VERSION ""

NS_ :

BS_:

BU_: WPC2 PSB SHVU_RR vHS_B2 FCS EMCU SLB GW_APSU GW_DLBCU RCM ARS CGW_CCU vDummy_HS_B GW_RLPSU ATS RLHV SGU PFSU GW_RRPSU ALBCU DSAU SWRC SHVU_FR RCS GW_DPSU BLTN_CAM SCM OHCL RWPC RRHV WPC HOD ASAU

BO_ 905 SBCM_RR_01_200ms: 8 CGW_CCU
 SG_ SBCM_RR_Crc1Val : 0|8@1+ (1,0) [0|0] ""  Vector__XXX
 SG_ RR_CrashUnlockCmd : 10|1@1+ (1,0) [0|0] ""  BLTN_CAM
 SG_ SBCM_RR_AlvCnt1Val : 12|4@1+ (1,0) [0|0] ""  Vector__XXX
 SG_ Warn_RrRtDrSwSta_SBCM : 16|2@1+ (1,0) [0|0] ""  ATS,BLTN_CAM,GW_APSU,GW_RLPSU,GW_RRPSU,RWPC,WPC,WPC2
 SG_ DoorLock_RrRtDrUnLkSta_SBCM : 18|2@1+ (1,0) [0|0] ""  ATS
 SG_ RR_SEAActivated : 20|2@1+ (1,0) [0|0] ""  Vector__XXX
 SG_ RR_SEAWarn : 22|2@1+ (1,0) [0|0] ""  Vector__XXX
 SG_ RR_SEWWarn : 24|2@1+ (1,0) [0|0] ""  Vector__XXX
 SG_ RR_ReleaseWarn : 26|2@1+ (1,0) [0|0] ""  Vector__XXX
 SG_ RR_SWFailAlarm : 28|2@1+ (1,0) [0|0] ""  Vector__XXX
 SG_ RR_ChildLock_ActnFlSta : 30|2@1+ (1,0) [0|0] ""  Vector__XXX
 SG_ RR_MRActivationAlarm : 32|2@1+ (1,0) [0|0] ""  Vector__XXX
 SG_ RR_ChildLock_Status : 34|2@1+ (1,0) [0|0] ""  Vector__XXX
 SG_ USM_RRGhostDoorSta : 36|2@1+ (1,0) [0|0] ""  Vector__XXX
 SG_ DoorLock_PDSLkSwSta_RR : 40|2@1+ (1,0) [0|0] ""  Vector__XXX
 SG_ PDS_TypeOption_RR : 42|2@1+ (1,0) [0|0] ""  Vector__XXX
 SG_ RRDoorPushAlarm : 8|2@1+ (1,0) [0|0] ""  Vector__XXX

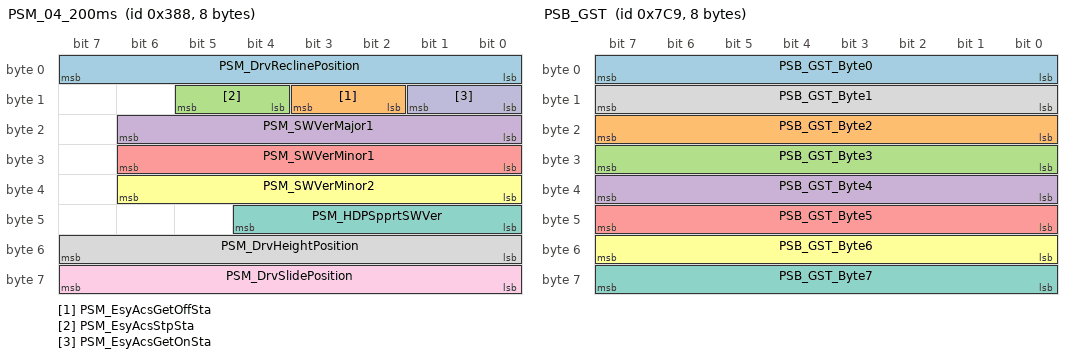
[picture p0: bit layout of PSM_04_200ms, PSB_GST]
BO_ 904 PSM_04_200ms: 8 GW_DPSU
 SG_ PSM_DrvReclinePosition : 0|8@1+ (1,0) [0|0] ""  CGW_CCU,GW_RLPSU,GW_RRPSU
 SG_ PSM_EsyAcsGetOffSta : 10|2@1+ (1,0) [0|0] ""  DSAU,GW_DLBCU,GW_RLPSU,GW_RRPSU
 SG_ PSM_EsyAcsStpSta : 12|2@1+ (1,0) [0|0] ""  DSAU,GW_DLBCU,GW_RLPSU,GW_RRPSU
 SG_ PSM_SWVerMajor1 : 16|7@1+ (1,0) [0|0] ""  CGW_CCU
 SG_ PSM_SWVerMinor1 : 24|7@1+ (1,0) [0|0] ""  CGW_CCU
 SG_ PSM_SWVerMinor2 : 32|7@1+ (1,0) [0|0] ""  CGW_CCU
 SG_ PSM_HDPSpprtSWVer : 40|5@1+ (1,0) [0|0] ""  CGW_CCU
 SG_ PSM_DrvHeightPosition : 48|8@1+ (1,0) [0|0] ""  CGW_CCU,GW_RLPSU,GW_RRPSU
 SG_ PSM_DrvSlidePosition : 56|8@1+ (2,0) [0|0] ""  CGW_CCU,GW_RLPSU,GW_RRPSU
 SG_ PSM_EsyAcsGetOnSta : 8|2@1+ (1,0) [0|0] ""  DSAU,GW_DLBCU,GW_RLPSU,GW_RRPSU

BO_ 903 PSM_03_200ms: 8 GW_DPSU
 SG_ PSM_DrvStSldFwdDis : 0|2@1+ (1,0) [0|0] ""  CGW_CCU
 SG_ PSM_DrvStTiltDnDis : 10|2@1+ (1,0) [0|0] ""  CGW_CCU
 SG_ PSM_DrvStHghtUpDis : 12|2@1+ (1,0) [0|0] ""  CGW_CCU
 SG_ PSM_DrvStHghtDnDis : 14|2@1+ (1,0) [0|0] ""  CGW_CCU
 SG_ PSM_DrvStCushExtBckwdDis : 16|2@1+ (1,0) [0|0] ""  CGW_CCU
 SG_ PSM_DrvStCushExtFwdDis : 18|2@1+ (1,0) [0|0] ""  CGW_CCU
 SG_ PSM_DrvStSldBckwdDis : 2|2@1+ (1,0) [0|0] ""  CGW_CCU
 SG_ PSM_DrvStHdRstUpDis : 20|2@1+ (1,0) [0|0] ""  CGW_CCU
 SG_ PSM_DrvStHdRstDnDis : 22|2@1+ (1,0) [0|0] ""  CGW_CCU
 SG_ PSM_DrvStHdRstFwdDis : 24|2@1+ (1,0) [0|0] ""  CGW_CCU
 SG_ PSM_DrvStHdRstBckwdDis : 26|2@1+ (1,0) [0|0] ""  CGW_CCU
 SG_ PSM_DrvStLmbrDefDis : 32|2@1+ (1,0) [0|0] ""  CGW_CCU
 SG_ PSM_DrvStLmbrLoDis : 34|2@1+ (1,0) [0|0] ""  CGW_CCU
 SG_ PSM_DrvStLmbrMdlDis : 36|2@1+ (1,0) [0|0] ""  CGW_CCU
 SG_ PSM_DrvStLmbrUpDis : 38|2@1+ (1,0) [0|0] ""  CGW_CCU
 SG_ PSM_DrvStReclneFwdDis : 4|2@1+ (1,0) [0|0] ""  CGW_CCU
 SG_ PSM_DrvStBlstrDefDis : 40|2@1+ (1,0) [0|0] ""  CGW_CCU
 SG_ PSM_DrvStBlstrInfDis : 42|2@1+ (1,0) [0|0] ""  CGW_CCU
 SG_ PSM_DrvStReclneBckwdDis : 6|2@1+ (1,0) [0|0] ""  CGW_CCU
 SG_ PSM_DrvStTiltUpDis : 8|2@1+ (1,0) [0|0] ""  CGW_CCU

BO_ 902 PSM_02_200ms: 8 GW_DPSU
 SG_ PSM_DrvStEsyAcsUSMSta : 0|3@1+ (1,0) [0|0] ""  CGW_CCU,DSAU,GW_DLBCU
 SG_ PSM_SeatPosPlyBck_Sta : 10|3@1+ (1,0) [0|0] ""  GW_RLPSU
 SG_ PSM_SeatPos_Sta : 13|3@1+ (1,0) [0|0] ""  GW_RLPSU
 SG_ PSM_SeatPosSldLmt_Sta : 16|2@1+ (1,0) [0|0] ""  CGW_CCU
 SG_ PSM_SeatPosRclnLmt_Sta : 18|2@1+ (1,0) [0|0] ""  CGW_CCU
 SG_ SmrtIMS_StatureRspVal : 24|4@1+ (1,0) [0|0] ""  CGW_CCU
 SG_ SmrtIMS_SeatedHghtRspVal : 28|4@1+ (1,0) [0|0] ""  CGW_CCU
 SG_ Drv_2ndAutoFldEnable : 3|2@1+ (1,0) [0|0] ""  GW_RLPSU,GW_RRPSU
 SG_ SmrtIMS_WghtRspVal : 32|4@1+ (1,0) [0|0] ""  CGW_CCU
 SG_ SmartIMS_DisReq : 36|3@1+ (1,0) [0|0] ""  CGW_CCU
 SG_ SmrtIMS_ExitSta : 40|3@1+ (1,0) [0|0] ""  CGW_CCU
 SG_ PSM_DrvStRlxTiltUpDis : 43|2@1+ (1,0) [0|0] ""  CGW_CCU
 SG_ PSM_DrvStRlxTiltDnDis : 45|2@1+ (1,0) [0|0] ""  CGW_CCU
 SG_ PSM_DrvStLegUpDis : 47|2@1+ (1,0) [0|0] ""  CGW_CCU
 SG_ PSM_DrvStLegDnDis : 49|2@1+ (1,0) [0|0] ""  CGW_CCU
 SG_ Drv_2ndStAutoRlxEnable : 57|2@1+ (1,0) [0|0] ""  GW_RLPSU,GW_RRPSU
 SG_ Drv_AutoRlxSta : 59|2@1+ (1,0) [0|0] ""  CGW_CCU,GW_RLPSU,GW_RRPSU
 SG_ Drv_AutoReturnSta : 61|2@1+ (1,0) [0|0] ""  CGW_CCU
 SG_ PSM_IMSOptTyp : 8|2@1+ (1,0) [0|0] ""  CGW_CCU

BO_ 1993 PSB_GST: 8 PSB
 SG_ PSB_GST_Byte0 : 0|8@1+ (1,0) [0|0] ""  CGW_CCU
 SG_ PSB_GST_Byte2 : 16|8@1+ (1,0) [0|0] ""  CGW_CCU
 SG_ PSB_GST_Byte3 : 24|8@1+ (1,0) [0|0] ""  CGW_CCU
 SG_ PSB_GST_Byte4 : 32|8@1+ (1,0) [0|0] ""  CGW_CCU
 SG_ PSB_GST_Byte5 : 40|8@1+ (1,0) [0|0] ""  CGW_CCU
 SG_ PSB_GST_Byte6 : 48|8@1+ (1,0) [0|0] ""  CGW_CCU
 SG_ PSB_GST_Byte7 : 56|8@1+ (1,0) [0|0] ""  CGW_CCU
 SG_ PSB_GST_Byte1 : 8|8@1+ (1,0) [0|0] ""  CGW_CCU

BO_ 1016 HU_GNSS_14_1000ms: 8 CGW_CCU
 SG_ GNSS_MM_type : 0|4@1+ (1,0) [0|0] ""  BLTN_CAM

BO_ 1019 HU_MOOD_E_01: 8 CGW_CCU
 SG_ HU_MoodTherapyDrSeat : 0|2@1+ (1,0) [0|0] ""  DSAU,GW_DLBCU
 SG_ HU_VitalityFragrance : 10|2@1+ (1,0) [0|0] ""  Vector__XXX
 SG_ HU_VitalityCurtain : 12|2@1+ (1,0) [0|0] ""  Vector__XXX
 SG_ HU_DelightMoodLamp : 14|2@1+ (1,0) [0|0] ""  Vector__XXX
 SG_ HU_DelightFragrance : 16|2@1+ (1,0) [0|0] ""  Vector__XXX
 SG_ HU_DelightCurtain : 18|2@1+ (1,0) [0|0] ""  Vector__XXX
 SG_ HU_MoodTherapyPsSeat : 2|2@1+ (1,0) [0|0] ""  ALBCU,ASAU
 SG_ HU_CareMoodLamp : 20|2@1+ (1,0) [0|0] ""  Vector__XXX
 SG_ HU_CareFragrance : 22|2@1+ (1,0) [0|0] ""  Vector__XXX
 SG_ HU_CareMassage : 24|2@1+ (1,0) [0|0] ""  ALBCU,ASAU,DSAU,GW_DLBCU
 SG_ HU_CareCurtain : 26|2@1+ (1,0) [0|0] ""  Vector__XXX
 SG_ HU_ComfortMoodLamp : 28|2@1+ (1,0) [0|0] ""  Vector__XXX
 SG_ HU_ComfortFragrance : 30|2@1+ (1,0) [0|0] ""  Vector__XXX
 SG_ HU_ComfortMassage : 32|2@1+ (1,0) [0|0] ""  ALBCU,ASAU,DSAU,GW_DLBCU
 SG_ HU_ComfortCurtain : 34|2@1+ (1,0) [0|0] ""  Vector__XXX
 SG_ HU_MoodTherapyMode : 36|3@1+ (1,0) [0|0] ""  ALBCU,ASAU,DSAU,GW_DLBCU
 SG_ HU_MoodTherapyRlSeat : 4|2@1+ (1,0) [0|0] ""  Vector__XXX
 SG_ HU_MoodTherapyRrSeat : 6|2@1+ (1,0) [0|0] ""  Vector__XXX
 SG_ HU_VitalityMoodLamp : 8|2@1+ (1,0) [0|0] ""  Vector__XXX

BO_ 2235651330 APSB_01_10ms_2: 8 CGW_CCU

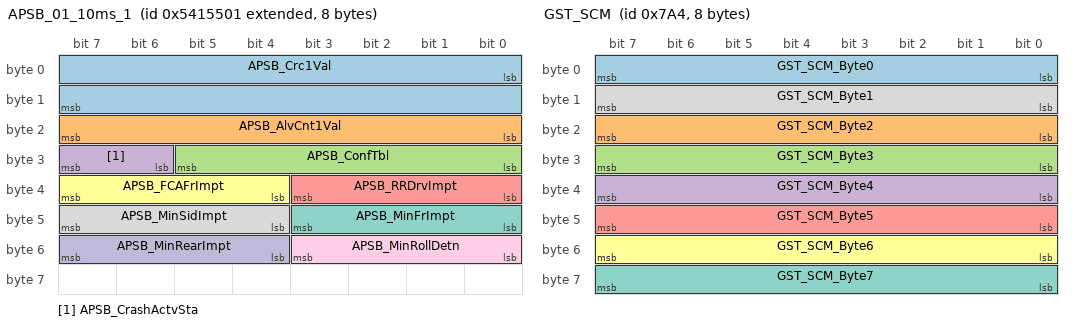
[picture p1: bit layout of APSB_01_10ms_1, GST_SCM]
BO_ 2235651329 APSB_01_10ms_1: 8 CGW_CCU
 SG_ APSB_Crc1Val : 0|16@1+ (1,0) [0|0] ""  Vector__XXX
 SG_ APSB_AlvCnt1Val : 16|8@1+ (1,0) [0|0] ""  Vector__XXX
 SG_ APSB_ConfTbl : 24|6@1+ (1,0) [0|0] ""  PSB
 SG_ APSB_CrashActvSta : 30|2@1+ (1,0) [0|0] ""  PSB
 SG_ APSB_RRDrvImpt : 32|4@1+ (1,0) [0|0] ""  PSB
 SG_ APSB_FCAFrImpt : 36|4@1+ (1,0) [0|0] ""  PSB
 SG_ APSB_MinFrImpt : 40|4@1+ (1,0) [0|0] ""  PSB
 SG_ APSB_MinSidImpt : 44|4@1+ (1,0) [0|0] ""  PSB
 SG_ APSB_MinRollDetn : 48|4@1+ (1,0) [0|0] ""  PSB
 SG_ APSB_MinRearImpt : 52|4@1+ (1,0) [0|0] ""  PSB

BO_ 1015 HU_GNSS_13_1000ms: 8 CGW_CCU
 SG_ HU_MM_Altitude : 0|32@1- (0.01,0) [0|0] "m"  BLTN_CAM
 SG_ HU_MM_Heading : 32|32@1+ (1,0) [0|0] "¢ª"  BLTN_CAM

BO_ 1956 GST_SCM: 8 CGW_CCU
 SG_ GST_SCM_Byte0 : 0|8@1+ (1,0) [0|0] ""  SCM
 SG_ GST_SCM_Byte2 : 16|8@1+ (1,0) [0|0] ""  SCM
 SG_ GST_SCM_Byte3 : 24|8@1+ (1,0) [0|0] ""  SCM
 SG_ GST_SCM_Byte4 : 32|8@1+ (1,0) [0|0] ""  SCM
 SG_ GST_SCM_Byte5 : 40|8@1+ (1,0) [0|0] ""  SCM
 SG_ GST_SCM_Byte6 : 48|8@1+ (1,0) [0|0] ""  SCM
 SG_ GST_SCM_Byte7 : 56|8@1+ (1,0) [0|0] ""  SCM
 SG_ GST_SCM_Byte1 : 8|8@1+ (1,0) [0|0] ""  SCM

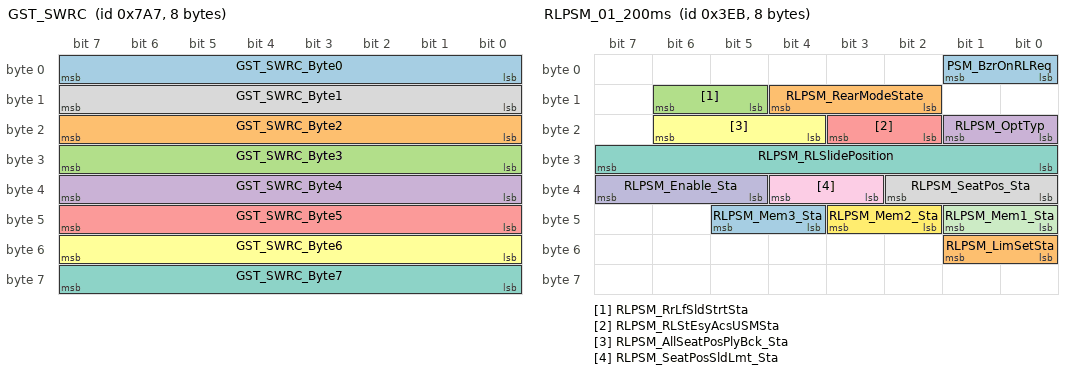
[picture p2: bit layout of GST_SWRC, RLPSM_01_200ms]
BO_ 1959 GST_SWRC: 8 CGW_CCU
 SG_ GST_SWRC_Byte0 : 0|8@1+ (1,0) [0|0] ""  SWRC
 SG_ GST_SWRC_Byte2 : 16|8@1+ (1,0) [0|0] ""  SWRC
 SG_ GST_SWRC_Byte3 : 24|8@1+ (1,0) [0|0] ""  SWRC
 SG_ GST_SWRC_Byte4 : 32|8@1+ (1,0) [0|0] ""  SWRC
 SG_ GST_SWRC_Byte5 : 40|8@1+ (1,0) [0|0] ""  SWRC
 SG_ GST_SWRC_Byte6 : 48|8@1+ (1,0) [0|0] ""  SWRC
 SG_ GST_SWRC_Byte7 : 56|8@1+ (1,0) [0|0] ""  SWRC
 SG_ GST_SWRC_Byte1 : 8|8@1+ (1,0) [0|0] ""  SWRC

BO_ 1003 RLPSM_01_200ms: 8 GW_RRPSU
 SG_ PSM_BzrOnRLReq : 0|2@1+ (1,0) [0|0] ""  ATS,GW_DPSU
 SG_ RLPSM_RearModeState : 10|3@1+ (1,0) [0|0] ""  ATS,CGW_CCU,GW_APSU,GW_DPSU,OHCL
 SG_ RLPSM_RrLfSldStrtSta : 13|2@1+ (1,0) [0|0] ""  ARS,GW_APSU,GW_DPSU,GW_RRPSU
 SG_ RLPSM_OptTyp : 16|2@1+ (1,0) [0|0] ""  CGW_CCU
 SG_ RLPSM_RLStEsyAcsUSMSta : 18|2@1+ (1,0) [0|0] ""  ATS,CGW_CCU,GW_DLBCU
 SG_ RLPSM_AllSeatPosPlyBck_Sta : 20|3@1+ (1,0) [0|0] ""  CGW_CCU
 SG_ RLPSM_RLSlidePosition : 24|8@1+ (2,0) [0|0] ""  GW_APSU,GW_DPSU,GW_RLPSU,GW_RRPSU
 SG_ RLPSM_SeatPos_Sta : 32|3@1+ (1,0) [0|0] ""  CGW_CCU,GW_RRPSU
 SG_ RLPSM_SeatPosSldLmt_Sta : 35|2@1+ (1,0) [0|0] ""  CGW_CCU
 SG_ RLPSM_Enable_Sta : 37|3@1+ (1,0) [0|0] ""  CGW_CCU
 SG_ RLPSM_Mem1_Sta : 40|2@1+ (1,0) [0|0] ""  CGW_CCU
 SG_ RLPSM_Mem2_Sta : 42|2@1+ (1,0) [0|0] ""  CGW_CCU
 SG_ RLPSM_Mem3_Sta : 44|2@1+ (1,0) [0|0] ""  CGW_CCU
 SG_ RLPSM_LimSetSta : 48|2@1+ (1,0) [0|0] ""  Vector__XXX

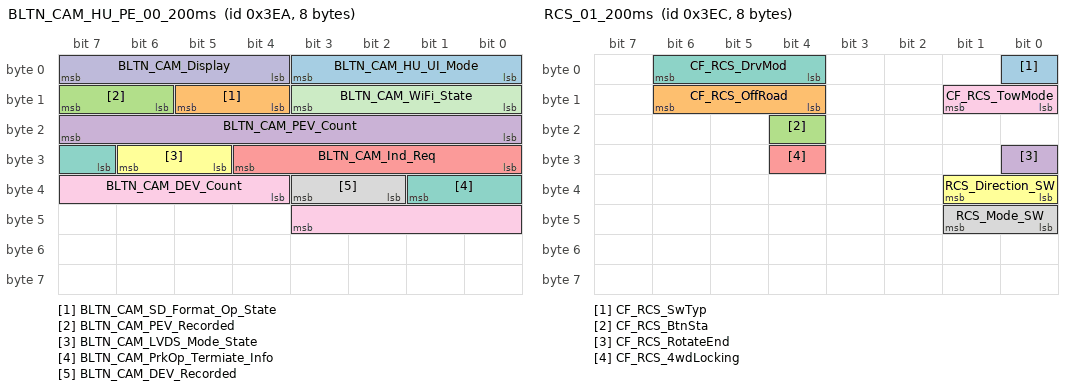
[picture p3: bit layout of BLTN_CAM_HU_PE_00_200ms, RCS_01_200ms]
BO_ 1002 BLTN_CAM_HU_PE_00_200ms: 8 BLTN_CAM
 SG_ BLTN_CAM_HU_UI_Mode : 0|4@1+ (1,0) [0|0] ""  CGW_CCU
 SG_ BLTN_CAM_SD_Format_Op_State : 12|2@1+ (1,0) [0|0] ""  CGW_CCU
 SG_ BLTN_CAM_PEV_Recorded : 14|2@1+ (1,0) [0|0] ""  CGW_CCU
 SG_ BLTN_CAM_PEV_Count : 16|8@1+ (1,0) [0|0] ""  CGW_CCU
 SG_ BLTN_CAM_Ind_Req : 24|5@1+ (1,0) [0|0] ""  CGW_CCU
 SG_ BLTN_CAM_LVDS_Mode_State : 29|2@1+ (1,0) [0|0] ""  CGW_CCU
 SG_ BLTN_CAM_PrkOp_Termiate_Info : 31|3@1+ (1,0) [0|0] ""  CGW_CCU
 SG_ BLTN_CAM_DEV_Recorded : 34|2@1+ (1,0) [0|0] ""  CGW_CCU
 SG_ BLTN_CAM_DEV_Count : 36|8@1+ (1,0) [0|0] ""  CGW_CCU
 SG_ BLTN_CAM_Display : 4|4@1+ (1,0) [0|0] ""  CGW_CCU
 SG_ BLTN_CAM_WiFi_State : 8|4@1+ (1,0) [0|0] ""  CGW_CCU

BO_ 1005 RLPSU_01_200ms: 8 GW_RLPSU
 SG_ RLPSU_FldDis : 0|2@1+ (1,0) [0|0] ""  CGW_CCU
 SG_ RLPSU_TiltDownDis : 10|2@1+ (1,0) [0|0] ""  CGW_CCU
 SG_ RLPSU_RclFwdDis : 12|2@1+ (1,0) [0|0] ""  CGW_CCU
 SG_ RLPSU_RclBwdDis : 14|2@1+ (1,0) [0|0] ""  CGW_CCU
 SG_ RLPSU_RlxModeDis : 16|2@1+ (1,0) [0|0] ""  Vector__XXX
 SG_ RLPSU_Folding_SW : 18|2@1+ (1,0) [0|0] ""  Vector__XXX
 SG_ RLPSU_UnFldDis : 2|2@1+ (1,0) [0|0] ""  Vector__XXX
 SG_ RLPSU_Unfolding_SW : 20|2@1+ (1,0) [0|0] ""  Vector__XXX
 SG_ RLPSU_WalkIn_SW : 22|2@1+ (1,0) [0|0] ""  Vector__XXX
 SG_ RLPSU_UnwalkIn_SW : 24|2@1+ (1,0) [0|0] ""  Vector__XXX
 SG_ RLPSU_Folding_Postion : 26|4@1+ (1,0) [0|0] ""  CGW_CCU,GW_RLPSU
 SG_ RLPSU_Folding_State_PopUp : 30|3@1+ (1,0) [0|0] ""  Vector__XXX
 SG_ RLPSU_Relax_State_Popup : 33|3@1+ (1,0) [0|0] ""  Vector__XXX
 SG_ RLPSU_SlideFwdDis : 36|2@1+ (1,0) [0|0] ""  CGW_CCU
 SG_ RLPSU_SlideBwdDis : 38|2@1+ (1,0) [0|0] ""  CGW_CCU
 SG_ RLPSU_WalkInDis : 4|2@1+ (1,0) [0|0] ""  Vector__XXX
 SG_ RLPSU_WalkInState : 40|2@1+ (1,0) [0|0] ""  GW_APSU,GW_DPSU
 SG_ RLPSU_RLMsgEnable : 42|2@1+ (1,0) [0|0] ""  Vector__XXX
 SG_ RLPSU_UnWalkInDis : 6|2@1+ (1,0) [0|0] ""  Vector__XXX
 SG_ RLPSU_TiltUpDis : 8|2@1+ (1,0) [0|0] ""  CGW_CCU

BO_ 1004 RCS_01_200ms: 8 RCS
 SG_ CF_RCS_SwTyp : 0|1@1+ (1,0) [0|0] "Watt"  CGW_CCU
 SG_ CF_RCS_OffRoad : 12|3@1+ (1,0) [0|0] "Watt"  CGW_CCU
 SG_ CF_RCS_BtnSta : 20|1@1+ (1,0) [0|0] "Watt"  CGW_CCU
 SG_ CF_RCS_RotateEnd : 24|1@1+ (1,0) [0|0] "Watt"  CGW_CCU
 SG_ CF_RCS_4wdLocking : 28|1@1+ (1,0) [0|0] "Watt"  CGW_CCU
 SG_ RCS_Direction_SW : 32|2@1+ (1,0) [0|0] ""  CGW_CCU
 SG_ CF_RCS_DrvMod : 4|3@1+ (1,0) [0|0] "Watt"  CGW_CCU
 SG_ RCS_Mode_SW : 40|2@1+ (1,0) [0|0] ""  CGW_CCU
 SG_ CF_RCS_TowMode : 8|2@1+ (1,0) [0|0] ""  CGW_CCU

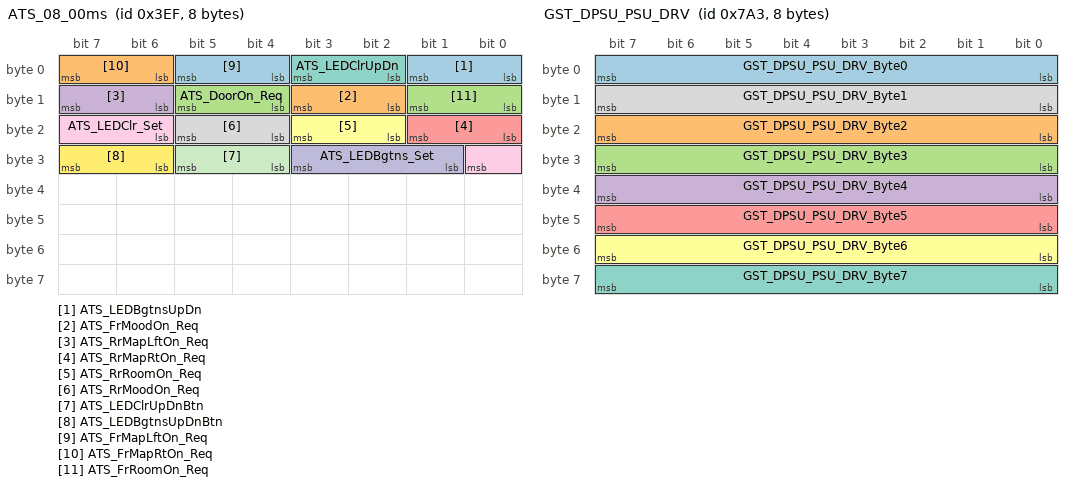
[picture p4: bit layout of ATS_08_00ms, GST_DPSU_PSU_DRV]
BO_ 1007 ATS_08_00ms: 8 ATS
 SG_ ATS_LEDBgtnsUpDn : 0|2@1+ (1,0) [0|0] ""  OHCL
 SG_ ATS_FrMoodOn_Req : 10|2@1+ (1,0) [0|0] ""  OHCL
 SG_ ATS_DoorOn_Req : 12|2@1+ (1,0) [0|0] ""  OHCL
 SG_ ATS_RrMapLftOn_Req : 14|2@1+ (1,0) [0|0] ""  OHCL
 SG_ ATS_RrMapRtOn_Req : 16|2@1+ (1,0) [0|0] ""  OHCL
 SG_ ATS_RrRoomOn_Req : 18|2@1+ (1,0) [0|0] ""  OHCL
 SG_ ATS_LEDClrUpDn : 2|2@1+ (1,0) [0|0] ""  OHCL
 SG_ ATS_RrMoodOn_Req : 20|2@1+ (1,0) [0|0] ""  OHCL
 SG_ ATS_LEDClr_Set : 22|3@1+ (1,0) [0|0] ""  OHCL
 SG_ ATS_LEDBgtns_Set : 25|3@1+ (1,0) [0|0] ""  OHCL
 SG_ ATS_LEDClrUpDnBtn : 28|2@1+ (1,0) [0|0] ""  Vector__XXX
 SG_ ATS_LEDBgtnsUpDnBtn : 30|2@1+ (1,0) [0|0] ""  Vector__XXX
 SG_ ATS_FrMapLftOn_Req : 4|2@1+ (1,0) [0|0] ""  OHCL
 SG_ ATS_FrMapRtOn_Req : 6|2@1+ (1,0) [0|0] ""  OHCL
 SG_ ATS_FrRoomOn_Req : 8|2@1+ (1,0) [0|0] ""  OHCL

BO_ 1955 GST_DPSU_PSU_DRV: 8 CGW_CCU
 SG_ GST_DPSU_PSU_DRV_Byte0 : 0|8@1+ (1,0) [0|0] ""  GW_DPSU
 SG_ GST_DPSU_PSU_DRV_Byte2 : 16|8@1+ (1,0) [0|0] ""  GW_DPSU
 SG_ GST_DPSU_PSU_DRV_Byte3 : 24|8@1+ (1,0) [0|0] ""  GW_DPSU
 SG_ GST_DPSU_PSU_DRV_Byte4 : 32|8@1+ (1,0) [0|0] ""  GW_DPSU
 SG_ GST_DPSU_PSU_DRV_Byte5 : 40|8@1+ (1,0) [0|0] ""  GW_DPSU
 SG_ GST_DPSU_PSU_DRV_Byte6 : 48|8@1+ (1,0) [0|0] ""  GW_DPSU
 SG_ GST_DPSU_PSU_DRV_Byte7 : 56|8@1+ (1,0) [0|0] ""  GW_DPSU
 SG_ GST_DPSU_PSU_DRV_Byte1 : 8|8@1+ (1,0) [0|0] ""  GW_DPSU

BO_ 1006 RRPSU_01_200ms: 8 GW_RRPSU
 SG_ RRPSU_FldDis : 0|2@1+ (1,0) [0|0] ""  CGW_CCU
 SG_ RRPSU_TiltDnDis : 10|2@1+ (1,0) [0|0] ""  CGW_CCU
 SG_ RRPSU_RecFwdDis : 12|2@1+ (1,0) [0|0] ""  CGW_CCU
 SG_ RRPSU_RecBwdDis : 14|2@1+ (1,0) [0|0] ""  CGW_CCU
 SG_ RRPSU_RlxModeDis : 16|2@1+ (1,0) [0|0] ""  Vector__XXX
 SG_ RRPSU_Folding_SW : 18|2@1+ (1,0) [0|0] ""  Vector__XXX
 SG_ RRPSU_UnFldDis : 2|2@1+ (1,0) [0|0] ""  Vector__XXX
 SG_ RRPSU_Unfolding_SW : 20|2@1+ (1,0) [0|0] ""  Vector__XXX
 SG_ RRPSU_WalkIn_SW : 22|2@1+ (1,0) [0|0] ""  Vector__XXX
 SG_ RRPSU_UnwalkIn_SW : 24|2@1+ (1,0) [0|0] ""  Vector__XXX
 SG_ RRPSU_Folding_Postion : 26|4@1+ (1,0) [0|0] ""  CGW_CCU
 SG_ RRPSU_Folding_State_Popup : 30|3@1+ (1,0) [0|0] ""  Vector__XXX
 SG_ RRPSU_Relax_State_Popup : 33|3@1+ (1,0) [0|0] ""  Vector__XXX
 SG_ RRPSU_SlideFwdDis : 36|2@1+ (1,0) [0|0] ""  CGW_CCU
 SG_ RRPSU_SlideBwdDis : 38|2@1+ (1,0) [0|0] ""  CGW_CCU
 SG_ RRPSU_WalkinDis : 4|2@1+ (1,0) [0|0] ""  Vector__XXX
 SG_ RRPSU_WalkInState : 40|2@1+ (1,0) [0|0] ""  GW_APSU,GW_DPSU
 SG_ RRPSU_RRMsgEnable : 42|2@1+ (1,0) [0|0] ""  Vector__XXX
 SG_ RRPSU_UnwalkinDis : 6|2@1+ (1,0) [0|0] ""  Vector__XXX
 SG_ RRPSU_TiltUpDis : 8|2@1+ (1,0) [0|0] ""  CGW_CCU

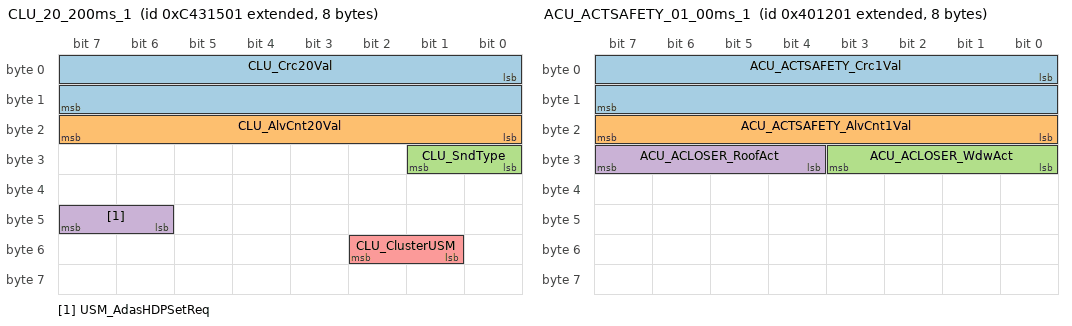
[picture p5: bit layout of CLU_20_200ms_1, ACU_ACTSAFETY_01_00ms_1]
BO_ 2353206529 CLU_20_200ms_1: 8 CGW_CCU
 SG_ CLU_Crc20Val : 0|16@1+ (1,0) [0|0] ""  Vector__XXX
 SG_ CLU_AlvCnt20Val : 16|8@1+ (1,0) [0|0] ""  Vector__XXX
 SG_ CLU_SndType : 24|2@1- (1,0) [0|0] ""  Vector__XXX
 SG_ USM_AdasHDPSetReq : 46|2@1+ (1,0) [0|0] ""  Vector__XXX
 SG_ CLU_ClusterUSM : 49|2@1+ (1,0) [0|0] ""  WPC,WPC2

BO_ 2151682561 ACU_ACTSAFETY_01_00ms_1: 8 CGW_CCU
 SG_ ACU_ACTSAFETY_Crc1Val : 0|16@1+ (1,0) [0|0] ""  RCM
 SG_ ACU_ACTSAFETY_AlvCnt1Val : 16|8@1+ (1,0) [0|0] ""  RCM
 SG_ ACU_ACLOSER_WdwAct : 24|4@1+ (1,0) [0|0] ""  RCM
 SG_ ACU_ACLOSER_RoofAct : 28|4@1+ (1,0) [0|0] ""  RCM

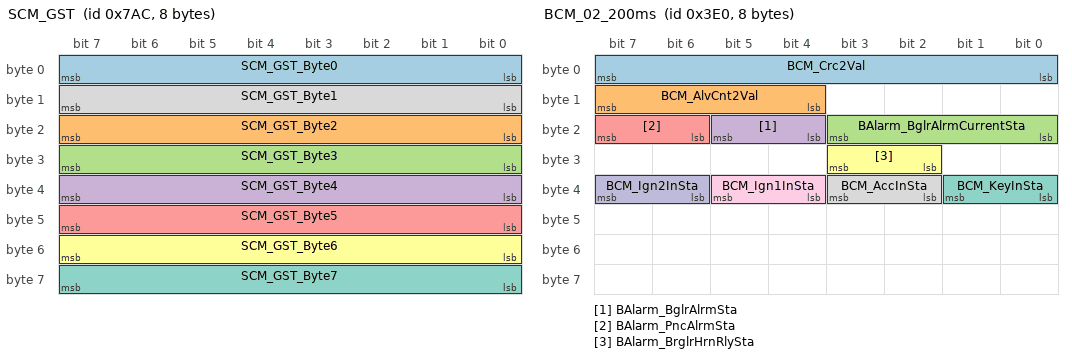
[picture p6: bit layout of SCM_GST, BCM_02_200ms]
BO_ 1964 SCM_GST: 8 SCM
 SG_ SCM_GST_Byte0 : 0|8@1+ (1,0) [0|0] ""  CGW_CCU
 SG_ SCM_GST_Byte2 : 16|8@1+ (1,0) [0|0] ""  CGW_CCU
 SG_ SCM_GST_Byte3 : 24|8@1+ (1,0) [0|0] ""  CGW_CCU
 SG_ SCM_GST_Byte4 : 32|8@1+ (1,0) [0|0] ""  CGW_CCU
 SG_ SCM_GST_Byte5 : 40|8@1+ (1,0) [0|0] ""  CGW_CCU
 SG_ SCM_GST_Byte6 : 48|8@1+ (1,0) [0|0] ""  CGW_CCU
 SG_ SCM_GST_Byte7 : 56|8@1+ (1,0) [0|0] ""  CGW_CCU
 SG_ SCM_GST_Byte1 : 8|8@1+ (1,0) [0|0] ""  CGW_CCU

BO_ 992 BCM_02_200ms: 8 CGW_CCU
 SG_ BCM_Crc2Val : 0|8@1+ (1,0) [0|0] ""  Vector__XXX
 SG_ BCM_AlvCnt2Val : 12|4@1+ (1,0) [0|0] ""  Vector__XXX
 SG_ BAlarm_BglrAlrmCurrentSta : 16|4@1+ (1,0) [0|0] ""  BLTN_CAM
 SG_ BAlarm_BglrAlrmSta : 20|2@1+ (1,0) [0|0] ""  Vector__XXX
 SG_ BAlarm_PncAlrmSta : 22|2@1+ (1,0) [0|0] ""  Vector__XXX
 SG_ BAlarm_BrglrHrnRlySta : 26|2@1+ (1,0) [0|0] ""  Vector__XXX
 SG_ BCM_KeyInSta : 32|2@1+ (1,0) [0|0] ""  ALBCU,ARS,GW_APSU,GW_DLBCU,GW_DPSU,GW_RLPSU,GW_RRPSU,PFSU,RLHV,RRHV,SGU,SHVU_FR,SHVU_RR,SWRC
 SG_ BCM_AccInSta : 34|2@1+ (1,0) [0|0] ""  ALBCU,ARS,ASAU,ATS,DSAU,GW_APSU,GW_DLBCU,GW_DPSU,GW_RLPSU,GW_RRPSU,PFSU,RLHV,RRHV,SCM,SGU,SHVU_FR,SHVU_RR,SWRC,WPC2
 SG_ BCM_Ign1InSta : 36|2@1+ (1,0) [0|0] ""  ALBCU,ARS,ASAU,ATS,DSAU,GW_APSU,GW_DLBCU,GW_DPSU,GW_RLPSU,GW_RRPSU,HOD,PFSU,RCM,RLHV,RRHV,SCM,SGU,SHVU_FR,SHVU_RR,SWRC
 SG_ BCM_Ign2InSta : 38|2@1+ (1,0) [0|0] ""  ALBCU,ARS,ASAU,ATS,DSAU,FCS,GW_APSU,GW_DLBCU,GW_DPSU,GW_RLPSU,GW_RRPSU,PFSU,RCM,RLHV,RRHV,SCM,SGU,SHVU_FR,SHVU_RR,SWRC

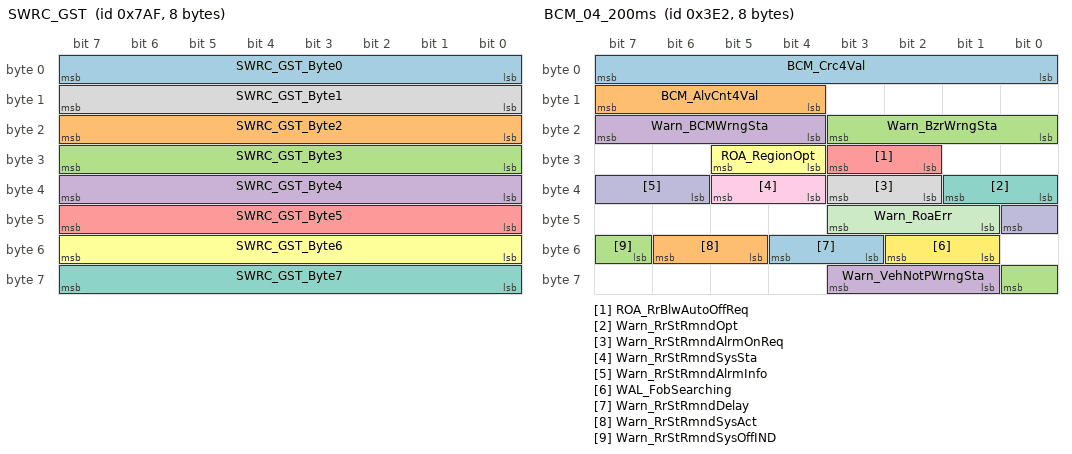
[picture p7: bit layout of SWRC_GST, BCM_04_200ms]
BO_ 1967 SWRC_GST: 8 SWRC
 SG_ SWRC_GST_Byte0 : 0|8@1+ (1,0) [0|0] ""  CGW_CCU
 SG_ SWRC_GST_Byte2 : 16|8@1+ (1,0) [0|0] ""  CGW_CCU
 SG_ SWRC_GST_Byte3 : 24|8@1+ (1,0) [0|0] ""  CGW_CCU
 SG_ SWRC_GST_Byte4 : 32|8@1+ (1,0) [0|0] ""  CGW_CCU
 SG_ SWRC_GST_Byte5 : 40|8@1+ (1,0) [0|0] ""  CGW_CCU
 SG_ SWRC_GST_Byte6 : 48|8@1+ (1,0) [0|0] ""  CGW_CCU
 SG_ SWRC_GST_Byte7 : 56|8@1+ (1,0) [0|0] ""  CGW_CCU
 SG_ SWRC_GST_Byte1 : 8|8@1+ (1,0) [0|0] ""  CGW_CCU

BO_ 2353206530 CLU_20_200ms_2: 8 CGW_CCU

BO_ 2151682562 ACU_ACTSAFETY_01_00ms_2: 8 CGW_CCU

BO_ 994 BCM_04_200ms: 8 CGW_CCU
 SG_ BCM_Crc4Val : 0|8@1+ (1,0) [0|0] ""  Vector__XXX
 SG_ BCM_AlvCnt4Val : 12|4@1+ (1,0) [0|0] ""  Vector__XXX
 SG_ Warn_BzrWrngSta : 16|4@1+ (1,0) [0|0] ""  Vector__XXX
 SG_ Warn_BCMWrngSta : 20|4@1+ (1,0) [0|0] ""  Vector__XXX
 SG_ ROA_RrBlwAutoOffReq : 26|2@1+ (1,0) [0|0] ""  Vector__XXX
 SG_ ROA_RegionOpt : 28|2@1+ (1,0) [0|0] ""  Vector__XXX
 SG_ Warn_RrStRmndOpt : 32|2@1+ (1,0) [0|0] ""  Vector__XXX
 SG_ Warn_RrStRmndAlrmOnReq : 34|2@1+ (1,0) [0|0] ""  Vector__XXX
 SG_ Warn_RrStRmndSysSta : 36|2@1+ (1,0) [0|0] ""  Vector__XXX
 SG_ Warn_RrStRmndAlrmInfo : 38|3@1+ (1,0) [0|0] ""  SWRC
 SG_ Warn_RoaErr : 41|3@1+ (1,0) [0|0] ""  Vector__XXX
 SG_ WAL_FobSearching : 49|2@1+ (1,0) [0|0] ""  Vector__XXX
 SG_ Warn_RrStRmndDelay : 51|2@1+ (1,0) [0|0] ""  Vector__XXX
 SG_ Warn_RrStRmndSysAct : 53|2@1+ (1,0) [0|0] ""  Vector__XXX
 SG_ Warn_RrStRmndSysOffIND : 55|2@1+ (1,0) [0|0] ""  Vector__XXX
 SG_ Warn_VehNotPWrngSta : 57|3@1+ (1,0) [0|0] ""  Vector__XXX

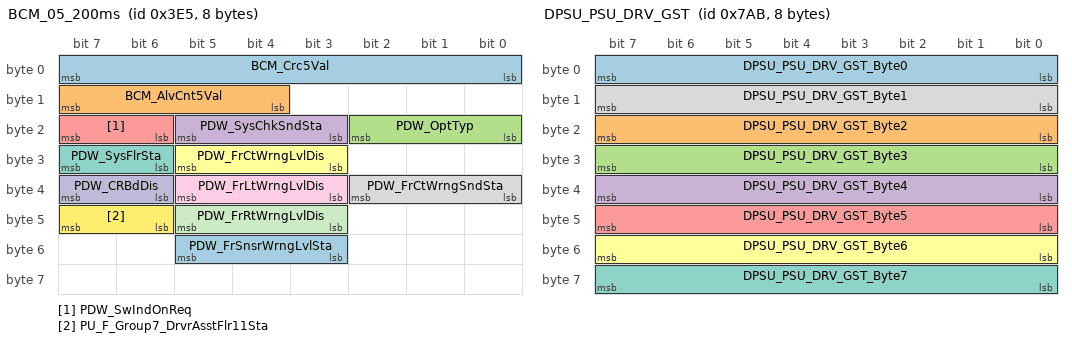
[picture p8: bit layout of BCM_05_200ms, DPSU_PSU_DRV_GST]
BO_ 997 BCM_05_200ms: 8 CGW_CCU
 SG_ BCM_Crc5Val : 0|8@1+ (1,0) [0|0] ""  Vector__XXX
 SG_ BCM_AlvCnt5Val : 12|4@1+ (1,0) [0|0] ""  Vector__XXX
 SG_ PDW_OptTyp : 16|3@1+ (1,0) [0|0] ""  Vector__XXX
 SG_ PDW_SysChkSndSta : 19|3@1+ (1,0) [0|0] ""  Vector__XXX
 SG_ PDW_SwIndOnReq : 22|2@1+ (1,0) [0|0] ""  FCS
 SG_ PDW_FrCtWrngLvlDis : 27|3@1+ (1,0) [0|0] ""  Vector__XXX
 SG_ PDW_SysFlrSta : 30|2@1+ (1,0) [0|0] ""  Vector__XXX
 SG_ PDW_FrCtWrngSndSta : 32|3@1+ (1,0) [0|0] ""  Vector__XXX
 SG_ PDW_FrLtWrngLvlDis : 35|3@1+ (1,0) [0|0] ""  Vector__XXX
 SG_ PDW_CRBdDis : 38|2@1+ (1,0) [0|0] ""  Vector__XXX
 SG_ PDW_FrRtWrngLvlDis : 43|3@1+ (1,0) [0|0] ""  Vector__XXX
 SG_ PU_F_Group7_DrvrAsstFlr11Sta : 46|2@1+ (1,0) [0|0] ""  Vector__XXX
 SG_ PDW_FrSnsrWrngLvlSta : 51|3@1+ (1,0) [0|0] ""  Vector__XXX

BO_ 1963 DPSU_PSU_DRV_GST: 8 GW_DPSU
 SG_ DPSU_PSU_DRV_GST_Byte0 : 0|8@1+ (1,0) [0|0] ""  CGW_CCU
 SG_ DPSU_PSU_DRV_GST_Byte2 : 16|8@1+ (1,0) [0|0] ""  CGW_CCU
 SG_ DPSU_PSU_DRV_GST_Byte3 : 24|8@1+ (1,0) [0|0] ""  CGW_CCU
 SG_ DPSU_PSU_DRV_GST_Byte4 : 32|8@1+ (1,0) [0|0] ""  CGW_CCU
 SG_ DPSU_PSU_DRV_GST_Byte5 : 40|8@1+ (1,0) [0|0] ""  CGW_CCU
 SG_ DPSU_PSU_DRV_GST_Byte6 : 48|8@1+ (1,0) [0|0] ""  CGW_CCU
 SG_ DPSU_PSU_DRV_GST_Byte7 : 56|8@1+ (1,0) [0|0] ""  CGW_CCU
 SG_ DPSU_PSU_DRV_GST_Byte1 : 8|8@1+ (1,0) [0|0] ""  CGW_CCU

BO_TX_BU_ 1003 : GW_RRPSU,GW_RLPSU;
BO_TX_BU_ 1005 : GW_RLPSU,GW_RRPSU;
CM_ BO_ 2151682561 "[EW] On Event and On Write";
CM_ SG_ 2151682561 ACU_ACTSAFETY_Crc1Val "ACU_ACTSAFETY_CyclicRedundancyCheck1Value";
CM_ SG_ 2151682561 ACU_ACTSAFETY_AlvCnt1Val "ACU_ACTSAFETY_AliveCounter1Value";
CM_ SG_ 2151682561 ACU_ACLOSER_WdwAct "ACU_ACLOSER_WindowActivation";
CM_ SG_ 2151682561 ACU_ACLOSER_RoofAct "ACU_ACLOSER_RoofActivation";
CM_ BO_ 2151682562 "[EW] On Event and On Write";
CM_ BO_ 2235651329 "[P] Periodic";
CM_ SG_ 2235651329 APSB_Crc1Val "APSB_CyclicRedundancyCheck1Value";
CM_ SG_ 2235651329 APSB_AlvCnt1Val "APSB_AliveCounter1Value";
CM_ SG_ 2235651329 APSB_ConfTbl "APSB_ConfigurationTable";
CM_ SG_ 2235651329 APSB_CrashActvSta "APSB_CrashActiveStatus";
CM_ SG_ 2235651329 APSB_RRDrvImpt "APSB RoughRoadDrvingImpact";
CM_ SG_ 2235651329 APSB_FCAFrImpt "APSB FCAFrontImpact";
CM_ SG_ 2235651329 APSB_MinFrImpt "APSB MinorFrontImpact";
CM_ SG_ 2235651329 APSB_MinSidImpt "APSB MinorSideImpact";
CM_ SG_ 2235651329 APSB_MinRollDetn "APSB MinorRollDetection";
CM_ SG_ 2235651329 APSB_MinRearImpt "APSB MinorRearImpact";
CM_ BO_ 2235651330 "[P] Periodic";
CM_ BO_ 1007 "[EC] On Event and On Change";
CM_ SG_ 1007 ATS_LEDBgtnsUpDn "Interior Light Brightness Up/Down Request";
CM_ SG_ 1007 ATS_FrMoodOn_Req "Front mood lamp On/Off request";
CM_ SG_ 1007 ATS_DoorOn_Req "Front Door switch On/Off request";
CM_ SG_ 1007 ATS_RrMapLftOn_Req "Rear left map lamp On/Off request";
CM_ SG_ 1007 ATS_RrMapRtOn_Req "Rear right map lamp On/Off request";
CM_ SG_ 1007 ATS_RrRoomOn_Req "Rear room lamp On/Off request";
CM_ SG_ 1007 ATS_LEDClrUpDn "Interior Light Color Up/Down Request";
CM_ SG_ 1007 ATS_RrMoodOn_Req "Rear mood lamp On/Off request";
CM_ SG_ 1007 ATS_LEDClr_Set "Interior Lamp LED Color Request";
CM_ SG_ 1007 ATS_LEDBgtns_Set "Interior Lamp LED Brightness Request";
CM_ SG_ 1007 ATS_LEDClrUpDnBtn "Interior Light Color Up/Down Request";
CM_ SG_ 1007 ATS_LEDBgtnsUpDnBtn "Interior Light Brightness Up/Down Request";
CM_ SG_ 1007 ATS_FrMapLftOn_Req "Front left map lamp On/Off request";
CM_ SG_ 1007 ATS_FrMapRtOn_Req "Front right map lamp On/Off request";
CM_ SG_ 1007 ATS_FrRoomOn_Req "Front room lamp On/Off request";
CM_ BO_ 992 "[PE] Periodic and On Event";
CM_ SG_ 992 BCM_Crc2Val "BCM_CyclicRedundancyCheck2Value";
CM_ SG_ 992 BCM_AlvCnt2Val "BCM_AliveCounter2Value";
CM_ SG_ 992 BAlarm_BglrAlrmCurrentSta "BAlarm_BuglarAlarmCurrentStatus ##2G##BCM - BCMmsg17 - C_BAlarmState";
CM_ SG_ 992 BAlarm_BglrAlrmSta "BAlarm_BuglarAlarmStatus ##2G##BCM - BCMmsg17 - C_BAState";
CM_ SG_ 992 BAlarm_PncAlrmSta "BAlarm_PanicAlarmStatus ##2G##BCM - BCMmsg17 - C_PanicState";
CM_ SG_ 992 BAlarm_BrglrHrnRlySta "BAlarm_BurglarHornRelayStatus ##2G##BCM - BCMmsg19 - C_BurglarHornRly";
CM_ SG_ 992 BCM_KeyInSta "BCM_KeyInStatus ##2G##BCM - BCMmsg17 - C_KeyInSW";
CM_ SG_ 992 BCM_AccInSta "BCM_AccInputStatus ##2G##BCM - BCMmsg17 - C_Acc";
CM_ SG_ 992 BCM_Ign1InSta "BCM_Ignition1InputStatus ##2G##BCM - BCMmsg17 - C_Ign1";
CM_ SG_ 992 BCM_Ign2InSta "BCM_Ignition1InputStatus ##2G##BCM - BCMmsg17 - C_Ign2";
CM_ BO_ 994 "[PE] Periodic and On Event";
CM_ SG_ 994 BCM_Crc4Val "BCM_CyclicRedundancyCheck4Value";
CM_ SG_ 994 BCM_AlvCnt4Val "BCM_AliveCounter4Value";
CM_ SG_ 994 Warn_BzrWrngSta "Warn_BuzzerWarningStatus ##2G##BCM - BCMmsg18 - C_WngBuz";
CM_ SG_ 994 Warn_BCMWrngSta "Warn_BCMWarningStatus ##2G##BCM - BCMmsg19 - C_BCMWarning";
CM_ SG_ 994 ROA_RegionOpt "A Euro NCAP Option signal (BDC only)";
CM_ SG_ 994 Warn_RrStRmndOpt "Warn_RearSeatReminderOption ##2G##BCM - BCMmsg22 - C_RrSeatRemindOpt";
CM_ SG_ 994 Warn_RrStRmndAlrmOnReq "Warn_RearSeatReminderAlarmOnRequest ##2G##BCM - BCMmsg22 - C_RrSeatRemindAlarm";
CM_ SG_ 994 Warn_RrStRmndSysSta "Warn_RearSeatReminderSystemStatus ##2G##BCM - BCMmsg22 - C_RrSeatRemindState";
CM_ SG_ 994 Warn_RrStRmndAlrmInfo "Warn_RearSeatReminderAlarmInformaion ##2G##BCM - BCMmsg22 - C_RrSeatRemindInfo";
CM_ SG_ 994 Warn_RoaErr "Warn_RoaError##2G##BCM - BCMmsg22 - C_RoaError";
CM_ SG_ 994 WAL_FobSearching "IBU Walk Away Lock Fob Searching State for Radar ROA";
CM_ SG_ 994 Warn_RrStRmndDelay "Warn_RStRmndDelay";
CM_ SG_ 994 Warn_RrStRmndSysAct "Warn_RrStRmndSysAct";
CM_ SG_ 994 Warn_RrStRmndSysOffIND "Warning_RearSeatRemindSystemOffIND";
CM_ SG_ 994 Warn_VehNotPWrngSta "Vehicle Not P Warning";
CM_ BO_ 997 "[PE] Periodic and On Event";
CM_ SG_ 997 BCM_Crc5Val "BCM_CyclicRedundancyCheck5Value";
CM_ SG_ 997 BCM_AlvCnt5Val "BCM_AliveCounter5Value";
CM_ SG_ 997 PDW_OptTyp "PDW_OptionType ##2G##BCM - BCMmsg18 - C_PASOption";
CM_ SG_ 997 PDW_SysChkSndSta "PDW_SystemCheckSoundStatus ##2G##BCM - BCMmsg18 - C_PASCheckSound";
CM_ SG_ 997 PDW_SwIndOnReq "PDW_SwitchIndicatorOnRequest ##2G##BCM - BCMmsg18 - C_PASSwInd";
CM_ SG_ 997 PDW_FrCtWrngLvlDis "PDW_FrontCenterWarningLevelDisplay ##2G##BCM - BCMmsg18 - C_PASDisplayFCTR";
CM_ SG_ 997 PDW_FrCtWrngSndSta "PDW_FrontCenterWarningSoundStatus ##2G##BCM - BCMmsg23 - C_PasSpkrFCNTAlarm";
CM_ SG_ 997 PDW_FrLtWrngLvlDis "PDW_FrontLeftWarningLevelDisplay ##2G##BCM - BCMmsg18 - C_PASDisplayFLH";
CM_ SG_ 997 PDW_FrRtWrngLvlDis "PDW_FrontRightWarningLevelDisplay ##2G##BCM - BCMmsg18 - C_PASDisplayFRH";
CM_ SG_ 997 PU_F_Group7_DrvrAsstFlr11Sta "PDW Blockage / Failure Status";
CM_ SG_ 997 PDW_FrSnsrWrngLvlSta "PDW_FrontSensorWarningLevelStatus ##2G##BCM - BCMmsg18 - C_PASFsound";
CM_ BO_ 1002 "[PE] Periodic and On Event";
CM_ SG_ 1002 BLTN_CAM_HU_UI_Mode "Display control of Built-in Cam UI mode. This Signal for Ethernet Type Built-in Cam.";
CM_ SG_ 1002 BLTN_CAM_SD_Format_Op_State "BLTN_CAM SD card format operation status.";
CM_ SG_ 1002 BLTN_CAM_PEV_Recorded "This Signal is sent just after the park event recorded.";
CM_ SG_ 1002 BLTN_CAM_PEV_Count "This Signal is count of park event record.";
CM_ SG_ 1002 BLTN_CAM_Ind_Req "This Signal is for HU Display Built-in Cam Indicator.";
CM_ SG_ 1002 BLTN_CAM_LVDS_Mode_State "This Signal is for LVDS output status";
CM_ SG_ 1002 BLTN_CAM_PrkOp_Termiate_Info "0x0:Default/0x01: Park operation terminated earlier than user set because of Bat. SoC/0x2 : Park operation terminated earlier than user set because of SD Card Problem /0x3 : Park operation terminated earlier than user set because of Built-in Cam internal Error /0x04~0x6:Reserved/0x07 : Park operation terminate on time which user se";
CM_ SG_ 1002 BLTN_CAM_DEV_Recorded "This Signal is sent just after the drive event recorded.";
CM_ SG_ 1002 BLTN_CAM_DEV_Count "This Signal is count of drive event record.";
CM_ SG_ 1002 BLTN_CAM_Display "Display control of Built-in Cam UI mode. This Signal for CAN Type Built-in Cam.(with Standard 5th Wide AVNT)";
CM_ SG_ 1002 BLTN_CAM_WiFi_State "BLTN_CAM WiFi Stattus";
CM_ BO_ 2353206529 "[P] Periodic";
CM_ SG_ 2353206529 CLU_Crc20Val "CLU_CyclicRedundancyCheck20Value";
CM_ SG_ 2353206529 CLU_AlvCnt20Val "CLU_AliveCounter20Value";
CM_ SG_ 2353206529 CLU_SndType "CLU_SoundType";
CM_ SG_ 2353206529 USM_AdasHDPSetReq "This signal is used for a request to set the value of USM Menus. This signal requests to change status of HDP Mode.";
CM_ BO_ 2353206530 "[P] Periodic";
CM_ BO_ 1963 "[TP] Transport Protocol";
CM_ BO_ 1955 "[TP] Transport Protocol";
CM_ BO_ 1956 "[TP] Transport Protocol";
CM_ BO_ 1959 "[TP] Transport Protocol";
CM_ BO_ 1015 "[P] Periodic";
CM_ SG_ 1015 HU_MM_Altitude "Mapmatching Altitude";
CM_ SG_ 1015 HU_MM_Heading "Map matching heading";
CM_ BO_ 1016 "[P] Periodic";
CM_ SG_ 1016 GNSS_MM_type "Map matching type info.";
CM_ BO_ 1019 "[EC] On Event and On Change";
CM_ SG_ 1019 HU_MoodTherapyDrSeat "Moodtherapy Driver Seat On/Off";
CM_ SG_ 1019 HU_VitalityFragrance "Vitality Fragrance On/Off";
CM_ SG_ 1019 HU_VitalityCurtain "Vitality Curtain On/Off";
CM_ SG_ 1019 HU_DelightMoodLamp "Delight MoodLamp On/Off";
CM_ SG_ 1019 HU_DelightFragrance "Delight Fragrance On/Off";
CM_ SG_ 1019 HU_DelightCurtain "Delight Curtain On/Off";
CM_ SG_ 1019 HU_MoodTherapyPsSeat "Moodtherapy Passenger Seat On/Off";
CM_ SG_ 1019 HU_CareMoodLamp "Care MoodLamp On/Off";
CM_ SG_ 1019 HU_CareFragrance "Care Fragrance On/Off";
CM_ SG_ 1019 HU_CareMassage "Care Massage On/Off";
CM_ SG_ 1019 HU_CareCurtain "Care Curtain On/Off";
CM_ SG_ 1019 HU_ComfortMoodLamp "Comfort MoodLamp On/Off";
CM_ SG_ 1019 HU_ComfortFragrance "Comfort Fragrance On/Off";
CM_ SG_ 1019 HU_ComfortMassage "Comfort Massage On/Off";
CM_ SG_ 1019 HU_ComfortCurtain "Comfort Curtain On/Off";
CM_ SG_ 1019 HU_MoodTherapyMode "Moodtherapy Mode Change Signal";
CM_ SG_ 1019 HU_MoodTherapyRlSeat "Moodtherapy RearLeft Seat On/Off";
CM_ SG_ 1019 HU_MoodTherapyRrSeat "Moodtherapy Rear Right Seat On/Off";
CM_ SG_ 1019 HU_VitalityMoodLamp "Vitality MoodLamp On/Off";
CM_ BO_ 1993 "[TP] Transport Protocol";
CM_ BO_ 902 "[PE] Periodic and On Event";
CM_ SG_ 902 PSM_DrvStEsyAcsUSMSta "USM_MovingValue";
CM_ SG_ 902 PSM_SeatPosPlyBck_Sta "PSM_SeatPositionPlayBack_State";
CM_ SG_ 902 PSM_SeatPos_Sta "PSM_SeatPosition_State";
CM_ SG_ 902 PSM_SeatPosSldLmt_Sta "PSM_SeatPositionSlideLimitState";
CM_ SG_ 902 PSM_SeatPosRclnLmt_Sta "PSM_SeatPositionReclineLimitState";
CM_ SG_ 902 SmrtIMS_StatureRspVal "HCIMS_HeightRsponseValue";
CM_ SG_ 902 SmrtIMS_SeatedHghtRspVal "HCIMS_SitHeightRsponseValue";
CM_ SG_ 902 SmrtIMS_WghtRspVal "HCIMS_WeightRsponseValue";
CM_ SG_ 902 SmartIMS_DisReq "PSM_MoveStatusDisplay";
CM_ SG_ 902 SmrtIMS_ExitSta "Smart IMS exit condition";
CM_ SG_ 902 PSM_DrvStRlxTiltUpDis "PSM_DriverSeatRelexTiltUpDisplay";
CM_ SG_ 902 PSM_DrvStRlxTiltDnDis "PSM_DriverSeatRelexTiltDownDisplay";
CM_ SG_ 902 PSM_DrvStLegUpDis "PSM_DriverSeatLegUpDisplay";
CM_ SG_ 902 PSM_DrvStLegDnDis "PSM_DriverSeatLegDownDisplay";
CM_ SG_ 902 PSM_IMSOptTyp "Option flag for IMS system";
CM_ BO_ 903 "[PE] Periodic and On Event";
CM_ SG_ 903 PSM_DrvStSldFwdDis "PSM_DriverSlideForwardDisplay";
CM_ SG_ 903 PSM_DrvStTiltDnDis "PSM_DriverTiltDownSwitchDisplay";
CM_ SG_ 903 PSM_DrvStHghtUpDis "PSM_DriverHeightUpSwitchDisplay";
CM_ SG_ 903 PSM_DrvStHghtDnDis "PSM_DriverHeightDownSwitchDisplay";
CM_ SG_ 903 PSM_DrvStCushExtBckwdDis "PSM_DriverCushionExtendedBackwardSwitchDisplay";
CM_ SG_ 903 PSM_DrvStCushExtFwdDis "PSM_DriverCushionExtendedForwardSwitchDisplay";
CM_ SG_ 903 PSM_DrvStSldBckwdDis "PSM_DriverSlideBackwardSwitchDisplay";
CM_ SG_ 903 PSM_DrvStHdRstUpDis "PSM_DriverHeadRestUpSwitchDisplay";
CM_ SG_ 903 PSM_DrvStHdRstDnDis "PSM_DriverHeadRestDownSwitchDisplay";
CM_ SG_ 903 PSM_DrvStHdRstFwdDis "PSM_DriverHeadRestForwardSwitchDisplay";
CM_ SG_ 903 PSM_DrvStHdRstBckwdDis "PSM_DriverHeadRestBackwardSwitchDisplay";
CM_ SG_ 903 PSM_DrvStLmbrDefDis "PSM_DriverLumbarDeFlateSwitchDisplay";
CM_ SG_ 903 PSM_DrvStLmbrLoDis "PSM_DriverLumbarLowSwitchDisplay";
CM_ SG_ 903 PSM_DrvStLmbrMdlDis "PSM_DriverLumbarMiddleSwitchDisplay";
CM_ SG_ 903 PSM_DrvStLmbrUpDis "PSM_DriverLumbarUpSwitchDisplay";
CM_ SG_ 903 PSM_DrvStReclneFwdDis "PSM_DriverSeatReclineForwardSwitchDisplay";
CM_ SG_ 903 PSM_DrvStBlstrDefDis "PSM_DriverBolsterDeflateSwitchDisplay";
CM_ SG_ 903 PSM_DrvStBlstrInfDis "PSM_DriverBolsterInflateSwitchDisplay";
CM_ SG_ 903 PSM_DrvStReclneBckwdDis "PSM_DriverSeatReclineBackwardSwitchDisplay";
CM_ SG_ 903 PSM_DrvStTiltUpDis "PSM_DriverTiltUpSwitchDisplay";
CM_ BO_ 904 "[PE] Periodic and On Event";
CM_ SG_ 904 PSM_EsyAcsGetOffSta "Easy Access Get Off Information";
CM_ SG_ 904 PSM_EsyAcsStpSta "Easy Access Stop Information";
CM_ SG_ 904 PSM_SWVerMajor1 "First Word(ASCII) in PSM S/W Ver";
CM_ SG_ 904 PSM_SWVerMinor1 "Second Word(ASCII) in PSM S/W Ver";
CM_ SG_ 904 PSM_SWVerMinor2 "Third Word(ASCII) in PSM S/W Ver";
CM_ SG_ 904 PSM_HDPSpprtSWVer "Requirement Spec Version about PSM by HDP";
CM_ SG_ 904 PSM_EsyAcsGetOnSta "Easy Access Get On Information";
CM_ BO_ 1004 "[PE] Periodic and On Event";
CM_ SG_ 1004 CF_RCS_SwTyp "RCS type";
CM_ SG_ 1004 CF_RCS_OffRoad "OffRoad mode";
CM_ SG_ 1004 CF_RCS_BtnSta "RCS Button Status";
CM_ SG_ 1004 CF_RCS_RotateEnd "signal to inform end of rotate";
CM_ SG_ 1004 CF_RCS_4wdLocking "4wd locking on/off signal";
CM_ SG_ 1004 RCS_Direction_SW "RCS_Direction_SW";
CM_ SG_ 1004 CF_RCS_DrvMod "Drive mode select";
CM_ SG_ 1004 RCS_Mode_SW "RCS_Mode_SW";
CM_ BO_ 1003 "[PE] Periodic and On Event";
CM_ SG_ 1003 PSM_BzrOnRLReq "PSM_BuzzerOnRLRequest";
CM_ SG_ 1003 RLPSM_RrLfSldStrtSta "PSM_RearRightSlidingStartStatus";
CM_ SG_ 1003 RLPSM_OptTyp "RLPSM_OptionType (Rear Left PSM)";
CM_ SG_ 1003 RLPSM_RLStEsyAcsUSMSta "RLPSM_USM_MovingValue";
CM_ SG_ 1003 RLPSM_AllSeatPosPlyBck_Sta "RLPSM_AllSeatPositionPlayBack_State";
CM_ SG_ 1003 RLPSM_SeatPos_Sta "RLPSM_SeatPosition_State";
CM_ SG_ 1003 RLPSM_SeatPosSldLmt_Sta "RLPSM_SeatPositionSlideLimitState";
CM_ SG_ 1003 RLPSM_Enable_Sta "RLPSM_Enable_State";
CM_ SG_ 1003 RLPSM_Mem1_Sta "RLPSM_Memory1_State";
CM_ SG_ 1003 RLPSM_Mem2_Sta "RLPSM_Memory2_State";
CM_ SG_ 1003 RLPSM_Mem3_Sta "RLPSM_Memory3_State";
CM_ SG_ 1003 RLPSM_LimSetSta "RLPSM limit setting state";
CM_ BO_ 1005 "[PE] Periodic and On Event";
CM_ SG_ 1005 RLPSU_FldDis "2nd Left side seat moving state  : Folding";
CM_ SG_ 1005 RLPSU_TiltDownDis "2nd Left side seat moving state  : Tilt down";
CM_ SG_ 1005 RLPSU_RclFwdDis "2nd Left side seat moving state  : Recline Forward";
CM_ SG_ 1005 RLPSU_RclBwdDis "2nd Left side seat moving state  : Recline Backward";
CM_ SG_ 1005 RLPSU_RlxModeDis "2nd Left side seat moving state  : Relax mode";
CM_ SG_ 1005 RLPSU_Folding_SW "Interlocking signal between DPSM and RLPSU";
CM_ SG_ 1005 RLPSU_UnFldDis "2nd Left side seat moving state  : UnFolding";
CM_ SG_ 1005 RLPSU_Unfolding_SW "Interlocking signal between DPSM and RLPSU";
CM_ SG_ 1005 RLPSU_WalkIn_SW "Interlocking signal between DPSM and RLPSU";
CM_ SG_ 1005 RLPSU_UnwalkIn_SW "Interlocking signal between DPSM and RLPSU";
CM_ SG_ 1005 RLPSU_Folding_Postion "RLPSU Position Information";
CM_ SG_ 1005 RLPSU_Folding_State_PopUp "Rear LH seat Folding State information";
CM_ SG_ 1005 RLPSU_Relax_State_Popup "Rear LH seat Relax State information";
CM_ SG_ 1005 RLPSU_SlideFwdDis "2nd Left side seat moving state  : Slide Forward";
CM_ SG_ 1005 RLPSU_SlideBwdDis "2nd Left side seat moving state  : Slide Backward";
CM_ SG_ 1005 RLPSU_WalkInDis "2nd Left side seat moving state : Walk In";
CM_ SG_ 1005 RLPSU_WalkInState "2nd Left side seat Walk-in Ready state";
CM_ SG_ 1005 RLPSU_RLMsgEnable "This is the conditioning signal for RL Seat massage function (enabler/disable)";
CM_ SG_ 1005 RLPSU_UnWalkInDis "2nd Left side seat moving state : Un Walk In";
CM_ SG_ 1005 RLPSU_TiltUpDis "2nd Left side seat moving state  : Tilt up";
CM_ BO_ 1006 "[PE] Periodic and On Event";
CM_ SG_ 1006 RRPSU_FldDis "2nd Right side seat moving state  : Folding";
CM_ SG_ 1006 RRPSU_TiltDnDis "2nd Right side seat moving state  : Tilt down";
CM_ SG_ 1006 RRPSU_RecFwdDis "2nd Right side seat moving state  : Recline Forward";
CM_ SG_ 1006 RRPSU_RecBwdDis "2nd Right side seat moving state  : Recline Backward";
CM_ SG_ 1006 RRPSU_RlxModeDis "2nd Right side seat moving state  : Relax mode";
CM_ SG_ 1006 RRPSU_Folding_SW "Interlocking signal between DPSM and RRPSU";
CM_ SG_ 1006 RRPSU_UnFldDis "2nd Right side seat moving state  : UnFolding";
CM_ SG_ 1006 RRPSU_Unfolding_SW "Interlocking signal between DPSM and RRPSU";
CM_ SG_ 1006 RRPSU_WalkIn_SW "Interlocking signal between DPSM and RRPSU";
CM_ SG_ 1006 RRPSU_UnwalkIn_SW "Interlocking signal between DPSM and RRPSU";
CM_ SG_ 1006 RRPSU_Folding_Postion "RRPSU Position Information";
CM_ SG_ 1006 RRPSU_Folding_State_Popup "Rear RH seat Folding State information";
CM_ SG_ 1006 RRPSU_Relax_State_Popup "Rear RH seat Relax State information";
CM_ SG_ 1006 RRPSU_SlideFwdDis "2nd Right side seat moving state  : Slide Forward";
CM_ SG_ 1006 RRPSU_SlideBwdDis "2nd Right side seat moving state  : Slide Backward";
CM_ SG_ 1006 RRPSU_WalkinDis "2nd Right side seat moving state : Walk In";
CM_ SG_ 1006 RRPSU_WalkInState "2nd Right side seat Walk-in Ready state";
CM_ SG_ 1006 RRPSU_UnwalkinDis "2nd Right side seat moving state : Un Walk In";
CM_ SG_ 1006 RRPSU_TiltUpDis "2nd Right side seat moving state  : Tilt up";
CM_ BO_ 905 "[PE] Periodic and On Event";
CM_ SG_ 905 SBCM_RR_Crc1Val "SBCM_RR_CyclicRedundancyCheck1Value";
CM_ SG_ 905 RR_CrashUnlockCmd "Rear Right Crash Unlock Command";
CM_ SG_ 905 SBCM_RR_AlvCnt1Val "SBCM_RR_AliveCounter1Value";
CM_ SG_ 905 Warn_RrRtDrSwSta_SBCM "Warn_RearRightDoorSwitchStatus ##2G## -  - C_RRDrSw,CF_Gway_RRDrSw,Warn_RrRtDrSwSta";
CM_ SG_ 905 DoorLock_RrRtDrUnLkSta_SBCM "DoorLock_RearRightDoorUnLockStatus ##2G## -  - C_RRUnlockState,DoorLock_RrRtDrUnLkSta";
CM_ SG_ 905 RR_SEAActivated "Rear Right SEA Activated";
CM_ SG_ 905 RR_SEAWarn "Rear Righr SEA Warning";
CM_ BO_ 1964 "[TP] Transport Protocol";
CM_ BO_ 1967 "[TP] Transport Protocol";
BA_DEF_ BO_ "DiagState" ENUM "No","Yes" ;
BA_DEF_ BO_ "DiagResponse" ENUM "No","Yes" ;
BA_DEF_ BO_ "DiagRequest" ENUM "No","Yes" ;
BA_DEF_ BO_ "TpMessage" ENUM "No","Yes" ;
BA_DEF_ BO_ "UsrMsgIDSforwardDeviation" INT 0 100 ;
BA_DEF_ BO_ "UsrMsgIDSbackwardDeviation" INT 50 1000 ;
BA_DEF_ BO_ "GenMsgCycleTime" INT 0 2000 ;
BA_DEF_ BO_ "GenMsgStartDelayTime" INT 0 2000 ;
BA_DEF_ BO_ "GenMsgSendType" ENUM "Cyclic","NoMsgSendType" ;
BA_DEF_ BO_ "GenMsgCycleTimeFast" INT 0 500 ;
BA_DEF_ BO_ "GenMsgDelayTime" INT 0 20 ;
BA_DEF_ BO_ "GenMsgILSupport" ENUM "No","Yes" ;
BA_DEF_ BO_ "GenMsgNrOfRepetition" INT 0 3 ;
BA_DEF_ BO_ "NmMessage" ENUM "No","Yes" ;
BA_DEF_ BO_ "NWM-Botschaft" ENUM "No","Yes" ;
BA_DEF_ BO_ "TpTxIndex" INT 0 65535 ;
BA_DEF_ BO_ "VFrameFormat" ENUM "StandardCAN","ExtendedCAN","reserved","reserved","reserved","reserved","reserved","reserved","reserved","reserved","reserved","reserved","reserved","reserved","StandardCAN_FD","ExtendedCAN_FD" ;
BA_DEF_ SG_ "UserSigValidity" ENUM "B+","ACC","IG","IG1","IG2","IG3","IG1 or IG2","IG1 or IG3","Undef" ;
BA_DEF_ SG_ "TimeoutValue" STRING ;
BA_DEF_ SG_ "UsrSigPurpose" ENUM "Undef","FN","DIAG","DIAG(Req)","DIAG(Res)","DIAG(Phy)","DEV","CCP(Req)","CCP(Res)","NM","TP" ;
BA_DEF_ SG_ "GenSigStartValue" INT 0 1215752192 ;
BA_DEF_ SG_ "NetworkRequest" ENUM "Yes","No" ;
BA_DEF_ SG_ "NetworkRequestHoldingTime" INT 0 65535 ;
BA_DEF_ SG_ "Description" STRING ;
BA_DEF_ SG_ "Version" STRING ;
BA_DEF_ SG_ "GenSigEnvVarType" ENUM "Int","Float","Undef" ;
BA_DEF_ SG_ "GenSigSendType" ENUM "Cyclic","OnWrite","OnWriteWithRepetition","OnChange","OnChangeWithRepetition","IfActive","IfActiveWithRepetition","NoSigSendType","OnChangeAndIfActive","OnChangeAndIfActiveWithRepetition" ;
BA_DEF_ SG_ "GwSigLatencyTime" INT 0 65536 ;
BA_DEF_ SG_ "GwSigMissingSourceType" ENUM "Undef","OldValue","DefaultValue","InitialValue" ;
BA_DEF_ SG_ "NWM-WakeupAllowed" ENUM "<n.a.>" ;
BA_DEF_ SG_ "RoutingFactor" INT 1 1215752192 ;
BA_DEF_REL_ BU_SG_REL_ "GenSigTimeoutTime" INT 0 7000 ;
BA_DEF_DEF_ "DiagState" "No" ;
BA_DEF_DEF_ "DiagResponse" "No" ;
BA_DEF_DEF_ "DiagRequest" "No" ;
BA_DEF_DEF_ "TpMessage" "No" ;
BA_DEF_DEF_ "UsrMsgIDSforwardDeviation" 10 ;
BA_DEF_DEF_ "UsrMsgIDSbackwardDeviation" 100 ;
BA_DEF_DEF_ "GenMsgCycleTime" 200 ;
BA_DEF_DEF_ "GenMsgStartDelayTime" 0 ;
BA_DEF_DEF_ "GenMsgSendType" "NoMsgSendType" ;
BA_DEF_DEF_ "GenMsgCycleTimeFast" 40 ;
BA_DEF_DEF_ "GenMsgDelayTime" 20 ;
BA_DEF_DEF_ "GenMsgILSupport" "Yes" ;
BA_DEF_DEF_ "GenMsgNrOfRepetition" 3 ;
BA_DEF_DEF_ "NmMessage" "No" ;
BA_DEF_DEF_ "NWM-Botschaft" "No" ;
BA_DEF_DEF_ "TpTxIndex" 0 ;
BA_DEF_DEF_ "VFrameFormat" "StandardCAN" ;
BA_DEF_DEF_ "UserSigValidity" "IG" ;
BA_DEF_DEF_ "TimeoutValue" "" ;
BA_DEF_DEF_ "UsrSigPurpose" "FN" ;
BA_DEF_DEF_ "GenSigStartValue" 0 ;
BA_DEF_DEF_ "NetworkRequest" "No" ;
BA_DEF_DEF_ "NetworkRequestHoldingTime" 0 ;
BA_DEF_DEF_ "Description" "" ;
BA_DEF_DEF_ "Version" "" ;
BA_DEF_DEF_ "GenSigEnvVarType" "Undef" ;
BA_DEF_DEF_ "GenSigSendType" "NoSigSendType" ;
BA_DEF_DEF_ "GwSigLatencyTime" 40 ;
BA_DEF_DEF_ "GwSigMissingSourceType" "Undef" ;
BA_DEF_DEF_ "NWM-WakeupAllowed" "<n.a.>" ;
BA_DEF_DEF_ "RoutingFactor" 1 ;
BA_DEF_DEF_REL_ "GenSigTimeoutTime" 500 ;
BA_ "GenMsgCycleTime" BO_ 2151682561 0;
BA_ "GenMsgDelayTime" BO_ 2151682561 10;
BA_ "VFrameFormat" BO_ 2151682561 1;
BA_ "Description" SG_ 2151682561 ACU_ACTSAFETY_Crc1Val "The data area for CRC calculation is based on the data length (DLC) of the message DB.

The CRC shall be calculated over the entire data block (excluding the CRC bytes) including the user data, alive counter and Data ID



- CRC Polynomial (0x1021) , Initial Value : 0xFFFF, XOR value : 0x0000, Data ID : Message ID + 0xF800 

- The initial value is for CRC calculation and the message should be sent with the calculated result value. 

- The mathematical expression to 16 bit CRC polynomial is given here. G(x) = x16 + x12 + x5 + 1



<For CRC calculation of CAN-FD Msg for HS CAN domain ECUs>



- HS-CAN Messages that routed from CAN-FD domain are using 29 bit Extended CAN ID and splitted into 8 Byte Messages.

(from 1 to 4 Msgs, depending on source CAN-FD Msg¡¯s DLC)

- For splitted CAN-FD Msgs¡¯ CRC calculation, HS CAN ECUs should use source CAN-FD Msg¡¯s original STD ID. 

- The original STD ID can be read from Ext ID¡¯s 4~6th Byte.

Eg. STD 0x6AA : EXT SPLT 0x1A8[6AA]01 / 0x1A8[6AA]02 / 0x1A8[6AA]03 / 0x1A8[6AA]04 

(2~4th splitited Msgs can be omitted depending on source CAN-FD Msg¡¯s DLC)

- Aslo, HS-CAN ECUs should use merged data block (from whole splitted Msg) for CRC calculation.";
BA_ "GenSigSendType" SG_ 2151682561 ACU_ACTSAFETY_Crc1Val 2;
BA_ "GenSigStartValue" SG_ 2151682561 ACU_ACTSAFETY_Crc1Val 65535;
BA_ "UserSigValidity" SG_ 2151682561 ACU_ACTSAFETY_Crc1Val 3;
BA_REL_ "GenSigTimeoutTime" BU_SG_REL_ RCM SG_ 2151682561 ACU_ACTSAFETY_Crc1Val 0;
BA_ "Version" SG_ 2151682561 ACU_ACTSAFETY_Crc1Val "23.10.06";
BA_ "Description" SG_ 2151682561 ACU_ACTSAFETY_AlvCnt1Val "For the first transmission request for a data element the counter shall be initialized with 0 and shall be incremented by 1 for every subsequent send request. 

When the counter reaches the maximum value(0xFF), then it shall restart with 0 for the next send request";
BA_ "GenSigSendType" SG_ 2151682561 ACU_ACTSAFETY_AlvCnt1Val 2;
BA_ "UserSigValidity" SG_ 2151682561 ACU_ACTSAFETY_AlvCnt1Val 3;
BA_REL_ "GenSigTimeoutTime" BU_SG_REL_ RCM SG_ 2151682561 ACU_ACTSAFETY_AlvCnt1Val 0;
BA_ "Version" SG_ 2151682561 ACU_ACTSAFETY_AlvCnt1Val "23.10.06";
BA_ "Description" SG_ 2151682561 ACU_ACLOSER_WdwAct "This signal indicates the command of window closer activation in case of the emergency status. When activated, the active signal will be sent for 1sec(10ms * 100cnt).";
BA_ "GenSigSendType" SG_ 2151682561 ACU_ACLOSER_WdwAct 2;
BA_ "UserSigValidity" SG_ 2151682561 ACU_ACLOSER_WdwAct 3;
BA_REL_ "GenSigTimeoutTime" BU_SG_REL_ RCM SG_ 2151682561 ACU_ACLOSER_WdwAct 0;
BA_ "Version" SG_ 2151682561 ACU_ACLOSER_WdwAct "23.11.04";
BA_ "Description" SG_ 2151682561 ACU_ACLOSER_RoofAct "This signal indicates the command of roof closer activation in case of the emergency status. When activated, the active signal will be sent for 1sec(10ms * 100cnt).";
BA_ "GenSigSendType" SG_ 2151682561 ACU_ACLOSER_RoofAct 2;
BA_ "UserSigValidity" SG_ 2151682561 ACU_ACLOSER_RoofAct 3;
BA_REL_ "GenSigTimeoutTime" BU_SG_REL_ RCM SG_ 2151682561 ACU_ACLOSER_RoofAct 0;
BA_ "Version" SG_ 2151682561 ACU_ACLOSER_RoofAct "23.11.04";
BA_ "GenMsgCycleTime" BO_ 2151682562 0;
BA_ "GenMsgDelayTime" BO_ 2151682562 10;
BA_ "VFrameFormat" BO_ 2151682562 1;
BA_ "GenMsgSendType" BO_ 2235651329 0;
BA_ "GenMsgCycleTime" BO_ 2235651329 10;
BA_ "GenMsgCycleTimeFast" BO_ 2235651329 0;
BA_ "GenMsgNrOfRepetition" BO_ 2235651329 0;
BA_ "GenMsgDelayTime" BO_ 2235651329 0;
BA_ "VFrameFormat" BO_ 2235651329 1;
BA_ "Description" SG_ 2235651329 APSB_Crc1Val "The data area for CRC calculation is based on the data length (DLC) of the message DB.

The CRC shall be calculated over the entire data block (excluding the CRC bytes) including the user data, alive counter and Data ID



- CRC Polynomial (0x1021) , Initial Value : 0xFFFF, XOR value : 0x0000, Data ID : Message ID + 0xF800 

- The initial value is for CRC calculation and the message should be sent with the calculated result value. 

- The mathematical expression to 16 bit CRC polynomial is given here. G(x) = x16 + x12 + x5 + 1



<For CRC calculation of CAN-FD Msg for HS CAN domain ECUs>



- HS-CAN Messages that routed from CAN-FD domain are using 29 bit Extended CAN ID and splitted into 8 Byte Messages.

(from 1 to 4 Msgs, depending on source CAN-FD Msg¡¯s DLC)

- For splitted CAN-FD Msgs¡¯ CRC calculation, HS CAN ECUs should use source CAN-FD Msg¡¯s original STD ID. 

- The original STD ID can be read from Ext ID¡¯s 4~6th Byte.

Eg. STD 0x6AA : EXT SPLT 0x1A8[6AA]01 / 0x1A8[6AA]02 / 0x1A8[6AA]03 / 0x1A8[6AA]04 

(2~4th splitited Msgs can be omitted depending on source CAN-FD Msg¡¯s DLC)

- Aslo, HS-CAN ECUs should use merged data block (from whole splitted Msg) for CRC calculation.";
BA_ "GenSigStartValue" SG_ 2235651329 APSB_Crc1Val 65535;
BA_ "UserSigValidity" SG_ 2235651329 APSB_Crc1Val 3;
BA_ "Version" SG_ 2235651329 APSB_Crc1Val "21.12.05";
BA_ "Description" SG_ 2235651329 APSB_AlvCnt1Val "For the first transmission request for a data element the counter shall be initialized with 0 and shall be incremented by 1 for every subsequent send request. 

When the counter reaches the maximum value(0xFF), then it shall restart with 0 for the next send request";
BA_ "UserSigValidity" SG_ 2235651329 APSB_AlvCnt1Val 3;
BA_ "Version" SG_ 2235651329 APSB_AlvCnt1Val "21.12.05";
BA_ "Description" SG_ 2235651329 APSB_ConfTbl "This signal indicates supported signals that are correspond to detection type.

000000B : Not supported, 

xxxxx1B : Rough Road Impact 

xxxx1xB : FCA Impact

xxx1xxB : Minor Front Impact

xx1xxxB : Minor Side Impact

x1xxxxB : Minor Roll Detection

1xxxxxB : Minor Rear Impact";
BA_ "UserSigValidity" SG_ 2235651329 APSB_ConfTbl 3;
BA_ "Version" SG_ 2235651329 APSB_ConfTbl "18.02.03";
BA_ "Description" SG_ 2235651329 APSB_CrashActvSta "This signal indicates status of APSB activation by ACU.";
BA_ "UserSigValidity" SG_ 2235651329 APSB_CrashActvSta 3;
BA_ "Version" SG_ 2235651329 APSB_CrashActvSta "18.02.03";
BA_ "Description" SG_ 2235651329 APSB_RRDrvImpt "This signal indicates commends of APSB activation in case of rough road impact.";
BA_ "UserSigValidity" SG_ 2235651329 APSB_RRDrvImpt 3;
BA_ "Version" SG_ 2235651329 APSB_RRDrvImpt "18.02.03";
BA_ "Description" SG_ 2235651329 APSB_FCAFrImpt "This signal indicates commends of APSB activation in case of FCA impact.";
BA_ "UserSigValidity" SG_ 2235651329 APSB_FCAFrImpt 3;
BA_ "Version" SG_ 2235651329 APSB_FCAFrImpt "18.02.03";
BA_ "Description" SG_ 2235651329 APSB_MinFrImpt "This signal indicates commends of APSB activation in case of minor frontal  impact.";
BA_ "UserSigValidity" SG_ 2235651329 APSB_MinFrImpt 3;
BA_ "Version" SG_ 2235651329 APSB_MinFrImpt "18.02.03";
BA_ "Description" SG_ 2235651329 APSB_MinSidImpt "This signal indicates commends of APSB activation in case of minor side  impact.";
BA_ "UserSigValidity" SG_ 2235651329 APSB_MinSidImpt 3;
BA_ "Version" SG_ 2235651329 APSB_MinSidImpt "18.02.03";
BA_ "Description" SG_ 2235651329 APSB_MinRollDetn "This signal indicates commends of APSB activation in case of minor rollover detection.";
BA_ "UserSigValidity" SG_ 2235651329 APSB_MinRollDetn 3;
BA_ "Version" SG_ 2235651329 APSB_MinRollDetn "18.02.03";
BA_ "Description" SG_ 2235651329 APSB_MinRearImpt "This signal indicates commends of APSB activation in case of minor rear impact.";
BA_ "UserSigValidity" SG_ 2235651329 APSB_MinRearImpt 3;
BA_ "Version" SG_ 2235651329 APSB_MinRearImpt "18.02.03";
BA_ "GenMsgSendType" BO_ 2235651330 0;
BA_ "GenMsgCycleTime" BO_ 2235651330 10;
BA_ "GenMsgCycleTimeFast" BO_ 2235651330 0;
BA_ "GenMsgNrOfRepetition" BO_ 2235651330 0;
BA_ "GenMsgDelayTime" BO_ 2235651330 0;
BA_ "VFrameFormat" BO_ 2235651330 1;
BA_ "GenMsgCycleTime" BO_ 1007 0;
BA_ "Description" SG_ 1007 ATS_LEDBgtnsUpDn "This signal is  interior lamp brightness up/down control signal";
BA_ "GenSigSendType" SG_ 1007 ATS_LEDBgtnsUpDn 4;
BA_ "UserSigValidity" SG_ 1007 ATS_LEDBgtnsUpDn 3;
BA_REL_ "GenSigTimeoutTime" BU_SG_REL_ OHCL SG_ 1007 ATS_LEDBgtnsUpDn 0;
BA_ "Version" SG_ 1007 ATS_LEDBgtnsUpDn "20.04.05";
BA_ "Description" SG_ 1007 ATS_FrMoodOn_Req "Front mood lamp On/Off request";
BA_ "GenSigSendType" SG_ 1007 ATS_FrMoodOn_Req 4;
BA_ "UserSigValidity" SG_ 1007 ATS_FrMoodOn_Req 3;
BA_REL_ "GenSigTimeoutTime" BU_SG_REL_ OHCL SG_ 1007 ATS_FrMoodOn_Req 0;
BA_ "NetworkRequest" SG_ 1007 ATS_FrMoodOn_Req 0;
BA_ "NetworkRequestHoldingTime" SG_ 1007 ATS_FrMoodOn_Req 5000;
BA_ "Version" SG_ 1007 ATS_FrMoodOn_Req "20.06.09";
BA_ "Description" SG_ 1007 ATS_DoorOn_Req "Front Door switch On/Off request";
BA_ "GenSigSendType" SG_ 1007 ATS_DoorOn_Req 4;
BA_ "UserSigValidity" SG_ 1007 ATS_DoorOn_Req 3;
BA_REL_ "GenSigTimeoutTime" BU_SG_REL_ OHCL SG_ 1007 ATS_DoorOn_Req 0;
BA_ "NetworkRequest" SG_ 1007 ATS_DoorOn_Req 0;
BA_ "NetworkRequestHoldingTime" SG_ 1007 ATS_DoorOn_Req 5000;
BA_ "Version" SG_ 1007 ATS_DoorOn_Req "20.06.09";
BA_ "Description" SG_ 1007 ATS_RrMapLftOn_Req "Rear left map lamp On/Off request";
BA_ "GenSigSendType" SG_ 1007 ATS_RrMapLftOn_Req 4;
BA_ "UserSigValidity" SG_ 1007 ATS_RrMapLftOn_Req 3;
BA_REL_ "GenSigTimeoutTime" BU_SG_REL_ OHCL SG_ 1007 ATS_RrMapLftOn_Req 0;
BA_ "NetworkRequest" SG_ 1007 ATS_RrMapLftOn_Req 0;
BA_ "NetworkRequestHoldingTime" SG_ 1007 ATS_RrMapLftOn_Req 5000;
BA_ "Version" SG_ 1007 ATS_RrMapLftOn_Req "20.06.09";
BA_ "Description" SG_ 1007 ATS_RrMapRtOn_Req "Rear right map lamp On/Off request";
BA_ "GenSigSendType" SG_ 1007 ATS_RrMapRtOn_Req 4;
BA_ "UserSigValidity" SG_ 1007 ATS_RrMapRtOn_Req 3;
BA_REL_ "GenSigTimeoutTime" BU_SG_REL_ OHCL SG_ 1007 ATS_RrMapRtOn_Req 0;
BA_ "NetworkRequest" SG_ 1007 ATS_RrMapRtOn_Req 0;
BA_ "NetworkRequestHoldingTime" SG_ 1007 ATS_RrMapRtOn_Req 5000;
BA_ "Version" SG_ 1007 ATS_RrMapRtOn_Req "20.06.09";
BA_ "Description" SG_ 1007 ATS_RrRoomOn_Req "Rear room lamp On/Off request";
BA_ "GenSigSendType" SG_ 1007 ATS_RrRoomOn_Req 4;
BA_ "UserSigValidity" SG_ 1007 ATS_RrRoomOn_Req 3;
BA_REL_ "GenSigTimeoutTime" BU_SG_REL_ OHCL SG_ 1007 ATS_RrRoomOn_Req 0;
BA_ "NetworkRequest" SG_ 1007 ATS_RrRoomOn_Req 0;
BA_ "NetworkRequestHoldingTime" SG_ 1007 ATS_RrRoomOn_Req 5000;
BA_ "Version" SG_ 1007 ATS_RrRoomOn_Req "20.06.09";
BA_ "Description" SG_ 1007 ATS_LEDClrUpDn "This signal is  interior lamp color up/down control signal";
BA_ "GenSigSendType" SG_ 1007 ATS_LEDClrUpDn 4;
BA_ "UserSigValidity" SG_ 1007 ATS_LEDClrUpDn 3;
BA_REL_ "GenSigTimeoutTime" BU_SG_REL_ OHCL SG_ 1007 ATS_LEDClrUpDn 0;
BA_ "Version" SG_ 1007 ATS_LEDClrUpDn "20.04.05";
BA_ "Description" SG_ 1007 ATS_RrMoodOn_Req "Rear mood lamp On/Off request";
BA_ "GenSigSendType" SG_ 1007 ATS_RrMoodOn_Req 4;
BA_ "UserSigValidity" SG_ 1007 ATS_RrMoodOn_Req 3;
BA_REL_ "GenSigTimeoutTime" BU_SG_REL_ OHCL SG_ 1007 ATS_RrMoodOn_Req 0;
BA_ "NetworkRequest" SG_ 1007 ATS_RrMoodOn_Req 0;
BA_ "NetworkRequestHoldingTime" SG_ 1007 ATS_RrMoodOn_Req 5000;
BA_ "Version" SG_ 1007 ATS_RrMoodOn_Req "20.06.09";
BA_ "Description" SG_ 1007 ATS_LEDClr_Set "Interior Lamp LED Color Request";
BA_ "GenSigSendType" SG_ 1007 ATS_LEDClr_Set 4;
BA_ "UserSigValidity" SG_ 1007 ATS_LEDClr_Set 3;
BA_REL_ "GenSigTimeoutTime" BU_SG_REL_ OHCL SG_ 1007 ATS_LEDClr_Set 0;
BA_ "NetworkRequest" SG_ 1007 ATS_LEDClr_Set 0;
BA_ "NetworkRequestHoldingTime" SG_ 1007 ATS_LEDClr_Set 5000;
BA_ "Version" SG_ 1007 ATS_LEDClr_Set "20.06.09";
BA_ "Description" SG_ 1007 ATS_LEDBgtns_Set "Interior Lamp LED Brightness Request";
BA_ "GenSigSendType" SG_ 1007 ATS_LEDBgtns_Set 4;
BA_ "UserSigValidity" SG_ 1007 ATS_LEDBgtns_Set 3;
BA_REL_ "GenSigTimeoutTime" BU_SG_REL_ OHCL SG_ 1007 ATS_LEDBgtns_Set 0;
BA_ "NetworkRequest" SG_ 1007 ATS_LEDBgtns_Set 0;
BA_ "NetworkRequestHoldingTime" SG_ 1007 ATS_LEDBgtns_Set 5000;
BA_ "Version" SG_ 1007 ATS_LEDBgtns_Set "20.06.09";
BA_ "Description" SG_ 1007 ATS_LEDClrUpDnBtn "This signal is  interior lamp color up/down button control signal";
BA_ "GenSigSendType" SG_ 1007 ATS_LEDClrUpDnBtn 4;
BA_ "UserSigValidity" SG_ 1007 ATS_LEDClrUpDnBtn 3;
BA_ "Version" SG_ 1007 ATS_LEDClrUpDnBtn "20.06.07";
BA_ "Description" SG_ 1007 ATS_LEDBgtnsUpDnBtn "This signal is  interior lamp brightness up/down button control signal";
BA_ "GenSigSendType" SG_ 1007 ATS_LEDBgtnsUpDnBtn 4;
BA_ "UserSigValidity" SG_ 1007 ATS_LEDBgtnsUpDnBtn 3;
BA_ "Version" SG_ 1007 ATS_LEDBgtnsUpDnBtn "20.06.07";
BA_ "Description" SG_ 1007 ATS_FrMapLftOn_Req "Front left map lamp On/Off request";
BA_ "GenSigSendType" SG_ 1007 ATS_FrMapLftOn_Req 4;
BA_ "UserSigValidity" SG_ 1007 ATS_FrMapLftOn_Req 3;
BA_REL_ "GenSigTimeoutTime" BU_SG_REL_ OHCL SG_ 1007 ATS_FrMapLftOn_Req 0;
BA_ "NetworkRequest" SG_ 1007 ATS_FrMapLftOn_Req 0;
BA_ "NetworkRequestHoldingTime" SG_ 1007 ATS_FrMapLftOn_Req 5000;
BA_ "Version" SG_ 1007 ATS_FrMapLftOn_Req "20.06.09";
BA_ "Description" SG_ 1007 ATS_FrMapRtOn_Req "Front right map lamp On/Off request";
BA_ "GenSigSendType" SG_ 1007 ATS_FrMapRtOn_Req 4;
BA_ "UserSigValidity" SG_ 1007 ATS_FrMapRtOn_Req 3;
BA_REL_ "GenSigTimeoutTime" BU_SG_REL_ OHCL SG_ 1007 ATS_FrMapRtOn_Req 0;
BA_ "NetworkRequest" SG_ 1007 ATS_FrMapRtOn_Req 0;
BA_ "NetworkRequestHoldingTime" SG_ 1007 ATS_FrMapRtOn_Req 5000;
BA_ "Version" SG_ 1007 ATS_FrMapRtOn_Req "20.06.09";
BA_ "Description" SG_ 1007 ATS_FrRoomOn_Req "Front room lamp On/Off request";
BA_ "GenSigSendType" SG_ 1007 ATS_FrRoomOn_Req 4;
BA_ "UserSigValidity" SG_ 1007 ATS_FrRoomOn_Req 3;
BA_REL_ "GenSigTimeoutTime" BU_SG_REL_ OHCL SG_ 1007 ATS_FrRoomOn_Req 0;
BA_ "NetworkRequest" SG_ 1007 ATS_FrRoomOn_Req 0;
BA_ "NetworkRequestHoldingTime" SG_ 1007 ATS_FrRoomOn_Req 5000;
BA_ "Version" SG_ 1007 ATS_FrRoomOn_Req "20.06.09";
BA_ "GenMsgSendType" BO_ 992 0;
BA_ "Description" SG_ 992 BCM_Crc2Val "The data area for CRC calculation is based on the data length (DLC) of the message DB.

The CRC shall be calculated over the entire data block (excluding the CRC bytes) including the user data, alive counter and Data ID 

 

- CRC Polynomial (0x1D) , Initial Value : 0x00, XOR value : 0xFF, Data ID Mode : Both, Data ID : Message ID + 0xF800 

- The initial value is for CRC calculation and the message should be sent with the calculated result value. 

The mathematical expression to 8 bit CRC polynomial is given here. G(x) = x8 + x4 + x3 + x2 + 1";
BA_ "GenSigSendType" SG_ 992 BCM_Crc2Val 4;
BA_ "UserSigValidity" SG_ 992 BCM_Crc2Val 0;
BA_ "Version" SG_ 992 BCM_Crc2Val "21.09.03";
BA_ "Description" SG_ 992 BCM_AlvCnt2Val "For the first transmission request for a data element the counter shall be initialized with 0 and shall be incremented by 1

for every subsequent send request. When the counter reaches the maximum value(0xE), then it shall restart with 0 for the next send request";
BA_ "GenSigSendType" SG_ 992 BCM_AlvCnt2Val 4;
BA_ "UserSigValidity" SG_ 992 BCM_AlvCnt2Val 0;
BA_ "Version" SG_ 992 BCM_AlvCnt2Val "21.09.03";
BA_ "GenSigSendType" SG_ 992 BAlarm_BglrAlrmCurrentSta 4;
BA_ "UserSigValidity" SG_ 992 BAlarm_BglrAlrmCurrentSta 0;
BA_REL_ "GenSigTimeoutTime" BU_SG_REL_ BLTN_CAM SG_ 992 BAlarm_BglrAlrmCurrentSta 1500;
BA_ "NetworkRequest" SG_ 992 BAlarm_BglrAlrmCurrentSta 0;
BA_ "NetworkRequestHoldingTime" SG_ 992 BAlarm_BglrAlrmCurrentSta 5000;
BA_ "Version" SG_ 992 BAlarm_BglrAlrmCurrentSta "21.09.05";
BA_ "GenSigSendType" SG_ 992 BAlarm_BglrAlrmSta 4;
BA_ "UserSigValidity" SG_ 992 BAlarm_BglrAlrmSta 0;
BA_ "NetworkRequest" SG_ 992 BAlarm_BglrAlrmSta 0;
BA_ "NetworkRequestHoldingTime" SG_ 992 BAlarm_BglrAlrmSta 5000;
BA_ "Version" SG_ 992 BAlarm_BglrAlrmSta "17.12.00";
BA_ "Description" SG_ 992 BAlarm_PncAlrmSta "-For TeleCranking Panic Function

-This signal send to IBOX";
BA_ "GenSigSendType" SG_ 992 BAlarm_PncAlrmSta 4;
BA_ "UserSigValidity" SG_ 992 BAlarm_PncAlrmSta 0;
BA_ "NetworkRequest" SG_ 992 BAlarm_PncAlrmSta 0;
BA_ "NetworkRequestHoldingTime" SG_ 992 BAlarm_PncAlrmSta 5000;
BA_ "Version" SG_ 992 BAlarm_PncAlrmSta "21.09.05";
BA_ "GenSigSendType" SG_ 992 BAlarm_BrglrHrnRlySta 4;
BA_ "UserSigValidity" SG_ 992 BAlarm_BrglrHrnRlySta 0;
BA_ "NetworkRequest" SG_ 992 BAlarm_BrglrHrnRlySta 0;
BA_ "NetworkRequestHoldingTime" SG_ 992 BAlarm_BrglrHrnRlySta 5000;
BA_ "Version" SG_ 992 BAlarm_BrglrHrnRlySta "17.12.00";
BA_ "Description" SG_ 992 BCM_KeyInSta "Mechanical Key In SW State (If SMK option is On, C_KeyInSw always have  Off

 value)";
BA_ "GenSigSendType" SG_ 992 BCM_KeyInSta 4;
BA_ "UserSigValidity" SG_ 992 BCM_KeyInSta 0;
BA_REL_ "GenSigTimeoutTime" BU_SG_REL_ ALBCU SG_ 992 BCM_KeyInSta 1500;
BA_REL_ "GenSigTimeoutTime" BU_SG_REL_ ARS SG_ 992 BCM_KeyInSta 1500;
BA_REL_ "GenSigTimeoutTime" BU_SG_REL_ GW_APSU SG_ 992 BCM_KeyInSta 1500;
BA_REL_ "GenSigTimeoutTime" BU_SG_REL_ GW_DLBCU SG_ 992 BCM_KeyInSta 1500;
BA_REL_ "GenSigTimeoutTime" BU_SG_REL_ GW_DPSU SG_ 992 BCM_KeyInSta 1500;
BA_REL_ "GenSigTimeoutTime" BU_SG_REL_ GW_RLPSU SG_ 992 BCM_KeyInSta 1500;
BA_REL_ "GenSigTimeoutTime" BU_SG_REL_ GW_RRPSU SG_ 992 BCM_KeyInSta 1500;
BA_REL_ "GenSigTimeoutTime" BU_SG_REL_ PFSU SG_ 992 BCM_KeyInSta 1500;
BA_REL_ "GenSigTimeoutTime" BU_SG_REL_ RLHV SG_ 992 BCM_KeyInSta 1500;
BA_REL_ "GenSigTimeoutTime" BU_SG_REL_ RRHV SG_ 992 BCM_KeyInSta 1500;
BA_REL_ "GenSigTimeoutTime" BU_SG_REL_ SGU SG_ 992 BCM_KeyInSta 1500;
BA_REL_ "GenSigTimeoutTime" BU_SG_REL_ SHVU_FR SG_ 992 BCM_KeyInSta 1500;
BA_REL_ "GenSigTimeoutTime" BU_SG_REL_ SHVU_RR SG_ 992 BCM_KeyInSta 1500;
BA_REL_ "GenSigTimeoutTime" BU_SG_REL_ SWRC SG_ 992 BCM_KeyInSta 1500;
BA_ "NetworkRequest" SG_ 992 BCM_KeyInSta 0;
BA_ "NetworkRequestHoldingTime" SG_ 992 BCM_KeyInSta 5000;
BA_ "Version" SG_ 992 BCM_KeyInSta "17.12.00";
BA_ "GenSigSendType" SG_ 992 BCM_AccInSta 4;
BA_ "UserSigValidity" SG_ 992 BCM_AccInSta 0;
BA_REL_ "GenSigTimeoutTime" BU_SG_REL_ ALBCU SG_ 992 BCM_AccInSta 1500;
BA_REL_ "GenSigTimeoutTime" BU_SG_REL_ ARS SG_ 992 BCM_AccInSta 1500;
BA_REL_ "GenSigTimeoutTime" BU_SG_REL_ ASAU SG_ 992 BCM_AccInSta 1500;
BA_REL_ "GenSigTimeoutTime" BU_SG_REL_ ATS SG_ 992 BCM_AccInSta 1500;
BA_REL_ "GenSigTimeoutTime" BU_SG_REL_ DSAU SG_ 992 BCM_AccInSta 1500;
BA_REL_ "GenSigTimeoutTime" BU_SG_REL_ GW_APSU SG_ 992 BCM_AccInSta 1500;
BA_REL_ "GenSigTimeoutTime" BU_SG_REL_ GW_DLBCU SG_ 992 BCM_AccInSta 1500;
BA_REL_ "GenSigTimeoutTime" BU_SG_REL_ GW_DPSU SG_ 992 BCM_AccInSta 1500;
BA_REL_ "GenSigTimeoutTime" BU_SG_REL_ GW_RLPSU SG_ 992 BCM_AccInSta 1500;
BA_REL_ "GenSigTimeoutTime" BU_SG_REL_ GW_RRPSU SG_ 992 BCM_AccInSta 1500;
BA_REL_ "GenSigTimeoutTime" BU_SG_REL_ PFSU SG_ 992 BCM_AccInSta 1500;
BA_REL_ "GenSigTimeoutTime" BU_SG_REL_ RLHV SG_ 992 BCM_AccInSta 1500;
BA_REL_ "GenSigTimeoutTime" BU_SG_REL_ RRHV SG_ 992 BCM_AccInSta 1500;
BA_REL_ "GenSigTimeoutTime" BU_SG_REL_ SCM SG_ 992 BCM_AccInSta 1500;
BA_REL_ "GenSigTimeoutTime" BU_SG_REL_ SGU SG_ 992 BCM_AccInSta 1500;
BA_REL_ "GenSigTimeoutTime" BU_SG_REL_ SHVU_FR SG_ 992 BCM_AccInSta 1500;
BA_REL_ "GenSigTimeoutTime" BU_SG_REL_ SHVU_RR SG_ 992 BCM_AccInSta 1500;
BA_REL_ "GenSigTimeoutTime" BU_SG_REL_ SWRC SG_ 992 BCM_AccInSta 1500;
BA_REL_ "GenSigTimeoutTime" BU_SG_REL_ WPC2 SG_ 992 BCM_AccInSta 1500;
BA_ "NetworkRequest" SG_ 992 BCM_AccInSta 0;
BA_ "NetworkRequestHoldingTime" SG_ 992 BCM_AccInSta 5000;
BA_ "Version" SG_ 992 BCM_AccInSta "21.09.05";
BA_ "GenSigSendType" SG_ 992 BCM_Ign1InSta 4;
BA_ "UserSigValidity" SG_ 992 BCM_Ign1InSta 0;
BA_REL_ "GenSigTimeoutTime" BU_SG_REL_ ALBCU SG_ 992 BCM_Ign1InSta 1500;
BA_REL_ "GenSigTimeoutTime" BU_SG_REL_ ARS SG_ 992 BCM_Ign1InSta 1500;
BA_REL_ "GenSigTimeoutTime" BU_SG_REL_ ASAU SG_ 992 BCM_Ign1InSta 1500;
BA_REL_ "GenSigTimeoutTime" BU_SG_REL_ ATS SG_ 992 BCM_Ign1InSta 1500;
BA_REL_ "GenSigTimeoutTime" BU_SG_REL_ DSAU SG_ 992 BCM_Ign1InSta 1500;
BA_REL_ "GenSigTimeoutTime" BU_SG_REL_ GW_APSU SG_ 992 BCM_Ign1InSta 1500;
BA_REL_ "GenSigTimeoutTime" BU_SG_REL_ GW_DLBCU SG_ 992 BCM_Ign1InSta 1500;
BA_REL_ "GenSigTimeoutTime" BU_SG_REL_ GW_DPSU SG_ 992 BCM_Ign1InSta 1500;
BA_REL_ "GenSigTimeoutTime" BU_SG_REL_ GW_RLPSU SG_ 992 BCM_Ign1InSta 1500;
BA_REL_ "GenSigTimeoutTime" BU_SG_REL_ GW_RRPSU SG_ 992 BCM_Ign1InSta 1500;
BA_REL_ "GenSigTimeoutTime" BU_SG_REL_ HOD SG_ 992 BCM_Ign1InSta 1500;
BA_REL_ "GenSigTimeoutTime" BU_SG_REL_ PFSU SG_ 992 BCM_Ign1InSta 1500;
BA_REL_ "GenSigTimeoutTime" BU_SG_REL_ RCM SG_ 992 BCM_Ign1InSta 1500;
BA_REL_ "GenSigTimeoutTime" BU_SG_REL_ RLHV SG_ 992 BCM_Ign1InSta 1500;
BA_REL_ "GenSigTimeoutTime" BU_SG_REL_ RRHV SG_ 992 BCM_Ign1InSta 1500;
BA_REL_ "GenSigTimeoutTime" BU_SG_REL_ SCM SG_ 992 BCM_Ign1InSta 1500;
BA_REL_ "GenSigTimeoutTime" BU_SG_REL_ SGU SG_ 992 BCM_Ign1InSta 1500;
BA_REL_ "GenSigTimeoutTime" BU_SG_REL_ SHVU_FR SG_ 992 BCM_Ign1InSta 1500;
BA_REL_ "GenSigTimeoutTime" BU_SG_REL_ SHVU_RR SG_ 992 BCM_Ign1InSta 1500;
BA_REL_ "GenSigTimeoutTime" BU_SG_REL_ SWRC SG_ 992 BCM_Ign1InSta 1500;
BA_ "NetworkRequest" SG_ 992 BCM_Ign1InSta 0;
BA_ "NetworkRequestHoldingTime" SG_ 992 BCM_Ign1InSta 5000;
BA_ "Version" SG_ 992 BCM_Ign1InSta "21.09.05";
BA_ "GenSigSendType" SG_ 992 BCM_Ign2InSta 4;
BA_ "UserSigValidity" SG_ 992 BCM_Ign2InSta 0;
BA_REL_ "GenSigTimeoutTime" BU_SG_REL_ ALBCU SG_ 992 BCM_Ign2InSta 1500;
BA_REL_ "GenSigTimeoutTime" BU_SG_REL_ ARS SG_ 992 BCM_Ign2InSta 1500;
BA_REL_ "GenSigTimeoutTime" BU_SG_REL_ ASAU SG_ 992 BCM_Ign2InSta 1500;
BA_REL_ "GenSigTimeoutTime" BU_SG_REL_ ATS SG_ 992 BCM_Ign2InSta 1500;
BA_REL_ "GenSigTimeoutTime" BU_SG_REL_ DSAU SG_ 992 BCM_Ign2InSta 1500;
BA_REL_ "GenSigTimeoutTime" BU_SG_REL_ FCS SG_ 992 BCM_Ign2InSta 1500;
BA_REL_ "GenSigTimeoutTime" BU_SG_REL_ GW_APSU SG_ 992 BCM_Ign2InSta 1500;
BA_REL_ "GenSigTimeoutTime" BU_SG_REL_ GW_DLBCU SG_ 992 BCM_Ign2InSta 1500;
BA_REL_ "GenSigTimeoutTime" BU_SG_REL_ GW_DPSU SG_ 992 BCM_Ign2InSta 1500;
BA_REL_ "GenSigTimeoutTime" BU_SG_REL_ GW_RLPSU SG_ 992 BCM_Ign2InSta 1500;
BA_REL_ "GenSigTimeoutTime" BU_SG_REL_ GW_RRPSU SG_ 992 BCM_Ign2InSta 1500;
BA_REL_ "GenSigTimeoutTime" BU_SG_REL_ PFSU SG_ 992 BCM_Ign2InSta 1500;
BA_REL_ "GenSigTimeoutTime" BU_SG_REL_ RCM SG_ 992 BCM_Ign2InSta 1500;
BA_REL_ "GenSigTimeoutTime" BU_SG_REL_ RLHV SG_ 992 BCM_Ign2InSta 1500;
BA_REL_ "GenSigTimeoutTime" BU_SG_REL_ RRHV SG_ 992 BCM_Ign2InSta 1500;
BA_REL_ "GenSigTimeoutTime" BU_SG_REL_ SCM SG_ 992 BCM_Ign2InSta 1500;
BA_REL_ "GenSigTimeoutTime" BU_SG_REL_ SGU SG_ 992 BCM_Ign2InSta 1500;
BA_REL_ "GenSigTimeoutTime" BU_SG_REL_ SHVU_FR SG_ 992 BCM_Ign2InSta 1500;
BA_REL_ "GenSigTimeoutTime" BU_SG_REL_ SHVU_RR SG_ 992 BCM_Ign2InSta 1500;
BA_REL_ "GenSigTimeoutTime" BU_SG_REL_ SWRC SG_ 992 BCM_Ign2InSta 1500;
BA_ "NetworkRequest" SG_ 992 BCM_Ign2InSta 0;
BA_ "NetworkRequestHoldingTime" SG_ 992 BCM_Ign2InSta 5000;
BA_ "Version" SG_ 992 BCM_Ign2InSta "21.09.05";
BA_ "GenMsgSendType" BO_ 994 0;
BA_ "Description" SG_ 994 BCM_Crc4Val "The data area for CRC calculation is based on the data length (DLC) of the message DB.

The CRC shall be calculated over the entire data block (excluding the CRC bytes) including the user data, alive counter and Data ID 

 

- CRC Polynomial (0x1D) , Initial Value : 0x00, XOR value : 0xFF, Data ID Mode : Both, Data ID : Message ID + 0xF800 

- The initial value is for CRC calculation and the message should be sent with the calculated result value. 

The mathematical expression to 8 bit CRC polynomial is given here. G(x) = x8 + x4 + x3 + x2 + 1";
BA_ "GenSigSendType" SG_ 994 BCM_Crc4Val 4;
BA_ "UserSigValidity" SG_ 994 BCM_Crc4Val 0;
BA_ "Version" SG_ 994 BCM_Crc4Val "21.09.03";
BA_ "Description" SG_ 994 BCM_AlvCnt4Val "For the first transmission request for a data element the counter shall be initialized with 0 and shall be incremented by 1

for every subsequent send request. When the counter reaches the maximum value(0xE), then it shall restart with 0 for the next send request";
BA_ "GenSigSendType" SG_ 994 BCM_AlvCnt4Val 4;
BA_ "UserSigValidity" SG_ 994 BCM_AlvCnt4Val 0;
BA_ "Version" SG_ 994 BCM_AlvCnt4Val "21.09.03";
BA_ "Description" SG_ 994 Warn_BzrWrngSta "-(Old)C_WngBuzzer";
BA_ "GenSigSendType" SG_ 994 Warn_BzrWrngSta 4;
BA_ "UserSigValidity" SG_ 994 Warn_BzrWrngSta 0;
BA_ "NetworkRequest" SG_ 994 Warn_BzrWrngSta 0;
BA_ "NetworkRequestHoldingTime" SG_ 994 Warn_BzrWrngSta 5000;
BA_ "Version" SG_ 994 Warn_BzrWrngSta "17.12.00";
BA_ "Description" SG_ 994 Warn_BCMWrngSta "Warning command og BCM";
BA_ "GenSigSendType" SG_ 994 Warn_BCMWrngSta 4;
BA_ "UserSigValidity" SG_ 994 Warn_BCMWrngSta 0;
BA_ "NetworkRequest" SG_ 994 Warn_BCMWrngSta 0;
BA_ "NetworkRequestHoldingTime" SG_ 994 Warn_BCMWrngSta 5000;
BA_ "Version" SG_ 994 Warn_BCMWrngSta "23.04.04";
BA_ "Description" SG_ 994 ROA_RrBlwAutoOffReq "This signal is used for a request to Rear Blow Off (Auto Cut)";
BA_ "GenSigSendType" SG_ 994 ROA_RrBlwAutoOffReq 4;
BA_ "UserSigValidity" SG_ 994 ROA_RrBlwAutoOffReq 0;
BA_ "NetworkRequest" SG_ 994 ROA_RrBlwAutoOffReq 0;
BA_ "NetworkRequestHoldingTime" SG_ 994 ROA_RrBlwAutoOffReq 5000;
BA_ "Version" SG_ 994 ROA_RrBlwAutoOffReq "21.04.00";
BA_ "Description" SG_ 994 ROA_RegionOpt "A Euro NCAP Option signal (BDC only)";
BA_ "GenSigSendType" SG_ 994 ROA_RegionOpt 4;
BA_ "UserSigValidity" SG_ 994 ROA_RegionOpt 0;
BA_ "NetworkRequest" SG_ 994 ROA_RegionOpt 0;
BA_ "NetworkRequestHoldingTime" SG_ 994 ROA_RegionOpt 5000;
BA_ "Version" SG_ 994 ROA_RegionOpt "21.11.07";
BA_ "Description" SG_ 994 Warn_RrStRmndOpt "Rear Seat Reminder System Appled Option

(BDC Only Use 0x0 and 0x2 in Signal Value Table)";
BA_ "GenSigSendType" SG_ 994 Warn_RrStRmndOpt 4;
BA_ "UserSigValidity" SG_ 994 Warn_RrStRmndOpt 0;
BA_ "NetworkRequest" SG_ 994 Warn_RrStRmndOpt 0;
BA_ "NetworkRequestHoldingTime" SG_ 994 Warn_RrStRmndOpt 5000;
BA_ "Version" SG_ 994 Warn_RrStRmndOpt "21.04.00";
BA_ "Description" SG_ 994 Warn_RrStRmndAlrmOnReq "Rear Seat Reminder Alarm State";
BA_ "GenSigSendType" SG_ 994 Warn_RrStRmndAlrmOnReq 4;
BA_ "UserSigValidity" SG_ 994 Warn_RrStRmndAlrmOnReq 0;
BA_ "NetworkRequest" SG_ 994 Warn_RrStRmndAlrmOnReq 0;
BA_ "NetworkRequestHoldingTime" SG_ 994 Warn_RrStRmndAlrmOnReq 5000;
BA_ "Version" SG_ 994 Warn_RrStRmndAlrmOnReq "17.12.00";
BA_ "Description" SG_ 994 Warn_RrStRmndSysSta "Rear Seat Reminder Alarm System Enable(On)/Disable(Off) state";
BA_ "GenSigSendType" SG_ 994 Warn_RrStRmndSysSta 4;
BA_ "UserSigValidity" SG_ 994 Warn_RrStRmndSysSta 0;
BA_ "NetworkRequest" SG_ 994 Warn_RrStRmndSysSta 0;
BA_ "NetworkRequestHoldingTime" SG_ 994 Warn_RrStRmndSysSta 5000;
BA_ "Version" SG_ 994 Warn_RrStRmndSysSta "17.12.00";
BA_ "Description" SG_ 994 Warn_RrStRmndAlrmInfo "Rear Seat Reminder Warning request signal";
BA_ "GenSigSendType" SG_ 994 Warn_RrStRmndAlrmInfo 4;
BA_ "UserSigValidity" SG_ 994 Warn_RrStRmndAlrmInfo 0;
BA_REL_ "GenSigTimeoutTime" BU_SG_REL_ SWRC SG_ 994 Warn_RrStRmndAlrmInfo 1500;
BA_ "NetworkRequest" SG_ 994 Warn_RrStRmndAlrmInfo 0;
BA_ "NetworkRequestHoldingTime" SG_ 994 Warn_RrStRmndAlrmInfo 5000;
BA_ "Version" SG_ 994 Warn_RrStRmndAlrmInfo "22.03.04";
BA_ "Description" SG_ 994 Warn_RoaErr "ROA SENSOR Error(Malfunction)  signal";
BA_ "GenSigSendType" SG_ 994 Warn_RoaErr 4;
BA_ "UserSigValidity" SG_ 994 Warn_RoaErr 0;
BA_ "NetworkRequest" SG_ 994 Warn_RoaErr 0;
BA_ "NetworkRequestHoldingTime" SG_ 994 Warn_RoaErr 5000;
BA_ "Version" SG_ 994 Warn_RoaErr "18.07.01";
BA_ "Description" SG_ 994 WAL_FobSearching "IBU Walk Away Lock Fob Searching State for Radar ROA

(LIN_IBU_WAL_FobSearching for UIP ROA)";
BA_ "GenSigSendType" SG_ 994 WAL_FobSearching 4;
BA_ "UserSigValidity" SG_ 994 WAL_FobSearching 0;
BA_ "NetworkRequest" SG_ 994 WAL_FobSearching 0;
BA_ "NetworkRequestHoldingTime" SG_ 994 WAL_FobSearching 5000;
BA_ "Version" SG_ 994 WAL_FobSearching "19.06.00";
BA_ "GenSigSendType" SG_ 994 Warn_RrStRmndDelay 4;
BA_ "TimeoutValue" SG_ 994 Warn_RrStRmndDelay "0x0";
BA_ "UserSigValidity" SG_ 994 Warn_RrStRmndDelay 0;
BA_ "NetworkRequest" SG_ 994 Warn_RrStRmndDelay 0;
BA_ "NetworkRequestHoldingTime" SG_ 994 Warn_RrStRmndDelay 5000;
BA_ "Version" SG_ 994 Warn_RrStRmndDelay "22.03.04";
BA_ "GenSigSendType" SG_ 994 Warn_RrStRmndSysAct 4;
BA_ "TimeoutValue" SG_ 994 Warn_RrStRmndSysAct "0x0";
BA_ "UserSigValidity" SG_ 994 Warn_RrStRmndSysAct 0;
BA_ "NetworkRequest" SG_ 994 Warn_RrStRmndSysAct 0;
BA_ "NetworkRequestHoldingTime" SG_ 994 Warn_RrStRmndSysAct 5000;
BA_ "Version" SG_ 994 Warn_RrStRmndSysAct "22.03.04";
BA_ "GenSigSendType" SG_ 994 Warn_RrStRmndSysOffIND 4;
BA_ "TimeoutValue" SG_ 994 Warn_RrStRmndSysOffIND "0x0";
BA_ "UserSigValidity" SG_ 994 Warn_RrStRmndSysOffIND 0;
BA_ "NetworkRequest" SG_ 994 Warn_RrStRmndSysOffIND 0;
BA_ "NetworkRequestHoldingTime" SG_ 994 Warn_RrStRmndSysOffIND 5000;
BA_ "Version" SG_ 994 Warn_RrStRmndSysOffIND "22.08.01";
BA_ "Description" SG_ 994 Warn_VehNotPWrngSta "Vehicle Not P Warning";
BA_ "GenSigSendType" SG_ 994 Warn_VehNotPWrngSta 4;
BA_ "UserSigValidity" SG_ 994 Warn_VehNotPWrngSta 0;
BA_ "NetworkRequest" SG_ 994 Warn_VehNotPWrngSta 0;
BA_ "NetworkRequestHoldingTime" SG_ 994 Warn_VehNotPWrngSta 5000;
BA_ "Version" SG_ 994 Warn_VehNotPWrngSta "23.05.01";
BA_ "GenMsgSendType" BO_ 997 0;
BA_ "Description" SG_ 997 BCM_Crc5Val "The data area for CRC calculation is based on the data length (DLC) of the message DB.

The CRC shall be calculated over the entire data block (excluding the CRC bytes) including the user data, alive counter and Data ID 

 

- CRC Polynomial (0x1D) , Initial Value : 0x00, XOR value : 0xFF, Data ID Mode : Both, Data ID : Message ID + 0xF800 

- The initial value is for CRC calculation and the message should be sent with the calculated result value. 

The mathematical expression to 8 bit CRC polynomial is given here. G(x) = x8 + x4 + x3 + x2 + 1";
BA_ "GenSigSendType" SG_ 997 BCM_Crc5Val 4;
BA_ "UserSigValidity" SG_ 997 BCM_Crc5Val 0;
BA_ "Version" SG_ 997 BCM_Crc5Val "21.09.03";
BA_ "Description" SG_ 997 BCM_AlvCnt5Val "For the first transmission request for a data element the counter shall be initialized with 0 and shall be incremented by 1

for every subsequent send request. When the counter reaches the maximum value(0xE), then it shall restart with 0 for the next send request";
BA_ "GenSigSendType" SG_ 997 BCM_AlvCnt5Val 4;
BA_ "UserSigValidity" SG_ 997 BCM_AlvCnt5Val 0;
BA_ "Version" SG_ 997 BCM_AlvCnt5Val "21.09.03";
BA_ "Description" SG_ 997 PDW_OptTyp "this signal means PDW Option (Non, PDW-R, PDW-FR)

0x3: Reserved for the same Value Table as the ADAS_PRK Signal";
BA_ "GenSigSendType" SG_ 997 PDW_OptTyp 4;
BA_ "UserSigValidity" SG_ 997 PDW_OptTyp 3;
BA_ "NetworkRequest" SG_ 997 PDW_OptTyp 0;
BA_ "NetworkRequestHoldingTime" SG_ 997 PDW_OptTyp 5000;
BA_ "Version" SG_ 997 PDW_OptTyp "20.11.02";
BA_ "Description" SG_ 997 PDW_SysChkSndSta "-PDW System state check sound";
BA_ "GenSigSendType" SG_ 997 PDW_SysChkSndSta 4;
BA_ "UserSigValidity" SG_ 997 PDW_SysChkSndSta 0;
BA_ "NetworkRequest" SG_ 997 PDW_SysChkSndSta 0;
BA_ "NetworkRequestHoldingTime" SG_ 997 PDW_SysChkSndSta 5000;
BA_ "Version" SG_ 997 PDW_SysChkSndSta "17.12.00";
BA_ "Description" SG_ 997 PDW_SwIndOnReq "-PDW Switch Indicator On/Off Request

This signal is used for PDW-R and PDW-F/R";
BA_ "GenSigSendType" SG_ 997 PDW_SwIndOnReq 4;
BA_ "UserSigValidity" SG_ 997 PDW_SwIndOnReq 0;
BA_REL_ "GenSigTimeoutTime" BU_SG_REL_ FCS SG_ 997 PDW_SwIndOnReq 1500;
BA_ "NetworkRequest" SG_ 997 PDW_SwIndOnReq 0;
BA_ "NetworkRequestHoldingTime" SG_ 997 PDW_SwIndOnReq 5000;
BA_ "Version" SG_ 997 PDW_SwIndOnReq "18.03.05";
BA_ "Description" SG_ 997 PDW_FrCtWrngLvlDis "-Front center display";
BA_ "GenSigSendType" SG_ 997 PDW_FrCtWrngLvlDis 4;
BA_ "UserSigValidity" SG_ 997 PDW_FrCtWrngLvlDis 0;
BA_ "NetworkRequest" SG_ 997 PDW_FrCtWrngLvlDis 0;
BA_ "NetworkRequestHoldingTime" SG_ 997 PDW_FrCtWrngLvlDis 5000;
BA_ "Version" SG_ 997 PDW_FrCtWrngLvlDis "21.03.09";
BA_ "Description" SG_ 997 PDW_SysFlrSta "Ultrasonic sensor status - Blockage/Failure pop-up request";
BA_ "GenSigSendType" SG_ 997 PDW_SysFlrSta 4;
BA_ "UserSigValidity" SG_ 997 PDW_SysFlrSta 3;
BA_ "Version" SG_ 997 PDW_SysFlrSta "20.11.02";
BA_ "Description" SG_ 997 PDW_FrCtWrngSndSta "-Pas Warning Sound for AMP Speaker output";
BA_ "GenSigSendType" SG_ 997 PDW_FrCtWrngSndSta 4;
BA_ "UserSigValidity" SG_ 997 PDW_FrCtWrngSndSta 0;
BA_ "NetworkRequest" SG_ 997 PDW_FrCtWrngSndSta 0;
BA_ "NetworkRequestHoldingTime" SG_ 997 PDW_FrCtWrngSndSta 5000;
BA_ "Version" SG_ 997 PDW_FrCtWrngSndSta "20.04.02";
BA_ "Description" SG_ 997 PDW_FrLtWrngLvlDis "-Front Left display";
BA_ "GenSigSendType" SG_ 997 PDW_FrLtWrngLvlDis 4;
BA_ "UserSigValidity" SG_ 997 PDW_FrLtWrngLvlDis 0;
BA_ "NetworkRequest" SG_ 997 PDW_FrLtWrngLvlDis 0;
BA_ "NetworkRequestHoldingTime" SG_ 997 PDW_FrLtWrngLvlDis 5000;
BA_ "Version" SG_ 997 PDW_FrLtWrngLvlDis "21.03.09";
BA_ "Description" SG_ 997 PDW_CRBdDis "- Car Body Display";
BA_ "GenSigSendType" SG_ 997 PDW_CRBdDis 4;
BA_ "UserSigValidity" SG_ 997 PDW_CRBdDis 0;
BA_ "NetworkRequest" SG_ 997 PDW_CRBdDis 0;
BA_ "NetworkRequestHoldingTime" SG_ 997 PDW_CRBdDis 5000;
BA_ "Version" SG_ 997 PDW_CRBdDis "21.03.09";
BA_ "Description" SG_ 997 PDW_FrRtWrngLvlDis "-Front Right display";
BA_ "GenSigSendType" SG_ 997 PDW_FrRtWrngLvlDis 4;
BA_ "UserSigValidity" SG_ 997 PDW_FrRtWrngLvlDis 0;
BA_ "NetworkRequest" SG_ 997 PDW_FrRtWrngLvlDis 0;
BA_ "NetworkRequestHoldingTime" SG_ 997 PDW_FrRtWrngLvlDis 5000;
BA_ "Version" SG_ 997 PDW_FrRtWrngLvlDis "21.03.09";
BA_ "Description" SG_ 997 PU_F_Group7_DrvrAsstFlr11Sta "PDW Blockage / Failure Display (Full Pop-up)";
BA_ "GenSigSendType" SG_ 997 PU_F_Group7_DrvrAsstFlr11Sta 4;
BA_ "UserSigValidity" SG_ 997 PU_F_Group7_DrvrAsstFlr11Sta 3;
BA_ "Version" SG_ 997 PU_F_Group7_DrvrAsstFlr11Sta "22.01.06";
BA_ "Description" SG_ 997 PDW_FrSnsrWrngLvlSta "-Front Sensor warning";
BA_ "GenSigSendType" SG_ 997 PDW_FrSnsrWrngLvlSta 4;
BA_ "UserSigValidity" SG_ 997 PDW_FrSnsrWrngLvlSta 0;
BA_ "NetworkRequest" SG_ 997 PDW_FrSnsrWrngLvlSta 0;
BA_ "NetworkRequestHoldingTime" SG_ 997 PDW_FrSnsrWrngLvlSta 5000;
BA_ "Version" SG_ 997 PDW_FrSnsrWrngLvlSta "17.12.00";
BA_ "GenMsgSendType" BO_ 1002 0;
BA_ "Description" SG_ 1002 BLTN_CAM_HU_UI_Mode "Display control of Built-in Cam UI mode. This Signal for Ethernet Type Built-in Cam.";
BA_ "GenSigSendType" SG_ 1002 BLTN_CAM_HU_UI_Mode 4;
BA_ "UserSigValidity" SG_ 1002 BLTN_CAM_HU_UI_Mode 0;
BA_REL_ "GenSigTimeoutTime" BU_SG_REL_ CGW_CCU SG_ 1002 BLTN_CAM_HU_UI_Mode 1500;
BA_ "Version" SG_ 1002 BLTN_CAM_HU_UI_Mode "22.05.02";
BA_ "Description" SG_ 1002 BLTN_CAM_SD_Format_Op_State "BLTN_CAM SD card format operation status.";
BA_ "GenSigSendType" SG_ 1002 BLTN_CAM_SD_Format_Op_State 4;
BA_ "UserSigValidity" SG_ 1002 BLTN_CAM_SD_Format_Op_State 1;
BA_REL_ "GenSigTimeoutTime" BU_SG_REL_ CGW_CCU SG_ 1002 BLTN_CAM_SD_Format_Op_State 1500;
BA_ "Version" SG_ 1002 BLTN_CAM_SD_Format_Op_State "21.07.04";
BA_ "Description" SG_ 1002 BLTN_CAM_PEV_Recorded "This Signal is sent just after the park event recorded.";
BA_ "GenSigSendType" SG_ 1002 BLTN_CAM_PEV_Recorded 4;
BA_ "UserSigValidity" SG_ 1002 BLTN_CAM_PEV_Recorded 1;
BA_REL_ "GenSigTimeoutTime" BU_SG_REL_ CGW_CCU SG_ 1002 BLTN_CAM_PEV_Recorded 1500;
BA_ "NetworkRequest" SG_ 1002 BLTN_CAM_PEV_Recorded 0;
BA_ "NetworkRequestHoldingTime" SG_ 1002 BLTN_CAM_PEV_Recorded 1000;
BA_ "Version" SG_ 1002 BLTN_CAM_PEV_Recorded "21.12.00";
BA_ "Description" SG_ 1002 BLTN_CAM_PEV_Count "This Signal is count of park event record.";
BA_ "GenSigSendType" SG_ 1002 BLTN_CAM_PEV_Count 4;
BA_ "UserSigValidity" SG_ 1002 BLTN_CAM_PEV_Count 1;
BA_REL_ "GenSigTimeoutTime" BU_SG_REL_ CGW_CCU SG_ 1002 BLTN_CAM_PEV_Count 1500;
BA_ "NetworkRequest" SG_ 1002 BLTN_CAM_PEV_Count 0;
BA_ "NetworkRequestHoldingTime" SG_ 1002 BLTN_CAM_PEV_Count 1000;
BA_ "Version" SG_ 1002 BLTN_CAM_PEV_Count "21.12.00";
BA_ "Description" SG_ 1002 BLTN_CAM_Ind_Req "This Signal is for HU Display Built-in Cam Indicator.";
BA_ "GenSigSendType" SG_ 1002 BLTN_CAM_Ind_Req 4;
BA_ "UserSigValidity" SG_ 1002 BLTN_CAM_Ind_Req 1;
BA_REL_ "GenSigTimeoutTime" BU_SG_REL_ CGW_CCU SG_ 1002 BLTN_CAM_Ind_Req 1500;
BA_ "Version" SG_ 1002 BLTN_CAM_Ind_Req "22.11.00";
BA_ "Description" SG_ 1002 BLTN_CAM_LVDS_Mode_State "This Signal is for LVDS output status";
BA_ "GenSigSendType" SG_ 1002 BLTN_CAM_LVDS_Mode_State 4;
BA_ "UserSigValidity" SG_ 1002 BLTN_CAM_LVDS_Mode_State 1;
BA_REL_ "GenSigTimeoutTime" BU_SG_REL_ CGW_CCU SG_ 1002 BLTN_CAM_LVDS_Mode_State 1500;
BA_ "Version" SG_ 1002 BLTN_CAM_LVDS_Mode_State "21.07.04";
BA_ "Description" SG_ 1002 BLTN_CAM_PrkOp_Termiate_Info "The signal for CCS service related with Built-in Cam Park operation termination.";
BA_ "GenSigSendType" SG_ 1002 BLTN_CAM_PrkOp_Termiate_Info 4;
BA_ "UserSigValidity" SG_ 1002 BLTN_CAM_PrkOp_Termiate_Info 0;
BA_REL_ "GenSigTimeoutTime" BU_SG_REL_ CGW_CCU SG_ 1002 BLTN_CAM_PrkOp_Termiate_Info 1500;
BA_ "NetworkRequest" SG_ 1002 BLTN_CAM_PrkOp_Termiate_Info 0;
BA_ "NetworkRequestHoldingTime" SG_ 1002 BLTN_CAM_PrkOp_Termiate_Info 1000;
BA_ "Version" SG_ 1002 BLTN_CAM_PrkOp_Termiate_Info "21.12.00";
BA_ "Description" SG_ 1002 BLTN_CAM_DEV_Recorded "This Signal is sent just after the drive event recorded.";
BA_ "GenSigSendType" SG_ 1002 BLTN_CAM_DEV_Recorded 4;
BA_ "UserSigValidity" SG_ 1002 BLTN_CAM_DEV_Recorded 1;
BA_REL_ "GenSigTimeoutTime" BU_SG_REL_ CGW_CCU SG_ 1002 BLTN_CAM_DEV_Recorded 1500;
BA_ "NetworkRequest" SG_ 1002 BLTN_CAM_DEV_Recorded 0;
BA_ "NetworkRequestHoldingTime" SG_ 1002 BLTN_CAM_DEV_Recorded 1000;
BA_ "Version" SG_ 1002 BLTN_CAM_DEV_Recorded "23.04.02";
BA_ "Description" SG_ 1002 BLTN_CAM_DEV_Count "This Signal is count of drive event record.";
BA_ "GenSigSendType" SG_ 1002 BLTN_CAM_DEV_Count 4;
BA_ "UserSigValidity" SG_ 1002 BLTN_CAM_DEV_Count 1;
BA_REL_ "GenSigTimeoutTime" BU_SG_REL_ CGW_CCU SG_ 1002 BLTN_CAM_DEV_Count 1500;
BA_ "NetworkRequest" SG_ 1002 BLTN_CAM_DEV_Count 0;
BA_ "NetworkRequestHoldingTime" SG_ 1002 BLTN_CAM_DEV_Count 1000;
BA_ "Version" SG_ 1002 BLTN_CAM_DEV_Count "23.04.02";
BA_ "Description" SG_ 1002 BLTN_CAM_Display "Display control of Built-in Cam UI mode. This Signal for CAN Type Built-in Cam.(with Standard 5th Wide AVNT)";
BA_ "GenSigSendType" SG_ 1002 BLTN_CAM_Display 4;
BA_ "UserSigValidity" SG_ 1002 BLTN_CAM_Display 1;
BA_REL_ "GenSigTimeoutTime" BU_SG_REL_ CGW_CCU SG_ 1002 BLTN_CAM_Display 1500;
BA_ "Version" SG_ 1002 BLTN_CAM_Display "21.07.04";
BA_ "Description" SG_ 1002 BLTN_CAM_WiFi_State "BLTN_CAM WiFi Stattus";
BA_ "GenSigSendType" SG_ 1002 BLTN_CAM_WiFi_State 4;
BA_ "UserSigValidity" SG_ 1002 BLTN_CAM_WiFi_State 1;
BA_REL_ "GenSigTimeoutTime" BU_SG_REL_ CGW_CCU SG_ 1002 BLTN_CAM_WiFi_State 1500;
BA_ "Version" SG_ 1002 BLTN_CAM_WiFi_State "21.07.04";
BA_ "GenMsgSendType" BO_ 2353206529 0;
BA_ "GenMsgCycleTimeFast" BO_ 2353206529 0;
BA_ "GenMsgNrOfRepetition" BO_ 2353206529 0;
BA_ "VFrameFormat" BO_ 2353206529 1;
BA_ "Description" SG_ 2353206529 CLU_Crc20Val "The data area for CRC calculation is based on the data length (DLC) of the message DB.

The CRC shall be calculated over the entire data block (excluding the CRC bytes) including the user data, alive counter and Data ID



- CRC Polynomial (0x1021) , Initial Value : 0xFFFF, XOR value : 0x0000, Data ID : Message ID + 0xF800 

- The initial value is for CRC calculation and the message should be sent with the calculated result value. 

- The mathematical expression to 16 bit CRC polynomial is given here. G(x) = x16 + x12 + x5 + 1



<For CRC calculation of CAN-FD Msg for HS CAN domain ECUs>



- HS-CAN Messages that routed from CAN-FD domain are using 29 bit Extended CAN ID and splitted into 8 Byte Messages.

(from 1 to 4 Msgs, depending on source CAN-FD Msg¡¯s DLC)

- For splitted CAN-FD Msgs¡¯ CRC calculation, HS CAN ECUs should use source CAN-FD Msg¡¯s original STD ID. 

- The original STD ID can be read from Ext ID¡¯s 4~6th Byte.

Eg. STD 0x6AA : EXT SPLT 0x1A8[6AA]01 / 0x1A8[6AA]02 / 0x1A8[6AA]03 / 0x1A8[6AA]04 

(2~4th splitited Msgs can be omitted depending on source CAN-FD Msg¡¯s DLC)

- Aslo, HS-CAN ECUs should use merged data block (from whole splitted Msg) for CRC calculation.";
BA_ "GenSigStartValue" SG_ 2353206529 CLU_Crc20Val 65535;
BA_ "UserSigValidity" SG_ 2353206529 CLU_Crc20Val 3;
BA_ "Version" SG_ 2353206529 CLU_Crc20Val "21.09.03";
BA_ "Description" SG_ 2353206529 CLU_AlvCnt20Val "For the first transmission request for a data element the counter shall be initialized with 0 and shall be incremented by 1 for every subsequent send request. 

When the counter reaches the maximum value(0xFF), then it shall restart with 0 for the next send request";
BA_ "UserSigValidity" SG_ 2353206529 CLU_AlvCnt20Val 3;
BA_ "Version" SG_ 2353206529 CLU_AlvCnt20Val "21.09.03";
BA_ "Description" SG_ 2353206529 CLU_SndType "This signal is for sound type of Cluster.

The Cluster applied buzzer is can generate only on channel sound

and the Cluster applied speaker can generate multi channel sound.";
BA_ "UserSigValidity" SG_ 2353206529 CLU_SndType 3;
BA_ "Version" SG_ 2353206529 CLU_SndType "19.01.08";
BA_ "UserSigValidity" SG_ 2353206529 USM_AdasHDPSetReq 3;
BA_ "Version" SG_ 2353206529 USM_AdasHDPSetReq "23.02.02";
BA_ "Description" SG_ 2353206529 CLU_ClusterUSM "USM application of Cluster

If USM is applied in Cluster, Signal send 0x1";
BA_ "UserSigValidity" SG_ 2353206529 CLU_ClusterUSM 3;
BA_REL_ "GenSigTimeoutTime" BU_SG_REL_ WPC SG_ 2353206529 CLU_ClusterUSM 1500;
BA_REL_ "GenSigTimeoutTime" BU_SG_REL_ WPC2 SG_ 2353206529 CLU_ClusterUSM 1500;
BA_ "Version" SG_ 2353206529 CLU_ClusterUSM "20.06.05";
BA_ "GenMsgSendType" BO_ 2353206530 0;
BA_ "GenMsgCycleTimeFast" BO_ 2353206530 0;
BA_ "GenMsgNrOfRepetition" BO_ 2353206530 0;
BA_ "VFrameFormat" BO_ 2353206530 1;
BA_ "GenMsgCycleTime" BO_ 1963 0;
BA_ "GenMsgCycleTimeFast" BO_ 1963 0;
BA_ "GenMsgNrOfRepetition" BO_ 1963 0;
BA_ "DiagResponse" BO_ 1963 1;
BA_ "GenMsgILSupport" BO_ 1963 0;
BA_ "TpMessage" BO_ 1963 1;
BA_ "TpTxIndex" BO_ 1963 156;
BA_ "Description" SG_ 1963 DPSU_PSU_DRV_GST_Byte0 "TP Index : 156";
BA_ "UsrSigPurpose" SG_ 1963 DPSU_PSU_DRV_GST_Byte0 4;
BA_ "UserSigValidity" SG_ 1963 DPSU_PSU_DRV_GST_Byte0 0;
BA_REL_ "GenSigTimeoutTime" BU_SG_REL_ CGW_CCU SG_ 1963 DPSU_PSU_DRV_GST_Byte0 0;
BA_ "NetworkRequest" SG_ 1963 DPSU_PSU_DRV_GST_Byte0 0;
BA_ "NetworkRequestHoldingTime" SG_ 1963 DPSU_PSU_DRV_GST_Byte0 5000;
BA_ "Version" SG_ 1963 DPSU_PSU_DRV_GST_Byte0 "22.11.14";
BA_ "Description" SG_ 1963 DPSU_PSU_DRV_GST_Byte2 "TP Index : 156";
BA_ "UsrSigPurpose" SG_ 1963 DPSU_PSU_DRV_GST_Byte2 4;
BA_ "UserSigValidity" SG_ 1963 DPSU_PSU_DRV_GST_Byte2 0;
BA_REL_ "GenSigTimeoutTime" BU_SG_REL_ CGW_CCU SG_ 1963 DPSU_PSU_DRV_GST_Byte2 0;
BA_ "NetworkRequest" SG_ 1963 DPSU_PSU_DRV_GST_Byte2 0;
BA_ "NetworkRequestHoldingTime" SG_ 1963 DPSU_PSU_DRV_GST_Byte2 5000;
BA_ "Version" SG_ 1963 DPSU_PSU_DRV_GST_Byte2 "22.11.14";
BA_ "Description" SG_ 1963 DPSU_PSU_DRV_GST_Byte3 "TP Index : 156";
BA_ "UsrSigPurpose" SG_ 1963 DPSU_PSU_DRV_GST_Byte3 4;
BA_ "UserSigValidity" SG_ 1963 DPSU_PSU_DRV_GST_Byte3 0;
BA_REL_ "GenSigTimeoutTime" BU_SG_REL_ CGW_CCU SG_ 1963 DPSU_PSU_DRV_GST_Byte3 0;
BA_ "NetworkRequest" SG_ 1963 DPSU_PSU_DRV_GST_Byte3 0;
BA_ "NetworkRequestHoldingTime" SG_ 1963 DPSU_PSU_DRV_GST_Byte3 5000;
BA_ "Version" SG_ 1963 DPSU_PSU_DRV_GST_Byte3 "22.11.14";
BA_ "Description" SG_ 1963 DPSU_PSU_DRV_GST_Byte4 "TP Index : 156";
BA_ "UsrSigPurpose" SG_ 1963 DPSU_PSU_DRV_GST_Byte4 4;
BA_ "UserSigValidity" SG_ 1963 DPSU_PSU_DRV_GST_Byte4 0;
BA_REL_ "GenSigTimeoutTime" BU_SG_REL_ CGW_CCU SG_ 1963 DPSU_PSU_DRV_GST_Byte4 0;
BA_ "NetworkRequest" SG_ 1963 DPSU_PSU_DRV_GST_Byte4 0;
BA_ "NetworkRequestHoldingTime" SG_ 1963 DPSU_PSU_DRV_GST_Byte4 5000;
BA_ "Version" SG_ 1963 DPSU_PSU_DRV_GST_Byte4 "22.11.14";
BA_ "Description" SG_ 1963 DPSU_PSU_DRV_GST_Byte5 "TP Index : 156";
BA_ "UsrSigPurpose" SG_ 1963 DPSU_PSU_DRV_GST_Byte5 4;
BA_ "UserSigValidity" SG_ 1963 DPSU_PSU_DRV_GST_Byte5 0;
BA_REL_ "GenSigTimeoutTime" BU_SG_REL_ CGW_CCU SG_ 1963 DPSU_PSU_DRV_GST_Byte5 0;
BA_ "NetworkRequest" SG_ 1963 DPSU_PSU_DRV_GST_Byte5 0;
BA_ "NetworkRequestHoldingTime" SG_ 1963 DPSU_PSU_DRV_GST_Byte5 5000;
BA_ "Version" SG_ 1963 DPSU_PSU_DRV_GST_Byte5 "22.11.14";
BA_ "Description" SG_ 1963 DPSU_PSU_DRV_GST_Byte6 "TP Index : 156";
BA_ "UsrSigPurpose" SG_ 1963 DPSU_PSU_DRV_GST_Byte6 4;
BA_ "UserSigValidity" SG_ 1963 DPSU_PSU_DRV_GST_Byte6 0;
BA_REL_ "GenSigTimeoutTime" BU_SG_REL_ CGW_CCU SG_ 1963 DPSU_PSU_DRV_GST_Byte6 0;
BA_ "NetworkRequest" SG_ 1963 DPSU_PSU_DRV_GST_Byte6 0;
BA_ "NetworkRequestHoldingTime" SG_ 1963 DPSU_PSU_DRV_GST_Byte6 5000;
BA_ "Version" SG_ 1963 DPSU_PSU_DRV_GST_Byte6 "22.11.14";
BA_ "Description" SG_ 1963 DPSU_PSU_DRV_GST_Byte7 "TP Index : 156";
BA_ "UsrSigPurpose" SG_ 1963 DPSU_PSU_DRV_GST_Byte7 4;
BA_ "UserSigValidity" SG_ 1963 DPSU_PSU_DRV_GST_Byte7 0;
BA_REL_ "GenSigTimeoutTime" BU_SG_REL_ CGW_CCU SG_ 1963 DPSU_PSU_DRV_GST_Byte7 0;
BA_ "NetworkRequest" SG_ 1963 DPSU_PSU_DRV_GST_Byte7 0;
BA_ "NetworkRequestHoldingTime" SG_ 1963 DPSU_PSU_DRV_GST_Byte7 5000;
BA_ "Version" SG_ 1963 DPSU_PSU_DRV_GST_Byte7 "22.11.14";
BA_ "Description" SG_ 1963 DPSU_PSU_DRV_GST_Byte1 "TP Index : 156";
BA_ "UsrSigPurpose" SG_ 1963 DPSU_PSU_DRV_GST_Byte1 4;
BA_ "UserSigValidity" SG_ 1963 DPSU_PSU_DRV_GST_Byte1 0;
BA_REL_ "GenSigTimeoutTime" BU_SG_REL_ CGW_CCU SG_ 1963 DPSU_PSU_DRV_GST_Byte1 0;
BA_ "NetworkRequest" SG_ 1963 DPSU_PSU_DRV_GST_Byte1 0;
BA_ "NetworkRequestHoldingTime" SG_ 1963 DPSU_PSU_DRV_GST_Byte1 5000;
BA_ "Version" SG_ 1963 DPSU_PSU_DRV_GST_Byte1 "22.11.14";
BA_ "GenMsgCycleTime" BO_ 1955 0;
BA_ "GenMsgCycleTimeFast" BO_ 1955 0;
BA_ "GenMsgNrOfRepetition" BO_ 1955 0;
BA_ "DiagRequest" BO_ 1955 1;
BA_ "GenMsgILSupport" BO_ 1955 0;
BA_ "TpMessage" BO_ 1955 1;
BA_ "TpTxIndex" BO_ 1955 156;
BA_ "Description" SG_ 1955 GST_DPSU_PSU_DRV_Byte0 "TP Index : 156";
BA_ "UsrSigPurpose" SG_ 1955 GST_DPSU_PSU_DRV_Byte0 3;
BA_ "UserSigValidity" SG_ 1955 GST_DPSU_PSU_DRV_Byte0 0;
BA_REL_ "GenSigTimeoutTime" BU_SG_REL_ GW_DPSU SG_ 1955 GST_DPSU_PSU_DRV_Byte0 0;
BA_ "NetworkRequest" SG_ 1955 GST_DPSU_PSU_DRV_Byte0 0;
BA_ "NetworkRequestHoldingTime" SG_ 1955 GST_DPSU_PSU_DRV_Byte0 5000;
BA_ "Version" SG_ 1955 GST_DPSU_PSU_DRV_Byte0 "22.11.14";
BA_ "Description" SG_ 1955 GST_DPSU_PSU_DRV_Byte2 "TP Index : 156";
BA_ "UsrSigPurpose" SG_ 1955 GST_DPSU_PSU_DRV_Byte2 3;
BA_ "UserSigValidity" SG_ 1955 GST_DPSU_PSU_DRV_Byte2 0;
BA_REL_ "GenSigTimeoutTime" BU_SG_REL_ GW_DPSU SG_ 1955 GST_DPSU_PSU_DRV_Byte2 0;
BA_ "NetworkRequest" SG_ 1955 GST_DPSU_PSU_DRV_Byte2 0;
BA_ "NetworkRequestHoldingTime" SG_ 1955 GST_DPSU_PSU_DRV_Byte2 5000;
BA_ "Version" SG_ 1955 GST_DPSU_PSU_DRV_Byte2 "22.11.14";
BA_ "Description" SG_ 1955 GST_DPSU_PSU_DRV_Byte3 "TP Index : 156";
BA_ "UsrSigPurpose" SG_ 1955 GST_DPSU_PSU_DRV_Byte3 3;
BA_ "UserSigValidity" SG_ 1955 GST_DPSU_PSU_DRV_Byte3 0;
BA_REL_ "GenSigTimeoutTime" BU_SG_REL_ GW_DPSU SG_ 1955 GST_DPSU_PSU_DRV_Byte3 0;
BA_ "NetworkRequest" SG_ 1955 GST_DPSU_PSU_DRV_Byte3 0;
BA_ "NetworkRequestHoldingTime" SG_ 1955 GST_DPSU_PSU_DRV_Byte3 5000;
BA_ "Version" SG_ 1955 GST_DPSU_PSU_DRV_Byte3 "22.11.14";
BA_ "Description" SG_ 1955 GST_DPSU_PSU_DRV_Byte4 "TP Index : 156";
BA_ "UsrSigPurpose" SG_ 1955 GST_DPSU_PSU_DRV_Byte4 3;
BA_ "UserSigValidity" SG_ 1955 GST_DPSU_PSU_DRV_Byte4 0;
BA_REL_ "GenSigTimeoutTime" BU_SG_REL_ GW_DPSU SG_ 1955 GST_DPSU_PSU_DRV_Byte4 0;
BA_ "NetworkRequest" SG_ 1955 GST_DPSU_PSU_DRV_Byte4 0;
BA_ "NetworkRequestHoldingTime" SG_ 1955 GST_DPSU_PSU_DRV_Byte4 5000;
BA_ "Version" SG_ 1955 GST_DPSU_PSU_DRV_Byte4 "22.11.14";
BA_ "Description" SG_ 1955 GST_DPSU_PSU_DRV_Byte5 "TP Index : 156";
BA_ "UsrSigPurpose" SG_ 1955 GST_DPSU_PSU_DRV_Byte5 3;
BA_ "UserSigValidity" SG_ 1955 GST_DPSU_PSU_DRV_Byte5 0;
BA_REL_ "GenSigTimeoutTime" BU_SG_REL_ GW_DPSU SG_ 1955 GST_DPSU_PSU_DRV_Byte5 0;
BA_ "NetworkRequest" SG_ 1955 GST_DPSU_PSU_DRV_Byte5 0;
BA_ "NetworkRequestHoldingTime" SG_ 1955 GST_DPSU_PSU_DRV_Byte5 5000;
BA_ "Version" SG_ 1955 GST_DPSU_PSU_DRV_Byte5 "22.11.14";
BA_ "Description" SG_ 1955 GST_DPSU_PSU_DRV_Byte6 "TP Index : 156";
BA_ "UsrSigPurpose" SG_ 1955 GST_DPSU_PSU_DRV_Byte6 3;
BA_ "UserSigValidity" SG_ 1955 GST_DPSU_PSU_DRV_Byte6 0;
BA_REL_ "GenSigTimeoutTime" BU_SG_REL_ GW_DPSU SG_ 1955 GST_DPSU_PSU_DRV_Byte6 0;
BA_ "NetworkRequest" SG_ 1955 GST_DPSU_PSU_DRV_Byte6 0;
BA_ "NetworkRequestHoldingTime" SG_ 1955 GST_DPSU_PSU_DRV_Byte6 5000;
BA_ "Version" SG_ 1955 GST_DPSU_PSU_DRV_Byte6 "22.11.14";
BA_ "Description" SG_ 1955 GST_DPSU_PSU_DRV_Byte7 "TP Index : 156";
BA_ "UsrSigPurpose" SG_ 1955 GST_DPSU_PSU_DRV_Byte7 3;
BA_ "UserSigValidity" SG_ 1955 GST_DPSU_PSU_DRV_Byte7 0;
BA_REL_ "GenSigTimeoutTime" BU_SG_REL_ GW_DPSU SG_ 1955 GST_DPSU_PSU_DRV_Byte7 0;
BA_ "NetworkRequest" SG_ 1955 GST_DPSU_PSU_DRV_Byte7 0;
BA_ "NetworkRequestHoldingTime" SG_ 1955 GST_DPSU_PSU_DRV_Byte7 5000;
BA_ "Version" SG_ 1955 GST_DPSU_PSU_DRV_Byte7 "22.11.14";
BA_ "Description" SG_ 1955 GST_DPSU_PSU_DRV_Byte1 "TP Index : 156";
BA_ "UsrSigPurpose" SG_ 1955 GST_DPSU_PSU_DRV_Byte1 3;
BA_ "UserSigValidity" SG_ 1955 GST_DPSU_PSU_DRV_Byte1 0;
BA_REL_ "GenSigTimeoutTime" BU_SG_REL_ GW_DPSU SG_ 1955 GST_DPSU_PSU_DRV_Byte1 0;
BA_ "NetworkRequest" SG_ 1955 GST_DPSU_PSU_DRV_Byte1 0;
BA_ "NetworkRequestHoldingTime" SG_ 1955 GST_DPSU_PSU_DRV_Byte1 5000;
BA_ "Version" SG_ 1955 GST_DPSU_PSU_DRV_Byte1 "22.11.14";
BA_ "GenMsgCycleTime" BO_ 1956 0;
BA_ "GenMsgCycleTimeFast" BO_ 1956 0;
BA_ "GenMsgNrOfRepetition" BO_ 1956 0;
BA_ "DiagRequest" BO_ 1956 1;
BA_ "GenMsgILSupport" BO_ 1956 0;
BA_ "TpMessage" BO_ 1956 1;
BA_ "TpTxIndex" BO_ 1956 172;
BA_ "Description" SG_ 1956 GST_SCM_Byte0 "TP Index : 172";
BA_ "UsrSigPurpose" SG_ 1956 GST_SCM_Byte0 3;
BA_ "UserSigValidity" SG_ 1956 GST_SCM_Byte0 0;
BA_REL_ "GenSigTimeoutTime" BU_SG_REL_ SCM SG_ 1956 GST_SCM_Byte0 0;
BA_ "NetworkRequest" SG_ 1956 GST_SCM_Byte0 0;
BA_ "NetworkRequestHoldingTime" SG_ 1956 GST_SCM_Byte0 5000;
BA_ "Version" SG_ 1956 GST_SCM_Byte0 "21.02.04";
BA_ "Description" SG_ 1956 GST_SCM_Byte2 "TP Index : 172";
BA_ "UsrSigPurpose" SG_ 1956 GST_SCM_Byte2 3;
BA_ "UserSigValidity" SG_ 1956 GST_SCM_Byte2 0;
BA_REL_ "GenSigTimeoutTime" BU_SG_REL_ SCM SG_ 1956 GST_SCM_Byte2 0;
BA_ "NetworkRequest" SG_ 1956 GST_SCM_Byte2 0;
BA_ "NetworkRequestHoldingTime" SG_ 1956 GST_SCM_Byte2 5000;
BA_ "Version" SG_ 1956 GST_SCM_Byte2 "21.02.04";
BA_ "Description" SG_ 1956 GST_SCM_Byte3 "TP Index : 172";
BA_ "UsrSigPurpose" SG_ 1956 GST_SCM_Byte3 3;
BA_ "UserSigValidity" SG_ 1956 GST_SCM_Byte3 0;
BA_REL_ "GenSigTimeoutTime" BU_SG_REL_ SCM SG_ 1956 GST_SCM_Byte3 0;
BA_ "NetworkRequest" SG_ 1956 GST_SCM_Byte3 0;
BA_ "NetworkRequestHoldingTime" SG_ 1956 GST_SCM_Byte3 5000;
BA_ "Version" SG_ 1956 GST_SCM_Byte3 "21.02.04";
BA_ "Description" SG_ 1956 GST_SCM_Byte4 "TP Index : 172";
BA_ "UsrSigPurpose" SG_ 1956 GST_SCM_Byte4 3;
BA_ "UserSigValidity" SG_ 1956 GST_SCM_Byte4 0;
BA_REL_ "GenSigTimeoutTime" BU_SG_REL_ SCM SG_ 1956 GST_SCM_Byte4 0;
BA_ "NetworkRequest" SG_ 1956 GST_SCM_Byte4 0;
BA_ "NetworkRequestHoldingTime" SG_ 1956 GST_SCM_Byte4 5000;
BA_ "Version" SG_ 1956 GST_SCM_Byte4 "21.02.04";
BA_ "Description" SG_ 1956 GST_SCM_Byte5 "TP Index : 172";
BA_ "UsrSigPurpose" SG_ 1956 GST_SCM_Byte5 3;
BA_ "UserSigValidity" SG_ 1956 GST_SCM_Byte5 0;
BA_REL_ "GenSigTimeoutTime" BU_SG_REL_ SCM SG_ 1956 GST_SCM_Byte5 0;
BA_ "NetworkRequest" SG_ 1956 GST_SCM_Byte5 0;
BA_ "NetworkRequestHoldingTime" SG_ 1956 GST_SCM_Byte5 5000;
BA_ "Version" SG_ 1956 GST_SCM_Byte5 "21.02.04";
BA_ "Description" SG_ 1956 GST_SCM_Byte6 "TP Index : 172";
BA_ "UsrSigPurpose" SG_ 1956 GST_SCM_Byte6 3;
BA_ "UserSigValidity" SG_ 1956 GST_SCM_Byte6 0;
BA_REL_ "GenSigTimeoutTime" BU_SG_REL_ SCM SG_ 1956 GST_SCM_Byte6 0;
BA_ "NetworkRequest" SG_ 1956 GST_SCM_Byte6 0;
BA_ "NetworkRequestHoldingTime" SG_ 1956 GST_SCM_Byte6 5000;
BA_ "Version" SG_ 1956 GST_SCM_Byte6 "21.02.04";
BA_ "Description" SG_ 1956 GST_SCM_Byte7 "TP Index : 172";
BA_ "UsrSigPurpose" SG_ 1956 GST_SCM_Byte7 3;
BA_ "UserSigValidity" SG_ 1956 GST_SCM_Byte7 0;
BA_REL_ "GenSigTimeoutTime" BU_SG_REL_ SCM SG_ 1956 GST_SCM_Byte7 0;
BA_ "NetworkRequest" SG_ 1956 GST_SCM_Byte7 0;
BA_ "NetworkRequestHoldingTime" SG_ 1956 GST_SCM_Byte7 5000;
BA_ "Version" SG_ 1956 GST_SCM_Byte7 "21.02.04";
BA_ "Description" SG_ 1956 GST_SCM_Byte1 "TP Index : 172";
BA_ "UsrSigPurpose" SG_ 1956 GST_SCM_Byte1 3;
BA_ "UserSigValidity" SG_ 1956 GST_SCM_Byte1 0;
BA_REL_ "GenSigTimeoutTime" BU_SG_REL_ SCM SG_ 1956 GST_SCM_Byte1 0;
BA_ "NetworkRequest" SG_ 1956 GST_SCM_Byte1 0;
BA_ "NetworkRequestHoldingTime" SG_ 1956 GST_SCM_Byte1 5000;
BA_ "Version" SG_ 1956 GST_SCM_Byte1 "21.02.04";
BA_ "GenMsgCycleTime" BO_ 1959 0;
BA_ "GenMsgCycleTimeFast" BO_ 1959 0;
BA_ "GenMsgNrOfRepetition" BO_ 1959 0;
BA_ "DiagRequest" BO_ 1959 1;
BA_ "GenMsgILSupport" BO_ 1959 0;
BA_ "TpMessage" BO_ 1959 1;
BA_ "TpTxIndex" BO_ 1959 175;
BA_ "Description" SG_ 1959 GST_SWRC_Byte0 "TP Index : 175";
BA_ "UsrSigPurpose" SG_ 1959 GST_SWRC_Byte0 3;
BA_ "UserSigValidity" SG_ 1959 GST_SWRC_Byte0 0;
BA_REL_ "GenSigTimeoutTime" BU_SG_REL_ SWRC SG_ 1959 GST_SWRC_Byte0 0;
BA_ "NetworkRequest" SG_ 1959 GST_SWRC_Byte0 0;
BA_ "NetworkRequestHoldingTime" SG_ 1959 GST_SWRC_Byte0 5000;
BA_ "Version" SG_ 1959 GST_SWRC_Byte0 "21.02.04";
BA_ "Description" SG_ 1959 GST_SWRC_Byte2 "TP Index : 175";
BA_ "UsrSigPurpose" SG_ 1959 GST_SWRC_Byte2 3;
BA_ "UserSigValidity" SG_ 1959 GST_SWRC_Byte2 0;
BA_REL_ "GenSigTimeoutTime" BU_SG_REL_ SWRC SG_ 1959 GST_SWRC_Byte2 0;
BA_ "NetworkRequest" SG_ 1959 GST_SWRC_Byte2 0;
BA_ "NetworkRequestHoldingTime" SG_ 1959 GST_SWRC_Byte2 5000;
BA_ "Version" SG_ 1959 GST_SWRC_Byte2 "21.02.04";
BA_ "Description" SG_ 1959 GST_SWRC_Byte3 "TP Index : 175";
BA_ "UsrSigPurpose" SG_ 1959 GST_SWRC_Byte3 3;
BA_ "UserSigValidity" SG_ 1959 GST_SWRC_Byte3 0;
BA_REL_ "GenSigTimeoutTime" BU_SG_REL_ SWRC SG_ 1959 GST_SWRC_Byte3 0;
BA_ "NetworkRequest" SG_ 1959 GST_SWRC_Byte3 0;
BA_ "NetworkRequestHoldingTime" SG_ 1959 GST_SWRC_Byte3 5000;
BA_ "Version" SG_ 1959 GST_SWRC_Byte3 "21.02.04";
BA_ "Description" SG_ 1959 GST_SWRC_Byte4 "TP Index : 175";
BA_ "UsrSigPurpose" SG_ 1959 GST_SWRC_Byte4 3;
BA_ "UserSigValidity" SG_ 1959 GST_SWRC_Byte4 0;
BA_REL_ "GenSigTimeoutTime" BU_SG_REL_ SWRC SG_ 1959 GST_SWRC_Byte4 0;
BA_ "NetworkRequest" SG_ 1959 GST_SWRC_Byte4 0;
BA_ "NetworkRequestHoldingTime" SG_ 1959 GST_SWRC_Byte4 5000;
BA_ "Version" SG_ 1959 GST_SWRC_Byte4 "21.02.04";
BA_ "Description" SG_ 1959 GST_SWRC_Byte5 "TP Index : 175";
BA_ "UsrSigPurpose" SG_ 1959 GST_SWRC_Byte5 3;
BA_ "UserSigValidity" SG_ 1959 GST_SWRC_Byte5 0;
BA_REL_ "GenSigTimeoutTime" BU_SG_REL_ SWRC SG_ 1959 GST_SWRC_Byte5 0;
BA_ "NetworkRequest" SG_ 1959 GST_SWRC_Byte5 0;
BA_ "NetworkRequestHoldingTime" SG_ 1959 GST_SWRC_Byte5 5000;
BA_ "Version" SG_ 1959 GST_SWRC_Byte5 "21.02.04";
BA_ "Description" SG_ 1959 GST_SWRC_Byte6 "TP Index : 175";
BA_ "UsrSigPurpose" SG_ 1959 GST_SWRC_Byte6 3;
BA_ "UserSigValidity" SG_ 1959 GST_SWRC_Byte6 0;
BA_REL_ "GenSigTimeoutTime" BU_SG_REL_ SWRC SG_ 1959 GST_SWRC_Byte6 0;
BA_ "NetworkRequest" SG_ 1959 GST_SWRC_Byte6 0;
BA_ "NetworkRequestHoldingTime" SG_ 1959 GST_SWRC_Byte6 5000;
BA_ "Version" SG_ 1959 GST_SWRC_Byte6 "21.02.04";
BA_ "Description" SG_ 1959 GST_SWRC_Byte7 "TP Index : 175";
BA_ "UsrSigPurpose" SG_ 1959 GST_SWRC_Byte7 3;
BA_ "UserSigValidity" SG_ 1959 GST_SWRC_Byte7 0;
BA_REL_ "GenSigTimeoutTime" BU_SG_REL_ SWRC SG_ 1959 GST_SWRC_Byte7 0;
BA_ "NetworkRequest" SG_ 1959 GST_SWRC_Byte7 0;
BA_ "NetworkRequestHoldingTime" SG_ 1959 GST_SWRC_Byte7 5000;
BA_ "Version" SG_ 1959 GST_SWRC_Byte7 "21.02.04";
BA_ "Description" SG_ 1959 GST_SWRC_Byte1 "TP Index : 175";
BA_ "UsrSigPurpose" SG_ 1959 GST_SWRC_Byte1 3;
BA_ "UserSigValidity" SG_ 1959 GST_SWRC_Byte1 0;
BA_REL_ "GenSigTimeoutTime" BU_SG_REL_ SWRC SG_ 1959 GST_SWRC_Byte1 0;
BA_ "NetworkRequest" SG_ 1959 GST_SWRC_Byte1 0;
BA_ "NetworkRequestHoldingTime" SG_ 1959 GST_SWRC_Byte1 5000;
BA_ "Version" SG_ 1959 GST_SWRC_Byte1 "21.02.04";
BA_ "GenMsgSendType" BO_ 1015 0;
BA_ "GenMsgCycleTime" BO_ 1015 1000;
BA_ "GenMsgCycleTimeFast" BO_ 1015 0;
BA_ "GenMsgNrOfRepetition" BO_ 1015 0;
BA_ "Description" SG_ 1015 HU_MM_Altitude "MSL

range = -40000 <= Value <= 1000000

unit = cm";
BA_ "UserSigValidity" SG_ 1015 HU_MM_Altitude 1;
BA_REL_ "GenSigTimeoutTime" BU_SG_REL_ BLTN_CAM SG_ 1015 HU_MM_Altitude 5000;
BA_ "Version" SG_ 1015 HU_MM_Altitude "22.07.05";
BA_ "Description" SG_ 1015 HU_MM_Heading "range = 0<=Valud <360";
BA_ "UserSigValidity" SG_ 1015 HU_MM_Heading 1;
BA_REL_ "GenSigTimeoutTime" BU_SG_REL_ BLTN_CAM SG_ 1015 HU_MM_Heading 5000;
BA_ "Version" SG_ 1015 HU_MM_Heading "22.07.05";
BA_ "GenMsgSendType" BO_ 1016 0;
BA_ "GenMsgCycleTime" BO_ 1016 1000;
BA_ "GenMsgCycleTimeFast" BO_ 1016 0;
BA_ "GenMsgNrOfRepetition" BO_ 1016 0;
BA_ "GenSigStartValue" SG_ 1016 GNSS_MM_type 15;
BA_ "UserSigValidity" SG_ 1016 GNSS_MM_type 1;
BA_REL_ "GenSigTimeoutTime" BU_SG_REL_ BLTN_CAM SG_ 1016 GNSS_MM_type 5000;
BA_ "Version" SG_ 1016 GNSS_MM_type "22.07.05";
BA_ "GenMsgCycleTime" BO_ 1019 0;
BA_ "Description" SG_ 1019 HU_MoodTherapyDrSeat "Moodtherapy Driver Seat On/Off";
BA_ "GenSigSendType" SG_ 1019 HU_MoodTherapyDrSeat 4;
BA_ "UserSigValidity" SG_ 1019 HU_MoodTherapyDrSeat 3;
BA_REL_ "GenSigTimeoutTime" BU_SG_REL_ DSAU SG_ 1019 HU_MoodTherapyDrSeat 0;
BA_REL_ "GenSigTimeoutTime" BU_SG_REL_ GW_DLBCU SG_ 1019 HU_MoodTherapyDrSeat 0;
BA_ "RoutingFactor" SG_ 1019 HU_MoodTherapyDrSeat 0;
BA_ "Version" SG_ 1019 HU_MoodTherapyDrSeat "20.07.13";
BA_ "Description" SG_ 1019 HU_VitalityFragrance "Vitality Fragrance On/Off";
BA_ "GenSigSendType" SG_ 1019 HU_VitalityFragrance 4;
BA_ "UserSigValidity" SG_ 1019 HU_VitalityFragrance 3;
BA_ "RoutingFactor" SG_ 1019 HU_VitalityFragrance 0;
BA_ "Version" SG_ 1019 HU_VitalityFragrance "20.07.13";
BA_ "Description" SG_ 1019 HU_VitalityCurtain "Vitality Curtain On/Off";
BA_ "GenSigSendType" SG_ 1019 HU_VitalityCurtain 4;
BA_ "UserSigValidity" SG_ 1019 HU_VitalityCurtain 3;
BA_ "RoutingFactor" SG_ 1019 HU_VitalityCurtain 0;
BA_ "Version" SG_ 1019 HU_VitalityCurtain "20.07.13";
BA_ "Description" SG_ 1019 HU_DelightMoodLamp "Delight MoodLamp On/Off";
BA_ "GenSigSendType" SG_ 1019 HU_DelightMoodLamp 4;
BA_ "UserSigValidity" SG_ 1019 HU_DelightMoodLamp 3;
BA_ "RoutingFactor" SG_ 1019 HU_DelightMoodLamp 0;
BA_ "Version" SG_ 1019 HU_DelightMoodLamp "20.07.13";
BA_ "Description" SG_ 1019 HU_DelightFragrance "Delight Fragrance On/Off";
BA_ "GenSigSendType" SG_ 1019 HU_DelightFragrance 4;
BA_ "UserSigValidity" SG_ 1019 HU_DelightFragrance 3;
BA_ "RoutingFactor" SG_ 1019 HU_DelightFragrance 0;
BA_ "Version" SG_ 1019 HU_DelightFragrance "20.07.13";
BA_ "Description" SG_ 1019 HU_DelightCurtain "Delight Curtain On/Off";
BA_ "GenSigSendType" SG_ 1019 HU_DelightCurtain 4;
BA_ "UserSigValidity" SG_ 1019 HU_DelightCurtain 3;
BA_ "RoutingFactor" SG_ 1019 HU_DelightCurtain 0;
BA_ "Version" SG_ 1019 HU_DelightCurtain "20.07.13";
BA_ "Description" SG_ 1019 HU_MoodTherapyPsSeat "Moodtherapy Passenger Seat On/Off";
BA_ "GenSigSendType" SG_ 1019 HU_MoodTherapyPsSeat 4;
BA_ "UserSigValidity" SG_ 1019 HU_MoodTherapyPsSeat 3;
BA_REL_ "GenSigTimeoutTime" BU_SG_REL_ ALBCU SG_ 1019 HU_MoodTherapyPsSeat 0;
BA_REL_ "GenSigTimeoutTime" BU_SG_REL_ ASAU SG_ 1019 HU_MoodTherapyPsSeat 0;
BA_ "RoutingFactor" SG_ 1019 HU_MoodTherapyPsSeat 0;
BA_ "Version" SG_ 1019 HU_MoodTherapyPsSeat "20.07.13";
BA_ "Description" SG_ 1019 HU_CareMoodLamp "Care MoodLamp On/Off";
BA_ "GenSigSendType" SG_ 1019 HU_CareMoodLamp 4;
BA_ "UserSigValidity" SG_ 1019 HU_CareMoodLamp 3;
BA_ "RoutingFactor" SG_ 1019 HU_CareMoodLamp 0;
BA_ "Version" SG_ 1019 HU_CareMoodLamp "20.07.13";
BA_ "Description" SG_ 1019 HU_CareFragrance "Care Fragrance On/Off";
BA_ "GenSigSendType" SG_ 1019 HU_CareFragrance 4;
BA_ "UserSigValidity" SG_ 1019 HU_CareFragrance 3;
BA_ "RoutingFactor" SG_ 1019 HU_CareFragrance 0;
BA_ "Version" SG_ 1019 HU_CareFragrance "20.07.13";
BA_ "Description" SG_ 1019 HU_CareMassage "Care Massage On/Off";
BA_ "GenSigSendType" SG_ 1019 HU_CareMassage 4;
BA_ "UserSigValidity" SG_ 1019 HU_CareMassage 3;
BA_REL_ "GenSigTimeoutTime" BU_SG_REL_ ALBCU SG_ 1019 HU_CareMassage 0;
BA_REL_ "GenSigTimeoutTime" BU_SG_REL_ ASAU SG_ 1019 HU_CareMassage 0;
BA_REL_ "GenSigTimeoutTime" BU_SG_REL_ DSAU SG_ 1019 HU_CareMassage 0;
BA_REL_ "GenSigTimeoutTime" BU_SG_REL_ GW_DLBCU SG_ 1019 HU_CareMassage 0;
BA_ "RoutingFactor" SG_ 1019 HU_CareMassage 0;
BA_ "Version" SG_ 1019 HU_CareMassage "20.07.13";
BA_ "Description" SG_ 1019 HU_CareCurtain "Care Curtain On/Off";
BA_ "GenSigSendType" SG_ 1019 HU_CareCurtain 4;
BA_ "UserSigValidity" SG_ 1019 HU_CareCurtain 3;
BA_ "RoutingFactor" SG_ 1019 HU_CareCurtain 0;
BA_ "Version" SG_ 1019 HU_CareCurtain "20.07.13";
BA_ "Description" SG_ 1019 HU_ComfortMoodLamp "Comfort MoodLamp On/Off";
BA_ "GenSigSendType" SG_ 1019 HU_ComfortMoodLamp 4;
BA_ "UserSigValidity" SG_ 1019 HU_ComfortMoodLamp 3;
BA_ "RoutingFactor" SG_ 1019 HU_ComfortMoodLamp 0;
BA_ "Version" SG_ 1019 HU_ComfortMoodLamp "20.07.13";
BA_ "Description" SG_ 1019 HU_ComfortFragrance "Comfort Fragrance On/Off";
BA_ "GenSigSendType" SG_ 1019 HU_ComfortFragrance 4;
BA_ "UserSigValidity" SG_ 1019 HU_ComfortFragrance 3;
BA_ "RoutingFactor" SG_ 1019 HU_ComfortFragrance 0;
BA_ "Version" SG_ 1019 HU_ComfortFragrance "20.07.13";
BA_ "Description" SG_ 1019 HU_ComfortMassage "Comfort Massage On/Off";
BA_ "GenSigSendType" SG_ 1019 HU_ComfortMassage 4;
BA_ "UserSigValidity" SG_ 1019 HU_ComfortMassage 3;
BA_REL_ "GenSigTimeoutTime" BU_SG_REL_ ALBCU SG_ 1019 HU_ComfortMassage 0;
BA_REL_ "GenSigTimeoutTime" BU_SG_REL_ ASAU SG_ 1019 HU_ComfortMassage 0;
BA_REL_ "GenSigTimeoutTime" BU_SG_REL_ DSAU SG_ 1019 HU_ComfortMassage 0;
BA_REL_ "GenSigTimeoutTime" BU_SG_REL_ GW_DLBCU SG_ 1019 HU_ComfortMassage 0;
BA_ "RoutingFactor" SG_ 1019 HU_ComfortMassage 0;
BA_ "Version" SG_ 1019 HU_ComfortMassage "20.07.13";
BA_ "Description" SG_ 1019 HU_ComfortCurtain "Comfort Curtain On/Off";
BA_ "GenSigSendType" SG_ 1019 HU_ComfortCurtain 4;
BA_ "UserSigValidity" SG_ 1019 HU_ComfortCurtain 3;
BA_ "RoutingFactor" SG_ 1019 HU_ComfortCurtain 0;
BA_ "Version" SG_ 1019 HU_ComfortCurtain "20.07.13";
BA_ "Description" SG_ 1019 HU_MoodTherapyMode "Moodtherapy Mode Change Signal";
BA_ "GenSigSendType" SG_ 1019 HU_MoodTherapyMode 4;
BA_ "UserSigValidity" SG_ 1019 HU_MoodTherapyMode 3;
BA_REL_ "GenSigTimeoutTime" BU_SG_REL_ ALBCU SG_ 1019 HU_MoodTherapyMode 0;
BA_REL_ "GenSigTimeoutTime" BU_SG_REL_ ASAU SG_ 1019 HU_MoodTherapyMode 0;
BA_REL_ "GenSigTimeoutTime" BU_SG_REL_ DSAU SG_ 1019 HU_MoodTherapyMode 0;
BA_REL_ "GenSigTimeoutTime" BU_SG_REL_ GW_DLBCU SG_ 1019 HU_MoodTherapyMode 0;
BA_ "RoutingFactor" SG_ 1019 HU_MoodTherapyMode 0;
BA_ "Version" SG_ 1019 HU_MoodTherapyMode "20.07.13";
BA_ "Description" SG_ 1019 HU_MoodTherapyRlSeat "Moodtherapy RearLeft Seat On/Off";
BA_ "GenSigSendType" SG_ 1019 HU_MoodTherapyRlSeat 4;
BA_ "UserSigValidity" SG_ 1019 HU_MoodTherapyRlSeat 3;
BA_ "RoutingFactor" SG_ 1019 HU_MoodTherapyRlSeat 0;
BA_ "Version" SG_ 1019 HU_MoodTherapyRlSeat "20.07.13";
BA_ "Description" SG_ 1019 HU_MoodTherapyRrSeat "Moodtherapy Rear Right Seat On/Off";
BA_ "GenSigSendType" SG_ 1019 HU_MoodTherapyRrSeat 4;
BA_ "UserSigValidity" SG_ 1019 HU_MoodTherapyRrSeat 3;
BA_ "RoutingFactor" SG_ 1019 HU_MoodTherapyRrSeat 0;
BA_ "Version" SG_ 1019 HU_MoodTherapyRrSeat "20.07.13";
BA_ "Description" SG_ 1019 HU_VitalityMoodLamp "Vitality MoodLamp On/Off";
BA_ "GenSigSendType" SG_ 1019 HU_VitalityMoodLamp 4;
BA_ "UserSigValidity" SG_ 1019 HU_VitalityMoodLamp 3;
BA_ "RoutingFactor" SG_ 1019 HU_VitalityMoodLamp 0;
BA_ "Version" SG_ 1019 HU_VitalityMoodLamp "20.07.13";
BA_ "GenMsgCycleTime" BO_ 1993 0;
BA_ "GenMsgCycleTimeFast" BO_ 1993 0;
BA_ "GenMsgNrOfRepetition" BO_ 1993 0;
BA_ "DiagResponse" BO_ 1993 1;
BA_ "GenMsgILSupport" BO_ 1993 0;
BA_ "TpMessage" BO_ 1993 1;
BA_ "TpTxIndex" BO_ 1993 154;
BA_ "Description" SG_ 1993 PSB_GST_Byte0 "TP Index : 154";
BA_ "UsrSigPurpose" SG_ 1993 PSB_GST_Byte0 4;
BA_ "UserSigValidity" SG_ 1993 PSB_GST_Byte0 0;
BA_REL_ "GenSigTimeoutTime" BU_SG_REL_ CGW_CCU SG_ 1993 PSB_GST_Byte0 0;
BA_ "NetworkRequest" SG_ 1993 PSB_GST_Byte0 0;
BA_ "NetworkRequestHoldingTime" SG_ 1993 PSB_GST_Byte0 5000;
BA_ "Version" SG_ 1993 PSB_GST_Byte0 "22.07.01";
BA_ "Description" SG_ 1993 PSB_GST_Byte2 "TP Index : 154";
BA_ "UsrSigPurpose" SG_ 1993 PSB_GST_Byte2 4;
BA_ "UserSigValidity" SG_ 1993 PSB_GST_Byte2 0;
BA_REL_ "GenSigTimeoutTime" BU_SG_REL_ CGW_CCU SG_ 1993 PSB_GST_Byte2 0;
BA_ "NetworkRequest" SG_ 1993 PSB_GST_Byte2 0;
BA_ "NetworkRequestHoldingTime" SG_ 1993 PSB_GST_Byte2 5000;
BA_ "Version" SG_ 1993 PSB_GST_Byte2 "22.07.01";
BA_ "Description" SG_ 1993 PSB_GST_Byte3 "TP Index : 154";
BA_ "UsrSigPurpose" SG_ 1993 PSB_GST_Byte3 4;
BA_ "UserSigValidity" SG_ 1993 PSB_GST_Byte3 0;
BA_REL_ "GenSigTimeoutTime" BU_SG_REL_ CGW_CCU SG_ 1993 PSB_GST_Byte3 0;
BA_ "NetworkRequest" SG_ 1993 PSB_GST_Byte3 0;
BA_ "NetworkRequestHoldingTime" SG_ 1993 PSB_GST_Byte3 5000;
BA_ "Version" SG_ 1993 PSB_GST_Byte3 "22.07.01";
BA_ "Description" SG_ 1993 PSB_GST_Byte4 "TP Index : 154";
BA_ "UsrSigPurpose" SG_ 1993 PSB_GST_Byte4 4;
BA_ "UserSigValidity" SG_ 1993 PSB_GST_Byte4 0;
BA_REL_ "GenSigTimeoutTime" BU_SG_REL_ CGW_CCU SG_ 1993 PSB_GST_Byte4 0;
BA_ "NetworkRequest" SG_ 1993 PSB_GST_Byte4 0;
BA_ "NetworkRequestHoldingTime" SG_ 1993 PSB_GST_Byte4 5000;
BA_ "Version" SG_ 1993 PSB_GST_Byte4 "22.07.01";
BA_ "Description" SG_ 1993 PSB_GST_Byte5 "TP Index : 154";
BA_ "UsrSigPurpose" SG_ 1993 PSB_GST_Byte5 4;
BA_ "UserSigValidity" SG_ 1993 PSB_GST_Byte5 0;
BA_REL_ "GenSigTimeoutTime" BU_SG_REL_ CGW_CCU SG_ 1993 PSB_GST_Byte5 0;
BA_ "NetworkRequest" SG_ 1993 PSB_GST_Byte5 0;
BA_ "NetworkRequestHoldingTime" SG_ 1993 PSB_GST_Byte5 5000;
BA_ "Version" SG_ 1993 PSB_GST_Byte5 "22.07.01";
BA_ "Description" SG_ 1993 PSB_GST_Byte6 "TP Index : 154";
BA_ "UsrSigPurpose" SG_ 1993 PSB_GST_Byte6 4;
BA_ "UserSigValidity" SG_ 1993 PSB_GST_Byte6 0;
BA_REL_ "GenSigTimeoutTime" BU_SG_REL_ CGW_CCU SG_ 1993 PSB_GST_Byte6 0;
BA_ "NetworkRequest" SG_ 1993 PSB_GST_Byte6 0;
BA_ "NetworkRequestHoldingTime" SG_ 1993 PSB_GST_Byte6 5000;
BA_ "Version" SG_ 1993 PSB_GST_Byte6 "22.07.01";
BA_ "Description" SG_ 1993 PSB_GST_Byte7 "TP Index : 154";
BA_ "UsrSigPurpose" SG_ 1993 PSB_GST_Byte7 4;
BA_ "UserSigValidity" SG_ 1993 PSB_GST_Byte7 0;
BA_REL_ "GenSigTimeoutTime" BU_SG_REL_ CGW_CCU SG_ 1993 PSB_GST_Byte7 0;
BA_ "NetworkRequest" SG_ 1993 PSB_GST_Byte7 0;
BA_ "NetworkRequestHoldingTime" SG_ 1993 PSB_GST_Byte7 5000;
BA_ "Version" SG_ 1993 PSB_GST_Byte7 "22.07.01";
BA_ "Description" SG_ 1993 PSB_GST_Byte1 "TP Index : 154";
BA_ "UsrSigPurpose" SG_ 1993 PSB_GST_Byte1 4;
BA_ "UserSigValidity" SG_ 1993 PSB_GST_Byte1 0;
BA_REL_ "GenSigTimeoutTime" BU_SG_REL_ CGW_CCU SG_ 1993 PSB_GST_Byte1 0;
BA_ "NetworkRequest" SG_ 1993 PSB_GST_Byte1 0;
BA_ "NetworkRequestHoldingTime" SG_ 1993 PSB_GST_Byte1 5000;
BA_ "Version" SG_ 1993 PSB_GST_Byte1 "22.07.01";
BA_ "GenMsgSendType" BO_ 902 0;
BA_ "GenSigSendType" SG_ 902 PSM_DrvStEsyAcsUSMSta 4;
BA_ "UserSigValidity" SG_ 902 PSM_DrvStEsyAcsUSMSta 0;
BA_REL_ "GenSigTimeoutTime" BU_SG_REL_ CGW_CCU SG_ 902 PSM_DrvStEsyAcsUSMSta 1500;
BA_REL_ "GenSigTimeoutTime" BU_SG_REL_ DSAU SG_ 902 PSM_DrvStEsyAcsUSMSta 1500;
BA_REL_ "GenSigTimeoutTime" BU_SG_REL_ GW_DLBCU SG_ 902 PSM_DrvStEsyAcsUSMSta 1500;
BA_ "NetworkRequest" SG_ 902 PSM_DrvStEsyAcsUSMSta 0;
BA_ "NetworkRequestHoldingTime" SG_ 902 PSM_DrvStEsyAcsUSMSta 5000;
BA_ "Version" SG_ 902 PSM_DrvStEsyAcsUSMSta "17.11.00";
BA_ "Description" SG_ 902 PSM_SeatPosPlyBck_Sta "The signal indicates the state of Driver's seat position playing back.";
BA_ "GenSigSendType" SG_ 902 PSM_SeatPosPlyBck_Sta 4;
BA_ "UserSigValidity" SG_ 902 PSM_SeatPosPlyBck_Sta 0;
BA_REL_ "GenSigTimeoutTime" BU_SG_REL_ GW_RLPSU SG_ 902 PSM_SeatPosPlyBck_Sta 1500;
BA_ "Version" SG_ 902 PSM_SeatPosPlyBck_Sta "20.03.01";
BA_ "Description" SG_ 902 PSM_SeatPos_Sta "The signal indicates the state of  Driver seat Meomry State";
BA_ "GenSigSendType" SG_ 902 PSM_SeatPos_Sta 4;
BA_ "UserSigValidity" SG_ 902 PSM_SeatPos_Sta 0;
BA_REL_ "GenSigTimeoutTime" BU_SG_REL_ GW_RLPSU SG_ 902 PSM_SeatPos_Sta 1500;
BA_ "Version" SG_ 902 PSM_SeatPos_Sta "20.03.01";
BA_ "Description" SG_ 902 PSM_SeatPosSldLmt_Sta "PSM Slide end Position and limit Initialize State information";
BA_ "GenSigSendType" SG_ 902 PSM_SeatPosSldLmt_Sta 4;
BA_ "UserSigValidity" SG_ 902 PSM_SeatPosSldLmt_Sta 0;
BA_REL_ "GenSigTimeoutTime" BU_SG_REL_ CGW_CCU SG_ 902 PSM_SeatPosSldLmt_Sta 1500;
BA_ "NetworkRequest" SG_ 902 PSM_SeatPosSldLmt_Sta 0;
BA_ "NetworkRequestHoldingTime" SG_ 902 PSM_SeatPosSldLmt_Sta 5000;
BA_ "Version" SG_ 902 PSM_SeatPosSldLmt_Sta "20.03.01";
BA_ "Description" SG_ 902 PSM_SeatPosRclnLmt_Sta "PSM Recline end Position and limit Initialize State information";
BA_ "GenSigSendType" SG_ 902 PSM_SeatPosRclnLmt_Sta 4;
BA_ "UserSigValidity" SG_ 902 PSM_SeatPosRclnLmt_Sta 0;
BA_REL_ "GenSigTimeoutTime" BU_SG_REL_ CGW_CCU SG_ 902 PSM_SeatPosRclnLmt_Sta 1500;
BA_ "NetworkRequest" SG_ 902 PSM_SeatPosRclnLmt_Sta 0;
BA_ "NetworkRequestHoldingTime" SG_ 902 PSM_SeatPosRclnLmt_Sta 5000;
BA_ "Version" SG_ 902 PSM_SeatPosRclnLmt_Sta "20.03.01";
BA_ "Description" SG_ 902 SmrtIMS_StatureRspVal "User height information response value for Health Care IMS";
BA_ "GenSigSendType" SG_ 902 SmrtIMS_StatureRspVal 4;
BA_ "UserSigValidity" SG_ 902 SmrtIMS_StatureRspVal 0;
BA_REL_ "GenSigTimeoutTime" BU_SG_REL_ CGW_CCU SG_ 902 SmrtIMS_StatureRspVal 1500;
BA_ "NetworkRequest" SG_ 902 SmrtIMS_StatureRspVal 0;
BA_ "NetworkRequestHoldingTime" SG_ 902 SmrtIMS_StatureRspVal 5000;
BA_ "Version" SG_ 902 SmrtIMS_StatureRspVal "17.11.00";
BA_ "Description" SG_ 902 SmrtIMS_SeatedHghtRspVal "User sit height information response value for Health Care IMS";
BA_ "GenSigSendType" SG_ 902 SmrtIMS_SeatedHghtRspVal 4;
BA_ "UserSigValidity" SG_ 902 SmrtIMS_SeatedHghtRspVal 0;
BA_REL_ "GenSigTimeoutTime" BU_SG_REL_ CGW_CCU SG_ 902 SmrtIMS_SeatedHghtRspVal 1500;
BA_ "NetworkRequest" SG_ 902 SmrtIMS_SeatedHghtRspVal 0;
BA_ "NetworkRequestHoldingTime" SG_ 902 SmrtIMS_SeatedHghtRspVal 5000;
BA_ "Version" SG_ 902 SmrtIMS_SeatedHghtRspVal "17.11.00";
BA_ "Description" SG_ 902 Drv_2ndAutoFldEnable "1st Drv Position Condition Check Signal for 2nd Seat Auto fold function";
BA_ "GenSigSendType" SG_ 902 Drv_2ndAutoFldEnable 4;
BA_ "UserSigValidity" SG_ 902 Drv_2ndAutoFldEnable 0;
BA_REL_ "GenSigTimeoutTime" BU_SG_REL_ GW_RLPSU SG_ 902 Drv_2ndAutoFldEnable 1500;
BA_REL_ "GenSigTimeoutTime" BU_SG_REL_ GW_RRPSU SG_ 902 Drv_2ndAutoFldEnable 1500;
BA_ "NetworkRequest" SG_ 902 Drv_2ndAutoFldEnable 0;
BA_ "NetworkRequestHoldingTime" SG_ 902 Drv_2ndAutoFldEnable 5000;
BA_ "Version" SG_ 902 Drv_2ndAutoFldEnable "22.11.13";
BA_ "Description" SG_ 902 SmrtIMS_WghtRspVal "User weight information repsponse value for Health Care IMS";
BA_ "GenSigSendType" SG_ 902 SmrtIMS_WghtRspVal 4;
BA_ "UserSigValidity" SG_ 902 SmrtIMS_WghtRspVal 0;
BA_REL_ "GenSigTimeoutTime" BU_SG_REL_ CGW_CCU SG_ 902 SmrtIMS_WghtRspVal 1500;
BA_ "NetworkRequest" SG_ 902 SmrtIMS_WghtRspVal 0;
BA_ "NetworkRequestHoldingTime" SG_ 902 SmrtIMS_WghtRspVal 5000;
BA_ "Version" SG_ 902 SmrtIMS_WghtRspVal "17.11.00";
BA_ "Description" SG_ 902 SmartIMS_DisReq "For displaying the state of seat moving";
BA_ "GenSigSendType" SG_ 902 SmartIMS_DisReq 4;
BA_ "UserSigValidity" SG_ 902 SmartIMS_DisReq 0;
BA_REL_ "GenSigTimeoutTime" BU_SG_REL_ CGW_CCU SG_ 902 SmartIMS_DisReq 1500;
BA_ "NetworkRequest" SG_ 902 SmartIMS_DisReq 0;
BA_ "NetworkRequestHoldingTime" SG_ 902 SmartIMS_DisReq 5000;
BA_ "Version" SG_ 902 SmartIMS_DisReq "17.11.00";
BA_ "Description" SG_ 902 SmrtIMS_ExitSta "-(Old)C_SmartIMSExit";
BA_ "GenSigSendType" SG_ 902 SmrtIMS_ExitSta 4;
BA_ "UserSigValidity" SG_ 902 SmrtIMS_ExitSta 0;
BA_REL_ "GenSigTimeoutTime" BU_SG_REL_ CGW_CCU SG_ 902 SmrtIMS_ExitSta 1500;
BA_ "NetworkRequest" SG_ 902 SmrtIMS_ExitSta 0;
BA_ "NetworkRequestHoldingTime" SG_ 902 SmrtIMS_ExitSta 5000;
BA_ "Version" SG_ 902 SmrtIMS_ExitSta "17.11.00";
BA_ "Description" SG_ 902 PSM_DrvStRlxTiltUpDis "This signal is used to display the seat movement to AVN";
BA_ "GenSigSendType" SG_ 902 PSM_DrvStRlxTiltUpDis 4;
BA_ "UserSigValidity" SG_ 902 PSM_DrvStRlxTiltUpDis 1;
BA_REL_ "GenSigTimeoutTime" BU_SG_REL_ CGW_CCU SG_ 902 PSM_DrvStRlxTiltUpDis 1500;
BA_ "NetworkRequest" SG_ 902 PSM_DrvStRlxTiltUpDis 0;
BA_ "NetworkRequestHoldingTime" SG_ 902 PSM_DrvStRlxTiltUpDis 5000;
BA_ "Version" SG_ 902 PSM_DrvStRlxTiltUpDis "20.01.02";
BA_ "Description" SG_ 902 PSM_DrvStRlxTiltDnDis "This signal is used to display the seat movement to AVN";
BA_ "GenSigSendType" SG_ 902 PSM_DrvStRlxTiltDnDis 4;
BA_ "UserSigValidity" SG_ 902 PSM_DrvStRlxTiltDnDis 1;
BA_REL_ "GenSigTimeoutTime" BU_SG_REL_ CGW_CCU SG_ 902 PSM_DrvStRlxTiltDnDis 1500;
BA_ "NetworkRequest" SG_ 902 PSM_DrvStRlxTiltDnDis 0;
BA_ "NetworkRequestHoldingTime" SG_ 902 PSM_DrvStRlxTiltDnDis 5000;
BA_ "Version" SG_ 902 PSM_DrvStRlxTiltDnDis "20.01.02";
BA_ "Description" SG_ 902 PSM_DrvStLegUpDis "This signal is used to display the seat movement to AVN";
BA_ "GenSigSendType" SG_ 902 PSM_DrvStLegUpDis 4;
BA_ "UserSigValidity" SG_ 902 PSM_DrvStLegUpDis 1;
BA_REL_ "GenSigTimeoutTime" BU_SG_REL_ CGW_CCU SG_ 902 PSM_DrvStLegUpDis 1500;
BA_ "NetworkRequest" SG_ 902 PSM_DrvStLegUpDis 0;
BA_ "NetworkRequestHoldingTime" SG_ 902 PSM_DrvStLegUpDis 5000;
BA_ "Version" SG_ 902 PSM_DrvStLegUpDis "20.01.02";
BA_ "Description" SG_ 902 PSM_DrvStLegDnDis "This signal is used to display the seat movement to AVN";
BA_ "GenSigSendType" SG_ 902 PSM_DrvStLegDnDis 4;
BA_ "UserSigValidity" SG_ 902 PSM_DrvStLegDnDis 1;
BA_REL_ "GenSigTimeoutTime" BU_SG_REL_ CGW_CCU SG_ 902 PSM_DrvStLegDnDis 1500;
BA_ "NetworkRequest" SG_ 902 PSM_DrvStLegDnDis 0;
BA_ "NetworkRequestHoldingTime" SG_ 902 PSM_DrvStLegDnDis 5000;
BA_ "Version" SG_ 902 PSM_DrvStLegDnDis "20.01.02";
BA_ "Description" SG_ 902 Drv_2ndStAutoRlxEnable "¿îÀü¼® ½ÃÆ® À§Ä¡¿¡ µû¸¥ ÈÄ¼® ¿ÀÅä ¸±·º¼Ç ÀÛµ¿ °¡´É ¿©ºÎ";
BA_ "GenSigSendType" SG_ 902 Drv_2ndStAutoRlxEnable 4;
BA_ "TimeoutValue" SG_ 902 Drv_2ndStAutoRlxEnable "0x0";
BA_ "UserSigValidity" SG_ 902 Drv_2ndStAutoRlxEnable 0;
BA_REL_ "GenSigTimeoutTime" BU_SG_REL_ GW_RLPSU SG_ 902 Drv_2ndStAutoRlxEnable 1500;
BA_REL_ "GenSigTimeoutTime" BU_SG_REL_ GW_RRPSU SG_ 902 Drv_2ndStAutoRlxEnable 1500;
BA_ "NetworkRequest" SG_ 902 Drv_2ndStAutoRlxEnable 0;
BA_ "NetworkRequestHoldingTime" SG_ 902 Drv_2ndStAutoRlxEnable 5000;
BA_ "Version" SG_ 902 Drv_2ndStAutoRlxEnable "21.06.10";
BA_ "Description" SG_ 902 Drv_AutoRlxSta "¿îÀü¼® ¿ÀÅä ¸±·º¼Ç µ¿ÀÛ Á¤º¸";
BA_ "GenSigSendType" SG_ 902 Drv_AutoRlxSta 4;
BA_ "TimeoutValue" SG_ 902 Drv_AutoRlxSta "0x0";
BA_ "UserSigValidity" SG_ 902 Drv_AutoRlxSta 0;
BA_REL_ "GenSigTimeoutTime" BU_SG_REL_ CGW_CCU SG_ 902 Drv_AutoRlxSta 1500;
BA_REL_ "GenSigTimeoutTime" BU_SG_REL_ GW_RLPSU SG_ 902 Drv_AutoRlxSta 1500;
BA_REL_ "GenSigTimeoutTime" BU_SG_REL_ GW_RRPSU SG_ 902 Drv_AutoRlxSta 1500;
BA_ "NetworkRequest" SG_ 902 Drv_AutoRlxSta 0;
BA_ "NetworkRequestHoldingTime" SG_ 902 Drv_AutoRlxSta 5000;
BA_ "Version" SG_ 902 Drv_AutoRlxSta "21.06.10";
BA_ "Description" SG_ 902 Drv_AutoReturnSta "Driver Seat Auto Return Status Information";
BA_ "GenSigSendType" SG_ 902 Drv_AutoReturnSta 4;
BA_ "TimeoutValue" SG_ 902 Drv_AutoReturnSta "0x0";
BA_ "UserSigValidity" SG_ 902 Drv_AutoReturnSta 0;
BA_REL_ "GenSigTimeoutTime" BU_SG_REL_ CGW_CCU SG_ 902 Drv_AutoReturnSta 1500;
BA_ "NetworkRequest" SG_ 902 Drv_AutoReturnSta 0;
BA_ "NetworkRequestHoldingTime" SG_ 902 Drv_AutoReturnSta 5000;
BA_ "Version" SG_ 902 Drv_AutoReturnSta "21.11.04";
BA_ "Description" SG_ 902 PSM_IMSOptTyp "-(Old)C_IMSOption";
BA_ "GenSigSendType" SG_ 902 PSM_IMSOptTyp 4;
BA_ "UserSigValidity" SG_ 902 PSM_IMSOptTyp 0;
BA_REL_ "GenSigTimeoutTime" BU_SG_REL_ CGW_CCU SG_ 902 PSM_IMSOptTyp 1500;
BA_ "NetworkRequest" SG_ 902 PSM_IMSOptTyp 0;
BA_ "NetworkRequestHoldingTime" SG_ 902 PSM_IMSOptTyp 5000;
BA_ "Version" SG_ 902 PSM_IMSOptTyp "17.11.00";
BA_ "GenMsgSendType" BO_ 903 0;
BA_ "Description" SG_ 903 PSM_DrvStSldFwdDis "This signal is used to display the seat movement to AVN";
BA_ "GenSigSendType" SG_ 903 PSM_DrvStSldFwdDis 4;
BA_ "UserSigValidity" SG_ 903 PSM_DrvStSldFwdDis 1;
BA_REL_ "GenSigTimeoutTime" BU_SG_REL_ CGW_CCU SG_ 903 PSM_DrvStSldFwdDis 1500;
BA_ "NetworkRequest" SG_ 903 PSM_DrvStSldFwdDis 0;
BA_ "NetworkRequestHoldingTime" SG_ 903 PSM_DrvStSldFwdDis 5000;
BA_ "Version" SG_ 903 PSM_DrvStSldFwdDis "17.11.00";
BA_ "Description" SG_ 903 PSM_DrvStTiltDnDis "This signal is used to display the seat movement to AVN";
BA_ "GenSigSendType" SG_ 903 PSM_DrvStTiltDnDis 4;
BA_ "UserSigValidity" SG_ 903 PSM_DrvStTiltDnDis 1;
BA_REL_ "GenSigTimeoutTime" BU_SG_REL_ CGW_CCU SG_ 903 PSM_DrvStTiltDnDis 1500;
BA_ "NetworkRequest" SG_ 903 PSM_DrvStTiltDnDis 0;
BA_ "NetworkRequestHoldingTime" SG_ 903 PSM_DrvStTiltDnDis 5000;
BA_ "Version" SG_ 903 PSM_DrvStTiltDnDis "17.11.00";
BA_ "Description" SG_ 903 PSM_DrvStHghtUpDis "This signal is used to display the seat movement to AVN";
BA_ "GenSigSendType" SG_ 903 PSM_DrvStHghtUpDis 4;
BA_ "UserSigValidity" SG_ 903 PSM_DrvStHghtUpDis 1;
BA_REL_ "GenSigTimeoutTime" BU_SG_REL_ CGW_CCU SG_ 903 PSM_DrvStHghtUpDis 1500;
BA_ "NetworkRequest" SG_ 903 PSM_DrvStHghtUpDis 0;
BA_ "NetworkRequestHoldingTime" SG_ 903 PSM_DrvStHghtUpDis 5000;
BA_ "Version" SG_ 903 PSM_DrvStHghtUpDis "17.11.00";
BA_ "Description" SG_ 903 PSM_DrvStHghtDnDis "This signal is used to display the seat movement to AVN";
BA_ "GenSigSendType" SG_ 903 PSM_DrvStHghtDnDis 4;
BA_ "UserSigValidity" SG_ 903 PSM_DrvStHghtDnDis 1;
BA_REL_ "GenSigTimeoutTime" BU_SG_REL_ CGW_CCU SG_ 903 PSM_DrvStHghtDnDis 1500;
BA_ "NetworkRequest" SG_ 903 PSM_DrvStHghtDnDis 0;
BA_ "NetworkRequestHoldingTime" SG_ 903 PSM_DrvStHghtDnDis 5000;
BA_ "Version" SG_ 903 PSM_DrvStHghtDnDis "17.11.00";
BA_ "Description" SG_ 903 PSM_DrvStCushExtBckwdDis "This signal is used to display the seat movement to AVN";
BA_ "GenSigSendType" SG_ 903 PSM_DrvStCushExtBckwdDis 4;
BA_ "UserSigValidity" SG_ 903 PSM_DrvStCushExtBckwdDis 1;
BA_REL_ "GenSigTimeoutTime" BU_SG_REL_ CGW_CCU SG_ 903 PSM_DrvStCushExtBckwdDis 1500;
BA_ "NetworkRequest" SG_ 903 PSM_DrvStCushExtBckwdDis 0;
BA_ "NetworkRequestHoldingTime" SG_ 903 PSM_DrvStCushExtBckwdDis 5000;
BA_ "Version" SG_ 903 PSM_DrvStCushExtBckwdDis "17.11.00";
BA_ "Description" SG_ 903 PSM_DrvStCushExtFwdDis "This signal is used to display the seat movement to AVN";
BA_ "GenSigSendType" SG_ 903 PSM_DrvStCushExtFwdDis 4;
BA_ "UserSigValidity" SG_ 903 PSM_DrvStCushExtFwdDis 1;
BA_REL_ "GenSigTimeoutTime" BU_SG_REL_ CGW_CCU SG_ 903 PSM_DrvStCushExtFwdDis 1500;
BA_ "NetworkRequest" SG_ 903 PSM_DrvStCushExtFwdDis 0;
BA_ "NetworkRequestHoldingTime" SG_ 903 PSM_DrvStCushExtFwdDis 5000;
BA_ "Version" SG_ 903 PSM_DrvStCushExtFwdDis "17.11.00";
BA_ "Description" SG_ 903 PSM_DrvStSldBckwdDis "This signal is used to display the seat movement to AVN";
BA_ "GenSigSendType" SG_ 903 PSM_DrvStSldBckwdDis 4;
BA_ "UserSigValidity" SG_ 903 PSM_DrvStSldBckwdDis 1;
BA_REL_ "GenSigTimeoutTime" BU_SG_REL_ CGW_CCU SG_ 903 PSM_DrvStSldBckwdDis 1500;
BA_ "NetworkRequest" SG_ 903 PSM_DrvStSldBckwdDis 0;
BA_ "NetworkRequestHoldingTime" SG_ 903 PSM_DrvStSldBckwdDis 5000;
BA_ "Version" SG_ 903 PSM_DrvStSldBckwdDis "17.11.00";
BA_ "Description" SG_ 903 PSM_DrvStHdRstUpDis "This signal is used to display the seat movement to AVN";
BA_ "GenSigSendType" SG_ 903 PSM_DrvStHdRstUpDis 4;
BA_ "UserSigValidity" SG_ 903 PSM_DrvStHdRstUpDis 1;
BA_REL_ "GenSigTimeoutTime" BU_SG_REL_ CGW_CCU SG_ 903 PSM_DrvStHdRstUpDis 1500;
BA_ "NetworkRequest" SG_ 903 PSM_DrvStHdRstUpDis 0;
BA_ "NetworkRequestHoldingTime" SG_ 903 PSM_DrvStHdRstUpDis 5000;
BA_ "Version" SG_ 903 PSM_DrvStHdRstUpDis "20.07.05";
BA_ "Description" SG_ 903 PSM_DrvStHdRstDnDis "This signal is used to display the seat movement to AVN";
BA_ "GenSigSendType" SG_ 903 PSM_DrvStHdRstDnDis 4;
BA_ "UserSigValidity" SG_ 903 PSM_DrvStHdRstDnDis 1;
BA_REL_ "GenSigTimeoutTime" BU_SG_REL_ CGW_CCU SG_ 903 PSM_DrvStHdRstDnDis 1500;
BA_ "NetworkRequest" SG_ 903 PSM_DrvStHdRstDnDis 0;
BA_ "NetworkRequestHoldingTime" SG_ 903 PSM_DrvStHdRstDnDis 5000;
BA_ "Version" SG_ 903 PSM_DrvStHdRstDnDis "17.11.00";
BA_ "Description" SG_ 903 PSM_DrvStHdRstFwdDis "This signal is used to display the seat movement to AVN";
BA_ "GenSigSendType" SG_ 903 PSM_DrvStHdRstFwdDis 4;
BA_ "UserSigValidity" SG_ 903 PSM_DrvStHdRstFwdDis 1;
BA_REL_ "GenSigTimeoutTime" BU_SG_REL_ CGW_CCU SG_ 903 PSM_DrvStHdRstFwdDis 1500;
BA_ "NetworkRequest" SG_ 903 PSM_DrvStHdRstFwdDis 0;
BA_ "NetworkRequestHoldingTime" SG_ 903 PSM_DrvStHdRstFwdDis 5000;
BA_ "Version" SG_ 903 PSM_DrvStHdRstFwdDis "17.11.00";
BA_ "Description" SG_ 903 PSM_DrvStHdRstBckwdDis "This signal is used to display the seat movement to AVN";
BA_ "GenSigSendType" SG_ 903 PSM_DrvStHdRstBckwdDis 4;
BA_ "UserSigValidity" SG_ 903 PSM_DrvStHdRstBckwdDis 1;
BA_REL_ "GenSigTimeoutTime" BU_SG_REL_ CGW_CCU SG_ 903 PSM_DrvStHdRstBckwdDis 1500;
BA_ "NetworkRequest" SG_ 903 PSM_DrvStHdRstBckwdDis 0;
BA_ "NetworkRequestHoldingTime" SG_ 903 PSM_DrvStHdRstBckwdDis 5000;
BA_ "Version" SG_ 903 PSM_DrvStHdRstBckwdDis "17.11.00";
BA_ "Description" SG_ 903 PSM_DrvStLmbrDefDis "This signal is used to display the seat movement to AVN";
BA_ "GenSigSendType" SG_ 903 PSM_DrvStLmbrDefDis 4;
BA_ "UserSigValidity" SG_ 903 PSM_DrvStLmbrDefDis 1;
BA_REL_ "GenSigTimeoutTime" BU_SG_REL_ CGW_CCU SG_ 903 PSM_DrvStLmbrDefDis 1500;
BA_ "NetworkRequest" SG_ 903 PSM_DrvStLmbrDefDis 0;
BA_ "NetworkRequestHoldingTime" SG_ 903 PSM_DrvStLmbrDefDis 5000;
BA_ "Version" SG_ 903 PSM_DrvStLmbrDefDis "17.11.00";
BA_ "Description" SG_ 903 PSM_DrvStLmbrLoDis "This signal is used to display the seat movement to AVN";
BA_ "GenSigSendType" SG_ 903 PSM_DrvStLmbrLoDis 4;
BA_ "UserSigValidity" SG_ 903 PSM_DrvStLmbrLoDis 1;
BA_REL_ "GenSigTimeoutTime" BU_SG_REL_ CGW_CCU SG_ 903 PSM_DrvStLmbrLoDis 1500;
BA_ "NetworkRequest" SG_ 903 PSM_DrvStLmbrLoDis 0;
BA_ "NetworkRequestHoldingTime" SG_ 903 PSM_DrvStLmbrLoDis 5000;
BA_ "Version" SG_ 903 PSM_DrvStLmbrLoDis "17.11.00";
BA_ "Description" SG_ 903 PSM_DrvStLmbrMdlDis "This signal is used to display the seat movement to AVN";
BA_ "GenSigSendType" SG_ 903 PSM_DrvStLmbrMdlDis 4;
BA_ "UserSigValidity" SG_ 903 PSM_DrvStLmbrMdlDis 1;
BA_REL_ "GenSigTimeoutTime" BU_SG_REL_ CGW_CCU SG_ 903 PSM_DrvStLmbrMdlDis 1500;
BA_ "NetworkRequest" SG_ 903 PSM_DrvStLmbrMdlDis 0;
BA_ "NetworkRequestHoldingTime" SG_ 903 PSM_DrvStLmbrMdlDis 5000;
BA_ "Version" SG_ 903 PSM_DrvStLmbrMdlDis "17.11.00";
BA_ "Description" SG_ 903 PSM_DrvStLmbrUpDis "This signal is used to display the seat movement to AVN";
BA_ "GenSigSendType" SG_ 903 PSM_DrvStLmbrUpDis 4;
BA_ "UserSigValidity" SG_ 903 PSM_DrvStLmbrUpDis 1;
BA_REL_ "GenSigTimeoutTime" BU_SG_REL_ CGW_CCU SG_ 903 PSM_DrvStLmbrUpDis 1500;
BA_ "NetworkRequest" SG_ 903 PSM_DrvStLmbrUpDis 0;
BA_ "NetworkRequestHoldingTime" SG_ 903 PSM_DrvStLmbrUpDis 5000;
BA_ "Version" SG_ 903 PSM_DrvStLmbrUpDis "17.11.00";
BA_ "Description" SG_ 903 PSM_DrvStReclneFwdDis "This signal is used to display the seat movement to AVN";
BA_ "GenSigSendType" SG_ 903 PSM_DrvStReclneFwdDis 4;
BA_ "UserSigValidity" SG_ 903 PSM_DrvStReclneFwdDis 1;
BA_REL_ "GenSigTimeoutTime" BU_SG_REL_ CGW_CCU SG_ 903 PSM_DrvStReclneFwdDis 1500;
BA_ "NetworkRequest" SG_ 903 PSM_DrvStReclneFwdDis 0;
BA_ "NetworkRequestHoldingTime" SG_ 903 PSM_DrvStReclneFwdDis 5000;
BA_ "Version" SG_ 903 PSM_DrvStReclneFwdDis "17.11.00";
BA_ "Description" SG_ 903 PSM_DrvStBlstrDefDis "This signal is used to display the seat movement to AVN";
BA_ "GenSigSendType" SG_ 903 PSM_DrvStBlstrDefDis 4;
BA_ "UserSigValidity" SG_ 903 PSM_DrvStBlstrDefDis 1;
BA_REL_ "GenSigTimeoutTime" BU_SG_REL_ CGW_CCU SG_ 903 PSM_DrvStBlstrDefDis 1500;
BA_ "NetworkRequest" SG_ 903 PSM_DrvStBlstrDefDis 0;
BA_ "NetworkRequestHoldingTime" SG_ 903 PSM_DrvStBlstrDefDis 5000;
BA_ "Version" SG_ 903 PSM_DrvStBlstrDefDis "17.11.00";
BA_ "Description" SG_ 903 PSM_DrvStBlstrInfDis "This signal is used to display the seat movement to AVN";
BA_ "GenSigSendType" SG_ 903 PSM_DrvStBlstrInfDis 4;
BA_ "UserSigValidity" SG_ 903 PSM_DrvStBlstrInfDis 1;
BA_REL_ "GenSigTimeoutTime" BU_SG_REL_ CGW_CCU SG_ 903 PSM_DrvStBlstrInfDis 1500;
BA_ "NetworkRequest" SG_ 903 PSM_DrvStBlstrInfDis 0;
BA_ "NetworkRequestHoldingTime" SG_ 903 PSM_DrvStBlstrInfDis 5000;
BA_ "Version" SG_ 903 PSM_DrvStBlstrInfDis "17.11.00";
BA_ "Description" SG_ 903 PSM_DrvStReclneBckwdDis "This signal is used to display the seat movement to AVN";
BA_ "GenSigSendType" SG_ 903 PSM_DrvStReclneBckwdDis 4;
BA_ "UserSigValidity" SG_ 903 PSM_DrvStReclneBckwdDis 1;
BA_REL_ "GenSigTimeoutTime" BU_SG_REL_ CGW_CCU SG_ 903 PSM_DrvStReclneBckwdDis 1500;
BA_ "NetworkRequest" SG_ 903 PSM_DrvStReclneBckwdDis 0;
BA_ "NetworkRequestHoldingTime" SG_ 903 PSM_DrvStReclneBckwdDis 5000;
BA_ "Version" SG_ 903 PSM_DrvStReclneBckwdDis "17.11.00";
BA_ "Description" SG_ 903 PSM_DrvStTiltUpDis "This signal is used to display the seat movement to AVN";
BA_ "GenSigSendType" SG_ 903 PSM_DrvStTiltUpDis 4;
BA_ "UserSigValidity" SG_ 903 PSM_DrvStTiltUpDis 1;
BA_REL_ "GenSigTimeoutTime" BU_SG_REL_ CGW_CCU SG_ 903 PSM_DrvStTiltUpDis 1500;
BA_ "NetworkRequest" SG_ 903 PSM_DrvStTiltUpDis 0;
BA_ "NetworkRequestHoldingTime" SG_ 903 PSM_DrvStTiltUpDis 5000;
BA_ "Version" SG_ 903 PSM_DrvStTiltUpDis "17.11.00";
BA_ "GenMsgSendType" BO_ 904 0;
BA_ "Description" SG_ 904 PSM_DrvReclinePosition "DRIVER SEAT RECLINE POSITION (UNIT: ¢ª)";
BA_ "GenSigSendType" SG_ 904 PSM_DrvReclinePosition 4;
BA_ "UserSigValidity" SG_ 904 PSM_DrvReclinePosition 0;
BA_REL_ "GenSigTimeoutTime" BU_SG_REL_ CGW_CCU SG_ 904 PSM_DrvReclinePosition 1500;
BA_REL_ "GenSigTimeoutTime" BU_SG_REL_ GW_RLPSU SG_ 904 PSM_DrvReclinePosition 1500;
BA_REL_ "GenSigTimeoutTime" BU_SG_REL_ GW_RRPSU SG_ 904 PSM_DrvReclinePosition 1500;
BA_ "NetworkRequest" SG_ 904 PSM_DrvReclinePosition 0;
BA_ "NetworkRequestHoldingTime" SG_ 904 PSM_DrvReclinePosition 5000;
BA_ "Version" SG_ 904 PSM_DrvReclinePosition "19.08.06";
BA_ "Description" SG_ 904 PSM_EsyAcsGetOffSta "-(Old)C_EasyAccessGetOff";
BA_ "GenSigSendType" SG_ 904 PSM_EsyAcsGetOffSta 4;
BA_ "UserSigValidity" SG_ 904 PSM_EsyAcsGetOffSta 0;
BA_REL_ "GenSigTimeoutTime" BU_SG_REL_ DSAU SG_ 904 PSM_EsyAcsGetOffSta 1500;
BA_REL_ "GenSigTimeoutTime" BU_SG_REL_ GW_DLBCU SG_ 904 PSM_EsyAcsGetOffSta 1500;
BA_REL_ "GenSigTimeoutTime" BU_SG_REL_ GW_RLPSU SG_ 904 PSM_EsyAcsGetOffSta 1500;
BA_REL_ "GenSigTimeoutTime" BU_SG_REL_ GW_RRPSU SG_ 904 PSM_EsyAcsGetOffSta 1500;
BA_ "NetworkRequest" SG_ 904 PSM_EsyAcsGetOffSta 0;
BA_ "NetworkRequestHoldingTime" SG_ 904 PSM_EsyAcsGetOffSta 5000;
BA_ "Version" SG_ 904 PSM_EsyAcsGetOffSta "17.11.00";
BA_ "Description" SG_ 904 PSM_EsyAcsStpSta "-(Old)C_EasyAccessStop";
BA_ "GenSigSendType" SG_ 904 PSM_EsyAcsStpSta 4;
BA_ "UserSigValidity" SG_ 904 PSM_EsyAcsStpSta 0;
BA_REL_ "GenSigTimeoutTime" BU_SG_REL_ DSAU SG_ 904 PSM_EsyAcsStpSta 1500;
BA_REL_ "GenSigTimeoutTime" BU_SG_REL_ GW_DLBCU SG_ 904 PSM_EsyAcsStpSta 1500;
BA_REL_ "GenSigTimeoutTime" BU_SG_REL_ GW_RLPSU SG_ 904 PSM_EsyAcsStpSta 1500;
BA_REL_ "GenSigTimeoutTime" BU_SG_REL_ GW_RRPSU SG_ 904 PSM_EsyAcsStpSta 1500;
BA_ "NetworkRequest" SG_ 904 PSM_EsyAcsStpSta 0;
BA_ "NetworkRequestHoldingTime" SG_ 904 PSM_EsyAcsStpSta 5000;
BA_ "Version" SG_ 904 PSM_EsyAcsStpSta "17.11.00";
BA_ "Description" SG_ 904 PSM_SWVerMajor1 "Indicate the PSM software version as follows:

- The software version is displayed in three digits.

- The Major and Minor digits are separated by '.'

- Signal values are transmitted to ASCII codes.



¡Ø Example

PSM_SWVerMajor1 : 0x41 (HEX) -> ASCII CODE : 'A' 

PSM_SWVerMinor1 : 0x30 (HEX) -> ASCII CODE : '0'

PSM_SWVerMinor2 : 0x33 (HEX) -> ASCII CODE : '3'

=> PSM S/W Ver is displayed 'A.03'";
BA_ "GenSigSendType" SG_ 904 PSM_SWVerMajor1 4;
BA_ "UserSigValidity" SG_ 904 PSM_SWVerMajor1 0;
BA_REL_ "GenSigTimeoutTime" BU_SG_REL_ CGW_CCU SG_ 904 PSM_SWVerMajor1 1500;
BA_ "Version" SG_ 904 PSM_SWVerMajor1 "20.12.04";
BA_ "Description" SG_ 904 PSM_SWVerMinor1 "Indicate the PSM software version as follows:

- The software version is displayed in three digits.

- The Major and Minor digits are separated by '.'

- Signal values are transmitted to ASCII codes.



¡Ø Example

PSM_SWVerMajor1 : 0x41 (HEX) -> ASCII CODE : 'A' 

PSM_SWVerMinor1 : 0x30 (HEX) -> ASCII CODE : '0'

PSM_SWVerMinor2 : 0x33 (HEX) -> ASCII CODE : '3'

=> PSM S/W Ver is displayed 'A.03'";
BA_ "GenSigSendType" SG_ 904 PSM_SWVerMinor1 4;
BA_ "UserSigValidity" SG_ 904 PSM_SWVerMinor1 0;
BA_REL_ "GenSigTimeoutTime" BU_SG_REL_ CGW_CCU SG_ 904 PSM_SWVerMinor1 1500;
BA_ "Version" SG_ 904 PSM_SWVerMinor1 "18.10.06";
BA_ "Description" SG_ 904 PSM_SWVerMinor2 "Indicate the PSM software version as follows:

- The software version is displayed in three digits.

- The Major and Minor digits are separated by '.'

- Signal values are transmitted to ASCII codes.



¡Ø Example

PSM_SWVerMajor1 : 0x41 (HEX) -> ASCII CODE : 'A' 

PSM_SWVerMinor1 : 0x30 (HEX) -> ASCII CODE : '0'

PSM_SWVerMinor2 : 0x33 (HEX) -> ASCII CODE : '3'

=> PSM S/W Ver is displayed 'A.03'";
BA_ "GenSigSendType" SG_ 904 PSM_SWVerMinor2 4;
BA_ "UserSigValidity" SG_ 904 PSM_SWVerMinor2 0;
BA_REL_ "GenSigTimeoutTime" BU_SG_REL_ CGW_CCU SG_ 904 PSM_SWVerMinor2 1500;
BA_ "Version" SG_ 904 PSM_SWVerMinor2 "18.10.06";
BA_ "Description" SG_ 904 PSM_HDPSpprtSWVer "This signal indicates Requirement Spec Version about PSM by HDP";
BA_ "GenSigSendType" SG_ 904 PSM_HDPSpprtSWVer 4;
BA_ "UserSigValidity" SG_ 904 PSM_HDPSpprtSWVer 0;
BA_REL_ "GenSigTimeoutTime" BU_SG_REL_ CGW_CCU SG_ 904 PSM_HDPSpprtSWVer 1500;
BA_ "Version" SG_ 904 PSM_HDPSpprtSWVer "22.01.00";
BA_ "Description" SG_ 904 PSM_DrvHeightPosition "DRIVER SEAT HEIGHT POSITION (UNIT: mm)";
BA_ "GenSigSendType" SG_ 904 PSM_DrvHeightPosition 4;
BA_ "UserSigValidity" SG_ 904 PSM_DrvHeightPosition 0;
BA_REL_ "GenSigTimeoutTime" BU_SG_REL_ CGW_CCU SG_ 904 PSM_DrvHeightPosition 1500;
BA_REL_ "GenSigTimeoutTime" BU_SG_REL_ GW_RLPSU SG_ 904 PSM_DrvHeightPosition 1500;
BA_REL_ "GenSigTimeoutTime" BU_SG_REL_ GW_RRPSU SG_ 904 PSM_DrvHeightPosition 1500;
BA_ "NetworkRequest" SG_ 904 PSM_DrvHeightPosition 0;
BA_ "NetworkRequestHoldingTime" SG_ 904 PSM_DrvHeightPosition 5000;
BA_ "Version" SG_ 904 PSM_DrvHeightPosition "20.03.03";
BA_ "Description" SG_ 904 PSM_DrvSlidePosition "DRIVER SEAT SLIDE POSITION (UNIT: mm, 1 Value ´ç 2mm)";
BA_ "GenSigSendType" SG_ 904 PSM_DrvSlidePosition 4;
BA_ "UserSigValidity" SG_ 904 PSM_DrvSlidePosition 0;
BA_REL_ "GenSigTimeoutTime" BU_SG_REL_ CGW_CCU SG_ 904 PSM_DrvSlidePosition 1500;
BA_REL_ "GenSigTimeoutTime" BU_SG_REL_ GW_RLPSU SG_ 904 PSM_DrvSlidePosition 1500;
BA_REL_ "GenSigTimeoutTime" BU_SG_REL_ GW_RRPSU SG_ 904 PSM_DrvSlidePosition 1500;
BA_ "NetworkRequest" SG_ 904 PSM_DrvSlidePosition 0;
BA_ "NetworkRequestHoldingTime" SG_ 904 PSM_DrvSlidePosition 5000;
BA_ "Version" SG_ 904 PSM_DrvSlidePosition "22.06.05";
BA_ "Description" SG_ 904 PSM_EsyAcsGetOnSta "-(Old)C_EasyAccessGetOn";
BA_ "GenSigSendType" SG_ 904 PSM_EsyAcsGetOnSta 4;
BA_ "UserSigValidity" SG_ 904 PSM_EsyAcsGetOnSta 0;
BA_REL_ "GenSigTimeoutTime" BU_SG_REL_ DSAU SG_ 904 PSM_EsyAcsGetOnSta 1500;
BA_REL_ "GenSigTimeoutTime" BU_SG_REL_ GW_DLBCU SG_ 904 PSM_EsyAcsGetOnSta 1500;
BA_REL_ "GenSigTimeoutTime" BU_SG_REL_ GW_RLPSU SG_ 904 PSM_EsyAcsGetOnSta 1500;
BA_REL_ "GenSigTimeoutTime" BU_SG_REL_ GW_RRPSU SG_ 904 PSM_EsyAcsGetOnSta 1500;
BA_ "NetworkRequest" SG_ 904 PSM_EsyAcsGetOnSta 0;
BA_ "NetworkRequestHoldingTime" SG_ 904 PSM_EsyAcsGetOnSta 5000;
BA_ "Version" SG_ 904 PSM_EsyAcsGetOnSta "17.11.00";
BA_ "GenMsgSendType" BO_ 1004 0;
BA_ "Description" SG_ 1004 CF_RCS_SwTyp "Road Control Switch Type";
BA_ "GenSigSendType" SG_ 1004 CF_RCS_SwTyp 4;
BA_ "UserSigValidity" SG_ 1004 CF_RCS_SwTyp 0;
BA_REL_ "GenSigTimeoutTime" BU_SG_REL_ CGW_CCU SG_ 1004 CF_RCS_SwTyp 1500;
BA_ "RoutingFactor" SG_ 1004 CF_RCS_SwTyp 0;
BA_ "Version" SG_ 1004 CF_RCS_SwTyp "18.10.02";
BA_ "Description" SG_ 1004 CF_RCS_OffRoad "RCS OffRoad mode status";
BA_ "GenSigSendType" SG_ 1004 CF_RCS_OffRoad 4;
BA_ "UserSigValidity" SG_ 1004 CF_RCS_OffRoad 3;
BA_REL_ "GenSigTimeoutTime" BU_SG_REL_ CGW_CCU SG_ 1004 CF_RCS_OffRoad 1500;
BA_ "RoutingFactor" SG_ 1004 CF_RCS_OffRoad 0;
BA_ "Version" SG_ 1004 CF_RCS_OffRoad "20.01.01";
BA_ "Description" SG_ 1004 CF_RCS_BtnSta "RCS Button Status";
BA_ "GenSigSendType" SG_ 1004 CF_RCS_BtnSta 4;
BA_ "UserSigValidity" SG_ 1004 CF_RCS_BtnSta 3;
BA_REL_ "GenSigTimeoutTime" BU_SG_REL_ CGW_CCU SG_ 1004 CF_RCS_BtnSta 1500;
BA_ "RoutingFactor" SG_ 1004 CF_RCS_BtnSta 0;
BA_ "Version" SG_ 1004 CF_RCS_BtnSta "18.10.02";
BA_ "Description" SG_ 1004 CF_RCS_RotateEnd "signal to inform end of rotate";
BA_ "GenSigSendType" SG_ 1004 CF_RCS_RotateEnd 4;
BA_ "UserSigValidity" SG_ 1004 CF_RCS_RotateEnd 3;
BA_REL_ "GenSigTimeoutTime" BU_SG_REL_ CGW_CCU SG_ 1004 CF_RCS_RotateEnd 1500;
BA_ "RoutingFactor" SG_ 1004 CF_RCS_RotateEnd 0;
BA_ "Version" SG_ 1004 CF_RCS_RotateEnd "18.10.02";
BA_ "Description" SG_ 1004 CF_RCS_4wdLocking "4wd locking on/off signal";
BA_ "GenSigSendType" SG_ 1004 CF_RCS_4wdLocking 4;
BA_ "UserSigValidity" SG_ 1004 CF_RCS_4wdLocking 3;
BA_REL_ "GenSigTimeoutTime" BU_SG_REL_ CGW_CCU SG_ 1004 CF_RCS_4wdLocking 1500;
BA_ "RoutingFactor" SG_ 1004 CF_RCS_4wdLocking 0;
BA_ "Version" SG_ 1004 CF_RCS_4wdLocking "18.10.02";
BA_ "GenSigSendType" SG_ 1004 RCS_Direction_SW 4;
BA_ "UserSigValidity" SG_ 1004 RCS_Direction_SW 3;
BA_REL_ "GenSigTimeoutTime" BU_SG_REL_ CGW_CCU SG_ 1004 RCS_Direction_SW 1500;
BA_ "NetworkRequest" SG_ 1004 RCS_Direction_SW 0;
BA_ "NetworkRequestHoldingTime" SG_ 1004 RCS_Direction_SW 5000;
BA_ "RoutingFactor" SG_ 1004 RCS_Direction_SW 0;
BA_ "Version" SG_ 1004 RCS_Direction_SW "22.06.05";
BA_ "Description" SG_ 1004 CF_RCS_DrvMod "RCS drive mode select status";
BA_ "GenSigSendType" SG_ 1004 CF_RCS_DrvMod 4;
BA_ "UserSigValidity" SG_ 1004 CF_RCS_DrvMod 3;
BA_REL_ "GenSigTimeoutTime" BU_SG_REL_ CGW_CCU SG_ 1004 CF_RCS_DrvMod 1500;
BA_ "RoutingFactor" SG_ 1004 CF_RCS_DrvMod 0;
BA_ "Version" SG_ 1004 CF_RCS_DrvMod "18.10.02";
BA_ "GenSigSendType" SG_ 1004 RCS_Mode_SW 4;
BA_ "UserSigValidity" SG_ 1004 RCS_Mode_SW 3;
BA_REL_ "GenSigTimeoutTime" BU_SG_REL_ CGW_CCU SG_ 1004 RCS_Mode_SW 1500;
BA_ "NetworkRequest" SG_ 1004 RCS_Mode_SW 0;
BA_ "NetworkRequestHoldingTime" SG_ 1004 RCS_Mode_SW 5000;
BA_ "RoutingFactor" SG_ 1004 RCS_Mode_SW 0;
BA_ "Version" SG_ 1004 RCS_Mode_SW "22.06.05";
BA_ "Description" SG_ 1004 CF_RCS_TowMode "Tow Mode On/off Switch signal";
BA_ "GenSigSendType" SG_ 1004 CF_RCS_TowMode 4;
BA_ "UserSigValidity" SG_ 1004 CF_RCS_TowMode 3;
BA_REL_ "GenSigTimeoutTime" BU_SG_REL_ CGW_CCU SG_ 1004 CF_RCS_TowMode 200;
BA_ "RoutingFactor" SG_ 1004 CF_RCS_TowMode 0;
BA_ "Version" SG_ 1004 CF_RCS_TowMode "22.04.01";
BA_ "GenMsgSendType" BO_ 1003 0;
BA_ "Description" SG_ 1003 PSM_BzrOnRLReq "PSM buzzer on command";
BA_ "GenSigSendType" SG_ 1003 PSM_BzrOnRLReq 4;
BA_ "UserSigValidity" SG_ 1003 PSM_BzrOnRLReq 0;
BA_REL_ "GenSigTimeoutTime" BU_SG_REL_ ATS SG_ 1003 PSM_BzrOnRLReq 1500;
BA_REL_ "GenSigTimeoutTime" BU_SG_REL_ GW_DPSU SG_ 1003 PSM_BzrOnRLReq 1500;
BA_ "NetworkRequest" SG_ 1003 PSM_BzrOnRLReq 0;
BA_ "NetworkRequestHoldingTime" SG_ 1003 PSM_BzrOnRLReq 5000;
BA_ "Version" SG_ 1003 PSM_BzrOnRLReq "17.11.00";
BA_ "Description" SG_ 1003 RLPSM_RearModeState "Rear Seat State for One Touch Mode";
BA_ "GenSigSendType" SG_ 1003 RLPSM_RearModeState 4;
BA_ "UserSigValidity" SG_ 1003 RLPSM_RearModeState 0;
BA_REL_ "GenSigTimeoutTime" BU_SG_REL_ ATS SG_ 1003 RLPSM_RearModeState 1500;
BA_REL_ "GenSigTimeoutTime" BU_SG_REL_ CGW_CCU SG_ 1003 RLPSM_RearModeState 1500;
BA_REL_ "GenSigTimeoutTime" BU_SG_REL_ GW_APSU SG_ 1003 RLPSM_RearModeState 1500;
BA_REL_ "GenSigTimeoutTime" BU_SG_REL_ GW_DPSU SG_ 1003 RLPSM_RearModeState 1500;
BA_REL_ "GenSigTimeoutTime" BU_SG_REL_ OHCL SG_ 1003 RLPSM_RearModeState 1500;
BA_ "NetworkRequest" SG_ 1003 RLPSM_RearModeState 0;
BA_ "NetworkRequestHoldingTime" SG_ 1003 RLPSM_RearModeState 5000;
BA_ "Version" SG_ 1003 RLPSM_RearModeState "23.12.00";
BA_ "Description" SG_ 1003 RLPSM_RrLfSldStrtSta "This signal indicates the start/finish of rear right slide motor.";
BA_ "GenSigSendType" SG_ 1003 RLPSM_RrLfSldStrtSta 4;
BA_ "UserSigValidity" SG_ 1003 RLPSM_RrLfSldStrtSta 0;
BA_REL_ "GenSigTimeoutTime" BU_SG_REL_ ARS SG_ 1003 RLPSM_RrLfSldStrtSta 1500;
BA_REL_ "GenSigTimeoutTime" BU_SG_REL_ GW_APSU SG_ 1003 RLPSM_RrLfSldStrtSta 1500;
BA_REL_ "GenSigTimeoutTime" BU_SG_REL_ GW_DPSU SG_ 1003 RLPSM_RrLfSldStrtSta 1500;
BA_REL_ "GenSigTimeoutTime" BU_SG_REL_ GW_RRPSU SG_ 1003 RLPSM_RrLfSldStrtSta 1500;
BA_ "NetworkRequest" SG_ 1003 RLPSM_RrLfSldStrtSta 0;
BA_ "NetworkRequestHoldingTime" SG_ 1003 RLPSM_RrLfSldStrtSta 5000;
BA_ "Version" SG_ 1003 RLPSM_RrLfSldStrtSta "19.08.08";
BA_ "Description" SG_ 1003 RLPSM_OptTyp "The signal indicates the option type of Rear Left's Power Seat Module.";
BA_ "GenSigSendType" SG_ 1003 RLPSM_OptTyp 4;
BA_ "UserSigValidity" SG_ 1003 RLPSM_OptTyp 0;
BA_REL_ "GenSigTimeoutTime" BU_SG_REL_ CGW_CCU SG_ 1003 RLPSM_OptTyp 1500;
BA_ "Version" SG_ 1003 RLPSM_OptTyp "19.10.02";
BA_ "GenSigSendType" SG_ 1003 RLPSM_RLStEsyAcsUSMSta 4;
BA_ "UserSigValidity" SG_ 1003 RLPSM_RLStEsyAcsUSMSta 0;
BA_REL_ "GenSigTimeoutTime" BU_SG_REL_ ATS SG_ 1003 RLPSM_RLStEsyAcsUSMSta 1500;
BA_REL_ "GenSigTimeoutTime" BU_SG_REL_ CGW_CCU SG_ 1003 RLPSM_RLStEsyAcsUSMSta 1500;
BA_REL_ "GenSigTimeoutTime" BU_SG_REL_ GW_DLBCU SG_ 1003 RLPSM_RLStEsyAcsUSMSta 1500;
BA_ "Version" SG_ 1003 RLPSM_RLStEsyAcsUSMSta "19.10.07";
BA_ "Description" SG_ 1003 RLPSM_AllSeatPosPlyBck_Sta "The signal indicates the state of All seat position playing back.";
BA_ "GenSigSendType" SG_ 1003 RLPSM_AllSeatPosPlyBck_Sta 4;
BA_ "UserSigValidity" SG_ 1003 RLPSM_AllSeatPosPlyBck_Sta 0;
BA_REL_ "GenSigTimeoutTime" BU_SG_REL_ CGW_CCU SG_ 1003 RLPSM_AllSeatPosPlyBck_Sta 1500;
BA_ "Version" SG_ 1003 RLPSM_AllSeatPosPlyBck_Sta "20.03.01";
BA_ "Description" SG_ 1003 RLPSM_RLSlidePosition "Rear Left Seat Slide Position (UNIT: mm, 1 Value ´ç 2mm)";
BA_ "GenSigSendType" SG_ 1003 RLPSM_RLSlidePosition 4;
BA_ "UserSigValidity" SG_ 1003 RLPSM_RLSlidePosition 0;
BA_REL_ "GenSigTimeoutTime" BU_SG_REL_ GW_APSU SG_ 1003 RLPSM_RLSlidePosition 1500;
BA_REL_ "GenSigTimeoutTime" BU_SG_REL_ GW_DPSU SG_ 1003 RLPSM_RLSlidePosition 1500;
BA_REL_ "GenSigTimeoutTime" BU_SG_REL_ GW_RLPSU SG_ 1003 RLPSM_RLSlidePosition 1500;
BA_REL_ "GenSigTimeoutTime" BU_SG_REL_ GW_RRPSU SG_ 1003 RLPSM_RLSlidePosition 1500;
BA_ "NetworkRequest" SG_ 1003 RLPSM_RLSlidePosition 0;
BA_ "NetworkRequestHoldingTime" SG_ 1003 RLPSM_RLSlidePosition 5000;
BA_ "Version" SG_ 1003 RLPSM_RLSlidePosition "22.06.05";
BA_ "Description" SG_ 1003 RLPSM_SeatPos_Sta "The signal indicates the state of   Seat Meomry State";
BA_ "GenSigSendType" SG_ 1003 RLPSM_SeatPos_Sta 4;
BA_ "UserSigValidity" SG_ 1003 RLPSM_SeatPos_Sta 0;
BA_REL_ "GenSigTimeoutTime" BU_SG_REL_ CGW_CCU SG_ 1003 RLPSM_SeatPos_Sta 1500;
BA_REL_ "GenSigTimeoutTime" BU_SG_REL_ GW_RRPSU SG_ 1003 RLPSM_SeatPos_Sta 1500;
BA_ "Version" SG_ 1003 RLPSM_SeatPos_Sta "20.03.01";
BA_ "Description" SG_ 1003 RLPSM_SeatPosSldLmt_Sta "RLPSM(Rear Left) Slide end Position and limit Initialize State information";
BA_ "GenSigSendType" SG_ 1003 RLPSM_SeatPosSldLmt_Sta 4;
BA_ "UserSigValidity" SG_ 1003 RLPSM_SeatPosSldLmt_Sta 0;
BA_REL_ "GenSigTimeoutTime" BU_SG_REL_ CGW_CCU SG_ 1003 RLPSM_SeatPosSldLmt_Sta 1500;
BA_ "NetworkRequest" SG_ 1003 RLPSM_SeatPosSldLmt_Sta 0;
BA_ "NetworkRequestHoldingTime" SG_ 1003 RLPSM_SeatPosSldLmt_Sta 5000;
BA_ "Version" SG_ 1003 RLPSM_SeatPosSldLmt_Sta "20.03.01";
BA_ "Description" SG_ 1003 RLPSM_Enable_Sta "The signal indicates Seat Operating condition";
BA_ "GenSigSendType" SG_ 1003 RLPSM_Enable_Sta 4;
BA_ "UserSigValidity" SG_ 1003 RLPSM_Enable_Sta 0;
BA_REL_ "GenSigTimeoutTime" BU_SG_REL_ CGW_CCU SG_ 1003 RLPSM_Enable_Sta 1500;
BA_ "Version" SG_ 1003 RLPSM_Enable_Sta "20.03.01";
BA_ "Description" SG_ 1003 RLPSM_Mem1_Sta "RLPSM Memory State";
BA_ "GenSigSendType" SG_ 1003 RLPSM_Mem1_Sta 4;
BA_ "UserSigValidity" SG_ 1003 RLPSM_Mem1_Sta 0;
BA_REL_ "GenSigTimeoutTime" BU_SG_REL_ CGW_CCU SG_ 1003 RLPSM_Mem1_Sta 1500;
BA_ "NetworkRequest" SG_ 1003 RLPSM_Mem1_Sta 0;
BA_ "NetworkRequestHoldingTime" SG_ 1003 RLPSM_Mem1_Sta 5000;
BA_ "Version" SG_ 1003 RLPSM_Mem1_Sta "20.03.01";
BA_ "Description" SG_ 1003 RLPSM_Mem2_Sta "RLPSM Memory2 State information";
BA_ "GenSigSendType" SG_ 1003 RLPSM_Mem2_Sta 4;
BA_ "UserSigValidity" SG_ 1003 RLPSM_Mem2_Sta 0;
BA_REL_ "GenSigTimeoutTime" BU_SG_REL_ CGW_CCU SG_ 1003 RLPSM_Mem2_Sta 1500;
BA_ "NetworkRequest" SG_ 1003 RLPSM_Mem2_Sta 0;
BA_ "NetworkRequestHoldingTime" SG_ 1003 RLPSM_Mem2_Sta 5000;
BA_ "Version" SG_ 1003 RLPSM_Mem2_Sta "20.03.01";
BA_ "Description" SG_ 1003 RLPSM_Mem3_Sta "RLPSM Memory3 State information";
BA_ "GenSigSendType" SG_ 1003 RLPSM_Mem3_Sta 4;
BA_ "UserSigValidity" SG_ 1003 RLPSM_Mem3_Sta 0;
BA_REL_ "GenSigTimeoutTime" BU_SG_REL_ CGW_CCU SG_ 1003 RLPSM_Mem3_Sta 1500;
BA_ "NetworkRequest" SG_ 1003 RLPSM_Mem3_Sta 0;
BA_ "NetworkRequestHoldingTime" SG_ 1003 RLPSM_Mem3_Sta 5000;
BA_ "Version" SG_ 1003 RLPSM_Mem3_Sta "20.03.01";
BA_ "GenSigSendType" SG_ 1003 RLPSM_LimSetSta 4;
BA_ "UserSigValidity" SG_ 1003 RLPSM_LimSetSta 0;
BA_ "NetworkRequest" SG_ 1003 RLPSM_LimSetSta 0;
BA_ "NetworkRequestHoldingTime" SG_ 1003 RLPSM_LimSetSta 5000;
BA_ "Version" SG_ 1003 RLPSM_LimSetSta "21.04.01";
BA_ "GenMsgSendType" BO_ 1005 0;
BA_ "Description" SG_ 1005 RLPSU_FldDis "2nd Left side seat moving state  : Folding";
BA_ "GenSigSendType" SG_ 1005 RLPSU_FldDis 4;
BA_ "UserSigValidity" SG_ 1005 RLPSU_FldDis 0;
BA_REL_ "GenSigTimeoutTime" BU_SG_REL_ CGW_CCU SG_ 1005 RLPSU_FldDis 1500;
BA_ "Version" SG_ 1005 RLPSU_FldDis "18.09.01";
BA_ "Description" SG_ 1005 RLPSU_TiltDownDis "2nd Left side seat moving state  : Tilt down";
BA_ "GenSigSendType" SG_ 1005 RLPSU_TiltDownDis 4;
BA_ "UserSigValidity" SG_ 1005 RLPSU_TiltDownDis 0;
BA_REL_ "GenSigTimeoutTime" BU_SG_REL_ CGW_CCU SG_ 1005 RLPSU_TiltDownDis 1500;
BA_ "Version" SG_ 1005 RLPSU_TiltDownDis "18.09.01";
BA_ "Description" SG_ 1005 RLPSU_RclFwdDis "2nd Left side seat moving state  : Recline Forward";
BA_ "GenSigSendType" SG_ 1005 RLPSU_RclFwdDis 4;
BA_ "UserSigValidity" SG_ 1005 RLPSU_RclFwdDis 0;
BA_REL_ "GenSigTimeoutTime" BU_SG_REL_ CGW_CCU SG_ 1005 RLPSU_RclFwdDis 1500;
BA_ "Version" SG_ 1005 RLPSU_RclFwdDis "18.09.01";
BA_ "Description" SG_ 1005 RLPSU_RclBwdDis "2nd Left side seat moving state  : Recline Backward";
BA_ "GenSigSendType" SG_ 1005 RLPSU_RclBwdDis 4;
BA_ "UserSigValidity" SG_ 1005 RLPSU_RclBwdDis 0;
BA_REL_ "GenSigTimeoutTime" BU_SG_REL_ CGW_CCU SG_ 1005 RLPSU_RclBwdDis 1500;
BA_ "Version" SG_ 1005 RLPSU_RclBwdDis "18.09.01";
BA_ "Description" SG_ 1005 RLPSU_RlxModeDis "2nd Left side seat moving state  : Relax mode";
BA_ "GenSigSendType" SG_ 1005 RLPSU_RlxModeDis 4;
BA_ "UserSigValidity" SG_ 1005 RLPSU_RlxModeDis 0;
BA_ "Version" SG_ 1005 RLPSU_RlxModeDis "18.09.02";
BA_ "Description" SG_ 1005 RLPSU_Folding_SW "Interlocking signal between DPSM and RLPSU";
BA_ "GenSigSendType" SG_ 1005 RLPSU_Folding_SW 4;
BA_ "UserSigValidity" SG_ 1005 RLPSU_Folding_SW 0;
BA_ "Version" SG_ 1005 RLPSU_Folding_SW "18.09.01";
BA_ "Description" SG_ 1005 RLPSU_UnFldDis "2nd Left side seat moving state  : UnFolding";
BA_ "GenSigSendType" SG_ 1005 RLPSU_UnFldDis 4;
BA_ "UserSigValidity" SG_ 1005 RLPSU_UnFldDis 0;
BA_ "Version" SG_ 1005 RLPSU_UnFldDis "18.09.01";
BA_ "Description" SG_ 1005 RLPSU_Unfolding_SW "Interlocking signal between DPSM and RLPSU";
BA_ "GenSigSendType" SG_ 1005 RLPSU_Unfolding_SW 4;
BA_ "UserSigValidity" SG_ 1005 RLPSU_Unfolding_SW 0;
BA_ "Version" SG_ 1005 RLPSU_Unfolding_SW "18.09.01";
BA_ "Description" SG_ 1005 RLPSU_WalkIn_SW "Interlocking signal between DPSM and RLPSU";
BA_ "GenSigSendType" SG_ 1005 RLPSU_WalkIn_SW 4;
BA_ "UserSigValidity" SG_ 1005 RLPSU_WalkIn_SW 0;
BA_ "Version" SG_ 1005 RLPSU_WalkIn_SW "18.09.01";
BA_ "Description" SG_ 1005 RLPSU_UnwalkIn_SW "Interlocking signal between DPSM and RLPSU";
BA_ "GenSigSendType" SG_ 1005 RLPSU_UnwalkIn_SW 4;
BA_ "UserSigValidity" SG_ 1005 RLPSU_UnwalkIn_SW 0;
BA_ "Version" SG_ 1005 RLPSU_UnwalkIn_SW "18.09.01";
BA_ "Description" SG_ 1005 RLPSU_Folding_Postion "RLPSU Position Information";
BA_ "GenSigSendType" SG_ 1005 RLPSU_Folding_Postion 4;
BA_ "UserSigValidity" SG_ 1005 RLPSU_Folding_Postion 0;
BA_REL_ "GenSigTimeoutTime" BU_SG_REL_ CGW_CCU SG_ 1005 RLPSU_Folding_Postion 1500;
BA_REL_ "GenSigTimeoutTime" BU_SG_REL_ GW_RLPSU SG_ 1005 RLPSU_Folding_Postion 1500;
BA_ "Version" SG_ 1005 RLPSU_Folding_Postion "21.07.06";
BA_ "Description" SG_ 1005 RLPSU_Folding_State_PopUp "Rear LH seat Folding State information";
BA_ "GenSigSendType" SG_ 1005 RLPSU_Folding_State_PopUp 4;
BA_ "UserSigValidity" SG_ 1005 RLPSU_Folding_State_PopUp 0;
BA_ "Version" SG_ 1005 RLPSU_Folding_State_PopUp "21.07.06";
BA_ "Description" SG_ 1005 RLPSU_Relax_State_Popup "Rear LH seat Relax State information";
BA_ "GenSigSendType" SG_ 1005 RLPSU_Relax_State_Popup 4;
BA_ "UserSigValidity" SG_ 1005 RLPSU_Relax_State_Popup 0;
BA_ "Version" SG_ 1005 RLPSU_Relax_State_Popup "21.07.06";
BA_ "Description" SG_ 1005 RLPSU_SlideFwdDis "2nd Left side seat moving state  : Slide Forward";
BA_ "GenSigSendType" SG_ 1005 RLPSU_SlideFwdDis 4;
BA_ "UserSigValidity" SG_ 1005 RLPSU_SlideFwdDis 0;
BA_REL_ "GenSigTimeoutTime" BU_SG_REL_ CGW_CCU SG_ 1005 RLPSU_SlideFwdDis 1500;
BA_ "Version" SG_ 1005 RLPSU_SlideFwdDis "19.03.05";
BA_ "Description" SG_ 1005 RLPSU_SlideBwdDis "2nd Left side seat moving state  : Slide Backward";
BA_ "GenSigSendType" SG_ 1005 RLPSU_SlideBwdDis 4;
BA_ "UserSigValidity" SG_ 1005 RLPSU_SlideBwdDis 0;
BA_REL_ "GenSigTimeoutTime" BU_SG_REL_ CGW_CCU SG_ 1005 RLPSU_SlideBwdDis 1500;
BA_ "Version" SG_ 1005 RLPSU_SlideBwdDis "19.03.05";
BA_ "Description" SG_ 1005 RLPSU_WalkInDis "2nd Left side seat moving state : Walk In";
BA_ "GenSigSendType" SG_ 1005 RLPSU_WalkInDis 4;
BA_ "UserSigValidity" SG_ 1005 RLPSU_WalkInDis 0;
BA_ "Version" SG_ 1005 RLPSU_WalkInDis "18.09.01";
BA_ "Description" SG_ 1005 RLPSU_WalkInState "2nd Left side seat Walk-in Ready state";
BA_ "GenSigSendType" SG_ 1005 RLPSU_WalkInState 4;
BA_ "UserSigValidity" SG_ 1005 RLPSU_WalkInState 0;
BA_REL_ "GenSigTimeoutTime" BU_SG_REL_ GW_APSU SG_ 1005 RLPSU_WalkInState 1500;
BA_REL_ "GenSigTimeoutTime" BU_SG_REL_ GW_DPSU SG_ 1005 RLPSU_WalkInState 1500;
BA_ "Version" SG_ 1005 RLPSU_WalkInState "19.03.05";
BA_ "GenSigSendType" SG_ 1005 RLPSU_RLMsgEnable 4;
BA_ "UserSigValidity" SG_ 1005 RLPSU_RLMsgEnable 0;
BA_ "NetworkRequest" SG_ 1005 RLPSU_RLMsgEnable 0;
BA_ "NetworkRequestHoldingTime" SG_ 1005 RLPSU_RLMsgEnable 5000;
BA_ "Version" SG_ 1005 RLPSU_RLMsgEnable "22.07.05";
BA_ "Description" SG_ 1005 RLPSU_UnWalkInDis "2nd Left side seat moving state : Un Walk In";
BA_ "GenSigSendType" SG_ 1005 RLPSU_UnWalkInDis 4;
BA_ "UserSigValidity" SG_ 1005 RLPSU_UnWalkInDis 0;
BA_ "Version" SG_ 1005 RLPSU_UnWalkInDis "18.09.01";
BA_ "Description" SG_ 1005 RLPSU_TiltUpDis "2nd Left side seat moving state  : Tilt up";
BA_ "GenSigSendType" SG_ 1005 RLPSU_TiltUpDis 4;
BA_ "UserSigValidity" SG_ 1005 RLPSU_TiltUpDis 0;
BA_REL_ "GenSigTimeoutTime" BU_SG_REL_ CGW_CCU SG_ 1005 RLPSU_TiltUpDis 1500;
BA_ "Version" SG_ 1005 RLPSU_TiltUpDis "18.09.01";
BA_ "GenMsgSendType" BO_ 1006 0;
BA_ "Description" SG_ 1006 RRPSU_FldDis "2nd Right side seat moving state  : Folding";
BA_ "GenSigSendType" SG_ 1006 RRPSU_FldDis 4;
BA_ "UserSigValidity" SG_ 1006 RRPSU_FldDis 0;
BA_REL_ "GenSigTimeoutTime" BU_SG_REL_ CGW_CCU SG_ 1006 RRPSU_FldDis 1500;
BA_ "Version" SG_ 1006 RRPSU_FldDis "18.09.01";
BA_ "Description" SG_ 1006 RRPSU_TiltDnDis "2nd Right side seat moving state  : Tilt down";
BA_ "GenSigSendType" SG_ 1006 RRPSU_TiltDnDis 4;
BA_ "UserSigValidity" SG_ 1006 RRPSU_TiltDnDis 0;
BA_REL_ "GenSigTimeoutTime" BU_SG_REL_ CGW_CCU SG_ 1006 RRPSU_TiltDnDis 1500;
BA_ "Version" SG_ 1006 RRPSU_TiltDnDis "18.09.01";
BA_ "Description" SG_ 1006 RRPSU_RecFwdDis "2nd Right side seat moving state  : Recline Forward";
BA_ "GenSigSendType" SG_ 1006 RRPSU_RecFwdDis 4;
BA_ "UserSigValidity" SG_ 1006 RRPSU_RecFwdDis 0;
BA_REL_ "GenSigTimeoutTime" BU_SG_REL_ CGW_CCU SG_ 1006 RRPSU_RecFwdDis 1500;
BA_ "Version" SG_ 1006 RRPSU_RecFwdDis "18.09.01";
BA_ "Description" SG_ 1006 RRPSU_RecBwdDis "2nd Right side seat moving state  : Recline Backward";
BA_ "GenSigSendType" SG_ 1006 RRPSU_RecBwdDis 4;
BA_ "UserSigValidity" SG_ 1006 RRPSU_RecBwdDis 0;
BA_REL_ "GenSigTimeoutTime" BU_SG_REL_ CGW_CCU SG_ 1006 RRPSU_RecBwdDis 1500;
BA_ "Version" SG_ 1006 RRPSU_RecBwdDis "18.09.01";
BA_ "Description" SG_ 1006 RRPSU_RlxModeDis "2nd Right side seat moving state  : Relax mode";
BA_ "GenSigSendType" SG_ 1006 RRPSU_RlxModeDis 4;
BA_ "UserSigValidity" SG_ 1006 RRPSU_RlxModeDis 0;
BA_ "Version" SG_ 1006 RRPSU_RlxModeDis "18.09.02";
BA_ "Description" SG_ 1006 RRPSU_Folding_SW "Interlocking signal between DPSM and RRPSU";
BA_ "GenSigSendType" SG_ 1006 RRPSU_Folding_SW 4;
BA_ "UserSigValidity" SG_ 1006 RRPSU_Folding_SW 0;
BA_ "Version" SG_ 1006 RRPSU_Folding_SW "19.03.05";
BA_ "Description" SG_ 1006 RRPSU_UnFldDis "2nd Right side seat moving state  : UnFolding";
BA_ "GenSigSendType" SG_ 1006 RRPSU_UnFldDis 4;
BA_ "UserSigValidity" SG_ 1006 RRPSU_UnFldDis 0;
BA_ "Version" SG_ 1006 RRPSU_UnFldDis "18.09.01";
BA_ "Description" SG_ 1006 RRPSU_Unfolding_SW "Interlocking signal between DPSM and RRPSU";
BA_ "GenSigSendType" SG_ 1006 RRPSU_Unfolding_SW 4;
BA_ "UserSigValidity" SG_ 1006 RRPSU_Unfolding_SW 0;
BA_ "Version" SG_ 1006 RRPSU_Unfolding_SW "19.03.05";
BA_ "Description" SG_ 1006 RRPSU_WalkIn_SW "Interlocking signal between DPSM and RRPSU";
BA_ "GenSigSendType" SG_ 1006 RRPSU_WalkIn_SW 4;
BA_ "UserSigValidity" SG_ 1006 RRPSU_WalkIn_SW 0;
BA_ "Version" SG_ 1006 RRPSU_WalkIn_SW "19.03.05";
BA_ "Description" SG_ 1006 RRPSU_UnwalkIn_SW "Interlocking signal between DPSM and RRPSU";
BA_ "GenSigSendType" SG_ 1006 RRPSU_UnwalkIn_SW 4;
BA_ "UserSigValidity" SG_ 1006 RRPSU_UnwalkIn_SW 0;
BA_ "Version" SG_ 1006 RRPSU_UnwalkIn_SW "19.03.05";
BA_ "Description" SG_ 1006 RRPSU_Folding_Postion "RRPSU Position Information";
BA_ "GenSigSendType" SG_ 1006 RRPSU_Folding_Postion 4;
BA_ "UserSigValidity" SG_ 1006 RRPSU_Folding_Postion 0;
BA_REL_ "GenSigTimeoutTime" BU_SG_REL_ CGW_CCU SG_ 1006 RRPSU_Folding_Postion 1500;
BA_ "Version" SG_ 1006 RRPSU_Folding_Postion "21.07.06";
BA_ "Description" SG_ 1006 RRPSU_Folding_State_Popup "Rear RH seat Folding State information";
BA_ "GenSigSendType" SG_ 1006 RRPSU_Folding_State_Popup 4;
BA_ "UserSigValidity" SG_ 1006 RRPSU_Folding_State_Popup 0;
BA_ "Version" SG_ 1006 RRPSU_Folding_State_Popup "21.07.06";
BA_ "Description" SG_ 1006 RRPSU_Relax_State_Popup "Rear RH seat Relax State information";
BA_ "GenSigSendType" SG_ 1006 RRPSU_Relax_State_Popup 4;
BA_ "UserSigValidity" SG_ 1006 RRPSU_Relax_State_Popup 0;
BA_ "Version" SG_ 1006 RRPSU_Relax_State_Popup "21.07.06";
BA_ "Description" SG_ 1006 RRPSU_SlideFwdDis "2nd Right side seat moving state  : Slide Forward";
BA_ "GenSigSendType" SG_ 1006 RRPSU_SlideFwdDis 4;
BA_ "UserSigValidity" SG_ 1006 RRPSU_SlideFwdDis 0;
BA_REL_ "GenSigTimeoutTime" BU_SG_REL_ CGW_CCU SG_ 1006 RRPSU_SlideFwdDis 1500;
BA_ "Version" SG_ 1006 RRPSU_SlideFwdDis "19.03.05";
BA_ "Description" SG_ 1006 RRPSU_SlideBwdDis "2nd Right side seat moving state  : Slide Backward";
BA_ "GenSigSendType" SG_ 1006 RRPSU_SlideBwdDis 4;
BA_ "UserSigValidity" SG_ 1006 RRPSU_SlideBwdDis 0;
BA_REL_ "GenSigTimeoutTime" BU_SG_REL_ CGW_CCU SG_ 1006 RRPSU_SlideBwdDis 1500;
BA_ "Version" SG_ 1006 RRPSU_SlideBwdDis "19.03.05";
BA_ "Description" SG_ 1006 RRPSU_WalkinDis "2nd Right side seat moving state : Walk In";
BA_ "GenSigSendType" SG_ 1006 RRPSU_WalkinDis 4;
BA_ "UserSigValidity" SG_ 1006 RRPSU_WalkinDis 0;
BA_ "Version" SG_ 1006 RRPSU_WalkinDis "18.09.01";
BA_ "Description" SG_ 1006 RRPSU_WalkInState "2nd Right side seat Walk-in Ready state";
BA_ "GenSigSendType" SG_ 1006 RRPSU_WalkInState 4;
BA_ "UserSigValidity" SG_ 1006 RRPSU_WalkInState 0;
BA_REL_ "GenSigTimeoutTime" BU_SG_REL_ GW_APSU SG_ 1006 RRPSU_WalkInState 1500;
BA_REL_ "GenSigTimeoutTime" BU_SG_REL_ GW_DPSU SG_ 1006 RRPSU_WalkInState 1500;
BA_ "Version" SG_ 1006 RRPSU_WalkInState "19.03.05";
BA_ "Description" SG_ 1006 RRPSU_RRMsgEnable "This is the conditioning signal for RR Seat massage function (enabler/disable)";
BA_ "GenSigSendType" SG_ 1006 RRPSU_RRMsgEnable 4;
BA_ "UserSigValidity" SG_ 1006 RRPSU_RRMsgEnable 0;
BA_ "NetworkRequest" SG_ 1006 RRPSU_RRMsgEnable 0;
BA_ "NetworkRequestHoldingTime" SG_ 1006 RRPSU_RRMsgEnable 5000;
BA_ "Version" SG_ 1006 RRPSU_RRMsgEnable "22.07.05";
BA_ "Description" SG_ 1006 RRPSU_UnwalkinDis "2nd Right side seat moving state : Un Walk In";
BA_ "GenSigSendType" SG_ 1006 RRPSU_UnwalkinDis 4;
BA_ "UserSigValidity" SG_ 1006 RRPSU_UnwalkinDis 0;
BA_ "Version" SG_ 1006 RRPSU_UnwalkinDis "18.09.01";
BA_ "Description" SG_ 1006 RRPSU_TiltUpDis "2nd Right side seat moving state  : Tilt up";
BA_ "GenSigSendType" SG_ 1006 RRPSU_TiltUpDis 4;
BA_ "UserSigValidity" SG_ 1006 RRPSU_TiltUpDis 0;
BA_REL_ "GenSigTimeoutTime" BU_SG_REL_ CGW_CCU SG_ 1006 RRPSU_TiltUpDis 1500;
BA_ "Version" SG_ 1006 RRPSU_TiltUpDis "18.09.01";
BA_ "GenMsgSendType" BO_ 905 0;
BA_ "Description" SG_ 905 SBCM_RR_Crc1Val "The data area for CRC calculation is based on the data length (DLC) of the message DB.

The CRC shall be calculated over the entire data block (excluding the CRC bytes) including the user data, alive counter and Data ID 

 

- CRC Polynomial (0x1D) , Initial Value : 0x00, XOR value : 0xFF, Data ID Mode : Both, Data ID : Message ID + 0xF800 

- The initial value is for CRC calculation and the message should be sent with the calculated result value. 

The mathematical expression to 8 bit CRC polynomial is given here. G(x) = x8 + x4 + x3 + x2 + 1";
BA_ "GenSigSendType" SG_ 905 SBCM_RR_Crc1Val 4;
BA_ "UserSigValidity" SG_ 905 SBCM_RR_Crc1Val 0;
BA_ "Version" SG_ 905 SBCM_RR_Crc1Val "21.09.03";
BA_ "Description" SG_ 905 RR_CrashUnlockCmd "RearRightCrashUnlockCommand";
BA_ "GenSigSendType" SG_ 905 RR_CrashUnlockCmd 4;
BA_ "UserSigValidity" SG_ 905 RR_CrashUnlockCmd 0;
BA_REL_ "GenSigTimeoutTime" BU_SG_REL_ BLTN_CAM SG_ 905 RR_CrashUnlockCmd 1500;
BA_ "NetworkRequest" SG_ 905 RR_CrashUnlockCmd 0;
BA_ "Version" SG_ 905 RR_CrashUnlockCmd "21.07.07";
BA_ "Description" SG_ 905 SBCM_RR_AlvCnt1Val "For the first transmission request for a data element the counter shall be initialized with 0 and shall be incremented by 1

for every subsequent send request. When the counter reaches the maximum value(0xE), then it shall restart with 0 for the next send request";
BA_ "GenSigSendType" SG_ 905 SBCM_RR_AlvCnt1Val 4;
BA_ "UserSigValidity" SG_ 905 SBCM_RR_AlvCnt1Val 0;
BA_ "Version" SG_ 905 SBCM_RR_AlvCnt1Val "21.09.03";
BA_ "Description" SG_ 905 Warn_RrRtDrSwSta_SBCM "Warning Rear Right Door Switch Status";
BA_ "GenSigSendType" SG_ 905 Warn_RrRtDrSwSta_SBCM 4;
BA_ "UserSigValidity" SG_ 905 Warn_RrRtDrSwSta_SBCM 0;
BA_REL_ "GenSigTimeoutTime" BU_SG_REL_ ATS SG_ 905 Warn_RrRtDrSwSta_SBCM 1500;
BA_REL_ "GenSigTimeoutTime" BU_SG_REL_ BLTN_CAM SG_ 905 Warn_RrRtDrSwSta_SBCM 1500;
BA_REL_ "GenSigTimeoutTime" BU_SG_REL_ GW_APSU SG_ 905 Warn_RrRtDrSwSta_SBCM 1500;
BA_REL_ "GenSigTimeoutTime" BU_SG_REL_ GW_RLPSU SG_ 905 Warn_RrRtDrSwSta_SBCM 1500;
BA_REL_ "GenSigTimeoutTime" BU_SG_REL_ GW_RRPSU SG_ 905 Warn_RrRtDrSwSta_SBCM 1500;
BA_REL_ "GenSigTimeoutTime" BU_SG_REL_ RWPC SG_ 905 Warn_RrRtDrSwSta_SBCM 1500;
BA_REL_ "GenSigTimeoutTime" BU_SG_REL_ WPC SG_ 905 Warn_RrRtDrSwSta_SBCM 1500;
BA_REL_ "GenSigTimeoutTime" BU_SG_REL_ WPC2 SG_ 905 Warn_RrRtDrSwSta_SBCM 1500;
BA_ "NetworkRequest" SG_ 905 Warn_RrRtDrSwSta_SBCM 0;
BA_ "Version" SG_ 905 Warn_RrRtDrSwSta_SBCM "21.09.05";
BA_ "Description" SG_ 905 DoorLock_RrRtDrUnLkSta_SBCM "Rear Right Door Unlock Status";
BA_ "GenSigSendType" SG_ 905 DoorLock_RrRtDrUnLkSta_SBCM 4;
BA_ "UserSigValidity" SG_ 905 DoorLock_RrRtDrUnLkSta_SBCM 0;
BA_REL_ "GenSigTimeoutTime" BU_SG_REL_ ATS SG_ 905 DoorLock_RrRtDrUnLkSta_SBCM 1500;
BA_ "NetworkRequest" SG_ 905 DoorLock_RrRtDrUnLkSta_SBCM 0;
BA_ "Version" SG_ 905 DoorLock_RrRtDrUnLkSta_SBCM "21.07.07";
BA_ "Description" SG_ 905 RR_SEAActivated "RearRightSEAActivated";
BA_ "GenSigSendType" SG_ 905 RR_SEAActivated 4;
BA_ "UserSigValidity" SG_ 905 RR_SEAActivated 0;
BA_ "NetworkRequest" SG_ 905 RR_SEAActivated 0;
BA_ "Version" SG_ 905 RR_SEAActivated "21.07.07";
BA_ "Description" SG_ 905 RR_SEAWarn "RearRighrSEAWarning";
BA_ "GenSigSendType" SG_ 905 RR_SEAWarn 4;
BA_ "UserSigValidity" SG_ 905 RR_SEAWarn 0;
BA_ "NetworkRequest" SG_ 905 RR_SEAWarn 0;
BA_ "Version" SG_ 905 RR_SEAWarn "21.07.07";
BA_ "GenSigSendType" SG_ 905 RR_SEWWarn 4;
BA_ "UserSigValidity" SG_ 905 RR_SEWWarn 0;
BA_ "NetworkRequest" SG_ 905 RR_SEWWarn 0;
BA_ "Version" SG_ 905 RR_SEWWarn "21.07.07";
BA_ "GenSigSendType" SG_ 905 RR_ReleaseWarn 4;
BA_ "UserSigValidity" SG_ 905 RR_ReleaseWarn 0;
BA_ "NetworkRequest" SG_ 905 RR_ReleaseWarn 0;
BA_ "NetworkRequestHoldingTime" SG_ 905 RR_ReleaseWarn 5000;
BA_ "Version" SG_ 905 RR_ReleaseWarn "21.09.05";
BA_ "GenSigSendType" SG_ 905 RR_SWFailAlarm 4;
BA_ "UserSigValidity" SG_ 905 RR_SWFailAlarm 0;
BA_ "NetworkRequest" SG_ 905 RR_SWFailAlarm 0;
BA_ "NetworkRequestHoldingTime" SG_ 905 RR_SWFailAlarm 5000;
BA_ "Version" SG_ 905 RR_SWFailAlarm "21.07.07";
BA_ "GenSigSendType" SG_ 905 RR_ChildLock_ActnFlSta 4;
BA_ "UserSigValidity" SG_ 905 RR_ChildLock_ActnFlSta 0;
BA_ "NetworkRequest" SG_ 905 RR_ChildLock_ActnFlSta 0;
BA_ "NetworkRequestHoldingTime" SG_ 905 RR_ChildLock_ActnFlSta 5000;
BA_ "Version" SG_ 905 RR_ChildLock_ActnFlSta "21.07.07";
BA_ "GenSigSendType" SG_ 905 RR_MRActivationAlarm 4;
BA_ "UserSigValidity" SG_ 905 RR_MRActivationAlarm 0;
BA_ "NetworkRequest" SG_ 905 RR_MRActivationAlarm 0;
BA_ "NetworkRequestHoldingTime" SG_ 905 RR_MRActivationAlarm 5000;
BA_ "Version" SG_ 905 RR_MRActivationAlarm "21.07.07";
BA_ "GenSigSendType" SG_ 905 RR_ChildLock_Status 4;
BA_ "UserSigValidity" SG_ 905 RR_ChildLock_Status 0;
BA_ "NetworkRequest" SG_ 905 RR_ChildLock_Status 0;
BA_ "NetworkRequestHoldingTime" SG_ 905 RR_ChildLock_Status 5000;
BA_ "Version" SG_ 905 RR_ChildLock_Status "21.07.07";
BA_ "GenSigSendType" SG_ 905 USM_RRGhostDoorSta 4;
BA_ "UserSigValidity" SG_ 905 USM_RRGhostDoorSta 0;
BA_ "NetworkRequest" SG_ 905 USM_RRGhostDoorSta 0;
BA_ "NetworkRequestHoldingTime" SG_ 905 USM_RRGhostDoorSta 5000;
BA_ "Version" SG_ 905 USM_RRGhostDoorSta "21.07.07";
BA_ "GenSigSendType" SG_ 905 DoorLock_PDSLkSwSta_RR 4;
BA_ "UserSigValidity" SG_ 905 DoorLock_PDSLkSwSta_RR 0;
BA_ "NetworkRequest" SG_ 905 DoorLock_PDSLkSwSta_RR 0;
BA_ "Version" SG_ 905 DoorLock_PDSLkSwSta_RR "21.09.05";
BA_ "GenSigSendType" SG_ 905 PDS_TypeOption_RR 4;
BA_ "UserSigValidity" SG_ 905 PDS_TypeOption_RR 0;
BA_ "NetworkRequest" SG_ 905 PDS_TypeOption_RR 0;
BA_ "Version" SG_ 905 PDS_TypeOption_RR "21.07.07";
BA_ "GenSigSendType" SG_ 905 RRDoorPushAlarm 4;
BA_ "UserSigValidity" SG_ 905 RRDoorPushAlarm 0;
BA_ "NetworkRequest" SG_ 905 RRDoorPushAlarm 0;
BA_ "NetworkRequestHoldingTime" SG_ 905 RRDoorPushAlarm 5000;
BA_ "Version" SG_ 905 RRDoorPushAlarm "21.07.07";
BA_ "GenMsgCycleTime" BO_ 1964 0;
BA_ "GenMsgCycleTimeFast" BO_ 1964 0;
BA_ "GenMsgNrOfRepetition" BO_ 1964 0;
BA_ "DiagResponse" BO_ 1964 1;
BA_ "GenMsgILSupport" BO_ 1964 0;
BA_ "TpMessage" BO_ 1964 1;
BA_ "TpTxIndex" BO_ 1964 172;
BA_ "Description" SG_ 1964 SCM_GST_Byte0 "TP Index : 172";
BA_ "UsrSigPurpose" SG_ 1964 SCM_GST_Byte0 4;
BA_ "UserSigValidity" SG_ 1964 SCM_GST_Byte0 0;
BA_REL_ "GenSigTimeoutTime" BU_SG_REL_ CGW_CCU SG_ 1964 SCM_GST_Byte0 0;
BA_ "NetworkRequest" SG_ 1964 SCM_GST_Byte0 0;
BA_ "NetworkRequestHoldingTime" SG_ 1964 SCM_GST_Byte0 5000;
BA_ "Version" SG_ 1964 SCM_GST_Byte0 "22.07.01";
BA_ "Description" SG_ 1964 SCM_GST_Byte2 "TP Index : 172";
BA_ "UsrSigPurpose" SG_ 1964 SCM_GST_Byte2 4;
BA_ "UserSigValidity" SG_ 1964 SCM_GST_Byte2 0;
BA_REL_ "GenSigTimeoutTime" BU_SG_REL_ CGW_CCU SG_ 1964 SCM_GST_Byte2 0;
BA_ "NetworkRequest" SG_ 1964 SCM_GST_Byte2 0;
BA_ "NetworkRequestHoldingTime" SG_ 1964 SCM_GST_Byte2 5000;
BA_ "Version" SG_ 1964 SCM_GST_Byte2 "22.07.01";
BA_ "Description" SG_ 1964 SCM_GST_Byte3 "TP Index : 172";
BA_ "UsrSigPurpose" SG_ 1964 SCM_GST_Byte3 4;
BA_ "UserSigValidity" SG_ 1964 SCM_GST_Byte3 0;
BA_REL_ "GenSigTimeoutTime" BU_SG_REL_ CGW_CCU SG_ 1964 SCM_GST_Byte3 0;
BA_ "NetworkRequest" SG_ 1964 SCM_GST_Byte3 0;
BA_ "NetworkRequestHoldingTime" SG_ 1964 SCM_GST_Byte3 5000;
BA_ "Version" SG_ 1964 SCM_GST_Byte3 "22.07.01";
BA_ "Description" SG_ 1964 SCM_GST_Byte4 "TP Index : 172";
BA_ "UsrSigPurpose" SG_ 1964 SCM_GST_Byte4 4;
BA_ "UserSigValidity" SG_ 1964 SCM_GST_Byte4 0;
BA_REL_ "GenSigTimeoutTime" BU_SG_REL_ CGW_CCU SG_ 1964 SCM_GST_Byte4 0;
BA_ "NetworkRequest" SG_ 1964 SCM_GST_Byte4 0;
BA_ "NetworkRequestHoldingTime" SG_ 1964 SCM_GST_Byte4 5000;
BA_ "Version" SG_ 1964 SCM_GST_Byte4 "22.07.01";
BA_ "Description" SG_ 1964 SCM_GST_Byte5 "TP Index : 172";
BA_ "UsrSigPurpose" SG_ 1964 SCM_GST_Byte5 4;
BA_ "UserSigValidity" SG_ 1964 SCM_GST_Byte5 0;
BA_REL_ "GenSigTimeoutTime" BU_SG_REL_ CGW_CCU SG_ 1964 SCM_GST_Byte5 0;
BA_ "NetworkRequest" SG_ 1964 SCM_GST_Byte5 0;
BA_ "NetworkRequestHoldingTime" SG_ 1964 SCM_GST_Byte5 5000;
BA_ "Version" SG_ 1964 SCM_GST_Byte5 "22.07.01";
BA_ "Description" SG_ 1964 SCM_GST_Byte6 "TP Index : 172";
BA_ "UsrSigPurpose" SG_ 1964 SCM_GST_Byte6 4;
BA_ "UserSigValidity" SG_ 1964 SCM_GST_Byte6 0;
BA_REL_ "GenSigTimeoutTime" BU_SG_REL_ CGW_CCU SG_ 1964 SCM_GST_Byte6 0;
BA_ "NetworkRequest" SG_ 1964 SCM_GST_Byte6 0;
BA_ "NetworkRequestHoldingTime" SG_ 1964 SCM_GST_Byte6 5000;
BA_ "Version" SG_ 1964 SCM_GST_Byte6 "22.07.01";
BA_ "Description" SG_ 1964 SCM_GST_Byte7 "TP Index : 172";
BA_ "UsrSigPurpose" SG_ 1964 SCM_GST_Byte7 4;
BA_ "UserSigValidity" SG_ 1964 SCM_GST_Byte7 0;
BA_REL_ "GenSigTimeoutTime" BU_SG_REL_ CGW_CCU SG_ 1964 SCM_GST_Byte7 0;
BA_ "NetworkRequest" SG_ 1964 SCM_GST_Byte7 0;
BA_ "NetworkRequestHoldingTime" SG_ 1964 SCM_GST_Byte7 5000;
BA_ "Version" SG_ 1964 SCM_GST_Byte7 "22.07.01";
BA_ "Description" SG_ 1964 SCM_GST_Byte1 "TP Index : 172";
BA_ "UsrSigPurpose" SG_ 1964 SCM_GST_Byte1 4;
BA_ "UserSigValidity" SG_ 1964 SCM_GST_Byte1 0;
BA_REL_ "GenSigTimeoutTime" BU_SG_REL_ CGW_CCU SG_ 1964 SCM_GST_Byte1 0;
BA_ "NetworkRequest" SG_ 1964 SCM_GST_Byte1 0;
BA_ "NetworkRequestHoldingTime" SG_ 1964 SCM_GST_Byte1 5000;
BA_ "Version" SG_ 1964 SCM_GST_Byte1 "22.07.01";
BA_ "GenMsgCycleTime" BO_ 1967 0;
BA_ "GenMsgCycleTimeFast" BO_ 1967 0;
BA_ "GenMsgNrOfRepetition" BO_ 1967 0;
BA_ "DiagResponse" BO_ 1967 1;
BA_ "GenMsgILSupport" BO_ 1967 0;
BA_ "TpMessage" BO_ 1967 1;
BA_ "TpTxIndex" BO_ 1967 175;
BA_ "Description" SG_ 1967 SWRC_GST_Byte0 "TP Index : 175";
BA_ "UsrSigPurpose" SG_ 1967 SWRC_GST_Byte0 4;
BA_ "UserSigValidity" SG_ 1967 SWRC_GST_Byte0 0;
BA_REL_ "GenSigTimeoutTime" BU_SG_REL_ CGW_CCU SG_ 1967 SWRC_GST_Byte0 0;
BA_ "NetworkRequest" SG_ 1967 SWRC_GST_Byte0 0;
BA_ "NetworkRequestHoldingTime" SG_ 1967 SWRC_GST_Byte0 5000;
BA_ "Version" SG_ 1967 SWRC_GST_Byte0 "22.07.01";
BA_ "Description" SG_ 1967 SWRC_GST_Byte2 "TP Index : 175";
BA_ "UsrSigPurpose" SG_ 1967 SWRC_GST_Byte2 4;
BA_ "UserSigValidity" SG_ 1967 SWRC_GST_Byte2 0;
BA_REL_ "GenSigTimeoutTime" BU_SG_REL_ CGW_CCU SG_ 1967 SWRC_GST_Byte2 0;
BA_ "NetworkRequest" SG_ 1967 SWRC_GST_Byte2 0;
BA_ "NetworkRequestHoldingTime" SG_ 1967 SWRC_GST_Byte2 5000;
BA_ "Version" SG_ 1967 SWRC_GST_Byte2 "22.07.01";
BA_ "Description" SG_ 1967 SWRC_GST_Byte3 "TP Index : 175";
BA_ "UsrSigPurpose" SG_ 1967 SWRC_GST_Byte3 4;
BA_ "UserSigValidity" SG_ 1967 SWRC_GST_Byte3 0;
BA_REL_ "GenSigTimeoutTime" BU_SG_REL_ CGW_CCU SG_ 1967 SWRC_GST_Byte3 0;
BA_ "NetworkRequest" SG_ 1967 SWRC_GST_Byte3 0;
BA_ "NetworkRequestHoldingTime" SG_ 1967 SWRC_GST_Byte3 5000;
BA_ "Version" SG_ 1967 SWRC_GST_Byte3 "22.07.01";
BA_ "Description" SG_ 1967 SWRC_GST_Byte4 "TP Index : 175";
BA_ "UsrSigPurpose" SG_ 1967 SWRC_GST_Byte4 4;
BA_ "UserSigValidity" SG_ 1967 SWRC_GST_Byte4 0;
BA_REL_ "GenSigTimeoutTime" BU_SG_REL_ CGW_CCU SG_ 1967 SWRC_GST_Byte4 0;
BA_ "NetworkRequest" SG_ 1967 SWRC_GST_Byte4 0;
BA_ "NetworkRequestHoldingTime" SG_ 1967 SWRC_GST_Byte4 5000;
BA_ "Version" SG_ 1967 SWRC_GST_Byte4 "22.07.01";
BA_ "Description" SG_ 1967 SWRC_GST_Byte5 "TP Index : 175";
BA_ "UsrSigPurpose" SG_ 1967 SWRC_GST_Byte5 4;
BA_ "UserSigValidity" SG_ 1967 SWRC_GST_Byte5 0;
BA_REL_ "GenSigTimeoutTime" BU_SG_REL_ CGW_CCU SG_ 1967 SWRC_GST_Byte5 0;
BA_ "NetworkRequest" SG_ 1967 SWRC_GST_Byte5 0;
BA_ "NetworkRequestHoldingTime" SG_ 1967 SWRC_GST_Byte5 5000;
BA_ "Version" SG_ 1967 SWRC_GST_Byte5 "22.07.01";
BA_ "Description" SG_ 1967 SWRC_GST_Byte6 "TP Index : 175";
BA_ "UsrSigPurpose" SG_ 1967 SWRC_GST_Byte6 4;
BA_ "UserSigValidity" SG_ 1967 SWRC_GST_Byte6 0;
BA_REL_ "GenSigTimeoutTime" BU_SG_REL_ CGW_CCU SG_ 1967 SWRC_GST_Byte6 0;
BA_ "NetworkRequest" SG_ 1967 SWRC_GST_Byte6 0;
BA_ "NetworkRequestHoldingTime" SG_ 1967 SWRC_GST_Byte6 5000;
BA_ "Version" SG_ 1967 SWRC_GST_Byte6 "22.07.01";
BA_ "Description" SG_ 1967 SWRC_GST_Byte7 "TP Index : 175";
BA_ "UsrSigPurpose" SG_ 1967 SWRC_GST_Byte7 4;
BA_ "UserSigValidity" SG_ 1967 SWRC_GST_Byte7 0;
BA_REL_ "GenSigTimeoutTime" BU_SG_REL_ CGW_CCU SG_ 1967 SWRC_GST_Byte7 0;
BA_ "NetworkRequest" SG_ 1967 SWRC_GST_Byte7 0;
BA_ "NetworkRequestHoldingTime" SG_ 1967 SWRC_GST_Byte7 5000;
BA_ "Version" SG_ 1967 SWRC_GST_Byte7 "22.07.01";
BA_ "Description" SG_ 1967 SWRC_GST_Byte1 "TP Index : 175";
BA_ "UsrSigPurpose" SG_ 1967 SWRC_GST_Byte1 4;
BA_ "UserSigValidity" SG_ 1967 SWRC_GST_Byte1 0;
BA_REL_ "GenSigTimeoutTime" BU_SG_REL_ CGW_CCU SG_ 1967 SWRC_GST_Byte1 0;
BA_ "NetworkRequest" SG_ 1967 SWRC_GST_Byte1 0;
BA_ "NetworkRequestHoldingTime" SG_ 1967 SWRC_GST_Byte1 5000;
BA_ "Version" SG_ 1967 SWRC_GST_Byte1 "22.07.01";
VAL_ 2151682561 ACU_ACTSAFETY_Crc1Val 0 "0x0x0~0xFFFF:CRCValue" 65535 "0x0x0~0xFFFF:CRCValue" ;
VAL_ 2151682561 ACU_ACTSAFETY_AlvCnt1Val 0 "0x0x0~0xFF:AlvCntValue" 255 "0x0x0~0xFF:AlvCntValue" ;
VAL_ 2151682561 ACU_ACLOSER_WdwAct 0 "ACLOSER_Wdw Inactive" 1 "ACLOSER_Wdw Full close" 2 "ACLOSER_Wdw 10% open" 3 "ACLOSER_Wdw 20% open" 4 "ACLOSER_Wdw 30% open" 5 "ACLOSER_Wdw 40% open" 6 "ACLOSER_Wdw 50% open" 7 "ACLOSER_Wdw 60% open" 8 "RESERVED" 9 "RESERVED" 10 "RESERVED" 11 "RESERVED" 12 "RESERVED" 13 "RESERVED" 14 "RESERVED" 15 "Invalid" ;
VAL_ 2151682561 ACU_ACLOSER_RoofAct 0 "ACLOSER_Roof Inactive" 1 "ACLOSER_Roof Full close" 2 "ACLOSER_Roof 10% open" 3 "ACLOSER_Roof 20% open" 4 "ACLOSER_Roof 30% open" 5 "ACLOSER_Roof 40% open" 6 "ACLOSER_Roof 50% open" 7 "ACLOSER_Roof 60% open" 8 "RESERVED" 9 "RESERVED" 10 "RESERVED" 11 "RESERVED" 12 "RESERVED" 13 "RESERVED" 14 "RESERVED" 15 "Invalid" ;
VAL_ 2235651329 APSB_Crc1Val 0 "0x0x0~0xFFFF:CRCValue" 65535 "0x0x0~0xFFFF:CRCValue" ;
VAL_ 2235651329 APSB_AlvCnt1Val 0 "0x0x0~0xFF:AlvCntValue" 255 "0x0x0~0xFF:AlvCntValue" ;
VAL_ 2235651329 APSB_CrashActvSta 0 "APSB Inactive" 1 "APSB is active" 2 "Rserved" 3 "Rserved" ;
VAL_ 2235651329 APSB_RRDrvImpt 0 "Rough Road Impact is Inactive" 1 "Rough Road  Impact is PSB Front Active" 2 "Rough Road  Impact is PSB Rear Active" 3 "Rough Road  Impact is Failure" 4 "Reserved" 5 "Reserved" 6 "Reserved" 7 "Reserved" ;
VAL_ 2235651329 APSB_FCAFrImpt 0 "FCA Impact is Inactive" 1 "FCA Impact is PSB Front Active" 2 "FCA Impact is PSB Rear Active" 3 "FCA Impact is Failure" 4 "Reserved" 5 "Reserved" 6 "Reserved" 7 "Reserved" ;
VAL_ 2235651329 APSB_MinFrImpt 0 "Minor Front Impact is Inactive" 1 "Minor Front Impact is PSB Front Active" 2 "Minor Front Impact is PSB Rear Active" 3 "Minor Front Impact is Failure" 4 "Reserved" 5 "Reserved" 6 "Reserved" 7 "Reserved" ;
VAL_ 2235651329 APSB_MinSidImpt 0 "Minor Side Impact is Inactive" 1 "Minor Side Impact is PSB Front Active" 2 "Minor Side Impact is PSB Rear Active" 3 "Minor Side Impact is Failure" 4 "Reserved" 5 "Reserved" 6 "Reserved" 7 "Reserved" ;
VAL_ 2235651329 APSB_MinRollDetn 0 "Minor Roll Detection is Inactive" 1 "Minor Roll Detection  is PSB Front Active" 2 "Minor Roll Detection  is PSB Rear Active" 3 "Minor Roll Detection  is Failure" 4 "Reserved" 5 "Reserved" 6 "Reserved" 7 "Reserved" ;
VAL_ 2235651329 APSB_MinRearImpt 0 "Minor Rear Impact is Inactive" 1 "Minor Rear Impact is PSB Front Active" 2 "Minor Rear Impact is PSB Rear Active" 3 "Minor Rear Impact is Failure" 4 "Reserved" 5 "Reserved" 6 "Reserved" 7 "Reserved" ;
VAL_ 1007 ATS_LEDBgtnsUpDn 0 "Reserved" 1 "Brightness Up" 2 "Brightness Down" 3 "Invalid" ;
VAL_ 1007 ATS_FrMoodOn_Req 0 "Default" 1 "Off" 2 "On" 3 "Invalid" ;
VAL_ 1007 ATS_DoorOn_Req 0 "Default" 1 "Off" 2 "On" 3 "Invalid" ;
VAL_ 1007 ATS_RrMapLftOn_Req 0 "Default" 1 "Off" 2 "On" 3 "Invalid" ;
VAL_ 1007 ATS_RrMapRtOn_Req 0 "Default" 1 "Off" 2 "On" 3 "Invalid" ;
VAL_ 1007 ATS_RrRoomOn_Req 0 "Default" 1 "Off" 2 "On" 3 "Invalid" ;
VAL_ 1007 ATS_LEDClrUpDn 0 "Reserved" 1 "Color Up" 2 "Color Down" 3 "Invalid" ;
VAL_ 1007 ATS_RrMoodOn_Req 0 "Default" 1 "Off" 2 "On" 3 "Invalid" ;
VAL_ 1007 ATS_LEDClr_Set 0 "Color 1Step" 1 "Color 2Step" 2 "Color 3Step" 3 "Not Used" 4 "Not Used" 5 "Not Used" 6 "Invalid" 7 "System Fail" ;
VAL_ 1007 ATS_LEDBgtns_Set 0 "Brightness 1Step" 1 "Brightness 2Step" 2 "Brightness 3Step" 3 "Not Used" 4 "Not Used" 5 "Not Used" 6 "Invalid" 7 "System Fail" ;
VAL_ 1007 ATS_LEDClrUpDnBtn 0 "Button Off" 1 "Color Up" 2 "Color Down" 3 "Invalid" ;
VAL_ 1007 ATS_LEDBgtnsUpDnBtn 0 "Button Off" 1 "Brightness Up" 2 "Brightness Down" 3 "Invalid" ;
VAL_ 1007 ATS_FrMapLftOn_Req 0 "Default" 1 "Off" 2 "On" 3 "Invalid" ;
VAL_ 1007 ATS_FrMapRtOn_Req 0 "Default" 1 "Off" 2 "On" 3 "Invalid" ;
VAL_ 1007 ATS_FrRoomOn_Req 0 "Default" 1 "Off" 2 "On" 3 "Invalid" ;
VAL_ 992 BCM_Crc2Val 0 "0x0x0~0xFF:CRCValue" 255 "0x0x0~0xFF:CRCValue" ;
VAL_ 992 BCM_AlvCnt2Val 0 "AlvCntValue" 1 "AlvCntValue" 2 "AlvCntValue" 3 "AlvCntValue" 4 "AlvCntValue" 5 "AlvCntValue" 6 "AlvCntValue" 7 "AlvCntValue" 8 "AlvCntValue" 9 "AlvCntValue" 10 "AlvCntValue" 11 "AlvCntValue" 12 "AlvCntValue" 13 "AlvCntValue" 14 "AlvCntValue" 15 "AlvCntValue" ;
VAL_ 992 BAlarm_BglrAlrmCurrentSta 0 "Off" 1 "DisArm" 2 "Arm" 3 "PreArm" 4 "ArmWait" 5 "ArmHold(Trunk)" 6 "ReArm" 7 "AutoLockTimer1" 8 "AutoLockTimer2" 9 "Alarm" 10 "Default" 11 "AutoLockTimer3(Tailgate)" 12 "Reserved" 13 "Reserved" 14 "Not Used" 15 "Error Indicator" ;
VAL_ 992 BAlarm_BglrAlrmSta 0 "DIS-,PRE-,AUTOLOCKTIMER1,2,3(TG)" 1 "ARM,-WAIT,RE-,ALARM,-HD(Trunk)" 2 "Not Used" 3 "Error Indicator" ;
VAL_ 992 BAlarm_PncAlrmSta 0 "Off" 1 "On (Panic Alarm ON)" 2 "Not Used" 3 "Error Indicator" ;
VAL_ 992 BAlarm_BrglrHrnRlySta 0 "Off" 1 "On" 2 "Not Used" 3 "Error Indicator" ;
VAL_ 992 BCM_KeyInSta 0 "Off (Key removed)" 1 "On (Key inserted)" 2 "Not Used" 3 "Error Indicator" ;
VAL_ 992 BCM_AccInSta 0 "Acc Off" 1 "Acc On" 2 "Not Used" 3 "Error Indicator" ;
VAL_ 992 BCM_Ign1InSta 0 "IGN1 Off" 1 "IGN1 On" 2 "Not Used" 3 "Error Indicator" ;
VAL_ 992 BCM_Ign2InSta 0 "IGN2 Off" 1 "IGN2 On" 2 "Not Used" 3 "Error Indicator" ;
VAL_ 994 BCM_Crc4Val 0 "0x0x0~0xFF:CRCValue" 255 "0x0x0~0xFF:CRCValue" ;
VAL_ 994 BCM_AlvCnt4Val 0 "AlvCntValue" 1 "AlvCntValue" 2 "AlvCntValue" 3 "AlvCntValue" 4 "AlvCntValue" 5 "AlvCntValue" 6 "AlvCntValue" 7 "AlvCntValue" 8 "AlvCntValue" 9 "AlvCntValue" 10 "AlvCntValue" 11 "AlvCntValue" 12 "AlvCntValue" 13 "AlvCntValue" 14 "AlvCntValue" 15 "AlvCntValue" ;
VAL_ 994 Warn_BzrWrngSta 0 "Off" 1 "SeatBelt Warning" 2 "Key Operated Warning" 3 "Parking Brake Warning" 4 "Sun Roof Open Warning" 5 "Key Learning Sound(NoSMKOption" 6 "ICE Warning" 7 "Rear Fog Warning" 8 "Reserved" 9 "Reserved" 10 "Reserved" 11 "Reserved" 12 "Reserved" 13 "Reserved" 14 "Not Used" 15 "Error Indicator" ;
VAL_ 994 Warn_BCMWrngSta 0 "Off" 1 "Power off request warning" 2 "Shift P request Warning" 3 "Shift P Warning 2 (Pwr Off, Shift Enable)" 4 "Shift P Warning 2 (Pwr Off, Shift Disable)" 5 "Shift P Warning 2 (Pwr On, Shift Enable)" 6 "Shift P Warning 2 (Pwr On, Shift Disable)" 7 "RESERVED" 8 "RESERVED" 9 "RESERVED" 10 "RESERVED" 11 "RESERVED" 12 "RESERVED" 13 "RESERVED" 14 "Not Used" 15 "Error Indicator" ;
VAL_ 994 ROA_RrBlwAutoOffReq 0 "default" 1 "Request of Rear Blow Off (auto Cut)" 2 "Not Used" 3 "Error Indciator" ;
VAL_ 994 ROA_RegionOpt 0 "Non Euro NCAP CPD" 1 "Euro NCAP CPD" 2 "Reserved" 3 "Error Indicator" ;
VAL_ 994 Warn_RrStRmndOpt 0 "Not apply RrSeatRemind" 1 "Apply RrSeatRemind" 2 "Apply Radar ROA sensor" 3 "Error Indicator" ;
VAL_ 994 Warn_RrStRmndAlrmOnReq 0 "Off" 1 "On(Alarm)" 2 "Not Used" 3 "Error Indicator" ;
VAL_ 994 Warn_RrStRmndSysSta 0 "Default" 1 "System ON" 2 "System OFF" 3 "Error Indicator" ;
VAL_ 994 Warn_RrStRmndAlrmInfo 0 "Off" 1 "Rear Seat Reminder" 2 "Rear Seat Reminder 1st Only" 3 "Delayed ROA" 4 "Reserved" 5 "Reseved" 6 "Not Used" 7 "Error Indicator" ;
VAL_ 994 Warn_RoaErr 0 "Off" 1 "SensorError( Malfunction)" 2 "Reserved" 3 "Reserved" 4 "Reserved" 5 "Reseved" 6 "Not Used" 7 "Error Indicator" ;
VAL_ 994 WAL_FobSearching 0 "Not Fob Exist" 1 "Fob Exist" 2 "Reserved" 3 "Error Indicator" ;
VAL_ 994 Warn_RrStRmndDelay 0 "Off" 1 "Delayed ROA" 2 "Not Used" 3 "Error Indicator" ;
VAL_ 994 Warn_RrStRmndSysAct 0 "Default" 1 "Deactivation" 2 "Off" 3 "Error Indicator" ;
VAL_ 994 Warn_RrStRmndSysOffIND 0 "Indicator Off" 1 "Indicator On" 2 "Not Used" 3 "Error Indicator" ;
VAL_ 994 Warn_VehNotPWrngSta 0 "Off" 1 "Not P Warning (Pwr Off, Shift Enable)" 2 "Not P Warning (Pwr Off, Shift Disable)" 3 "Not P Warning (Pwr On, Shift Enable)" 4 "Not P Warning (Pwr On, Shift Disable)" 5 "RESERVED" 6 "RESERVED" 7 "Error Indicator" ;
VAL_ 997 BCM_Crc5Val 0 "0x0x0~0xFF:CRCValue" 255 "0x0x0~0xFF:CRCValue" ;
VAL_ 997 BCM_AlvCnt5Val 0 "AlvCntValue" 1 "AlvCntValue" 2 "AlvCntValue" 3 "AlvCntValue" 4 "AlvCntValue" 5 "AlvCntValue" 6 "AlvCntValue" 7 "AlvCntValue" 8 "AlvCntValue" 9 "AlvCntValue" 10 "AlvCntValue" 11 "AlvCntValue" 12 "AlvCntValue" 13 "AlvCntValue" 14 "AlvCntValue" 15 "AlvCntValue" ;
VAL_ 997 PDW_OptTyp 0 "Non" 1 "PDW R" 2 "PDW FR" 3 "Reserved" 4 "PDW-R (w/ 1st Corner Warning)" 5 "PDW-FR (w/ 1st Corner Warning)" 6 "Not Used" 7 "Error Indicator" ;
VAL_ 997 PDW_SysChkSndSta 0 "Off" 1 "R_Confirm" 2 "Error" 3 "Reserved" 4 "Reserved" 5 "Reseved" 6 "Not Used" 7 "Error Indicator" ;
VAL_ 997 PDW_SwIndOnReq 0 "Indicator Off" 1 "Indicator On" 2 "Not Used" 3 "Error Indicator" ;
VAL_ 997 PDW_FrCtWrngLvlDis 0 "Off" 1 "1st warning" 2 "2nd warning" 3 "3rd warning" 4 "Error" 5 "Gray" 6 "Not Used" 7 "Error Indicator" ;
VAL_ 997 PDW_SysFlrSta 0 "No Display" 1 "Unable by Ultrasonic" 2 "PDW Failure" 3 "Error Indicator" ;
VAL_ 997 PDW_FrCtWrngSndSta 0 "Off" 1 "1st warning" 2 "2nd warning" 3 "3rd warning" 4 "Reserved" 5 "Reseved" 6 "Not Used" 7 "Error Indicator" ;
VAL_ 997 PDW_FrLtWrngLvlDis 0 "Off" 1 "1st warning" 2 "2nd warning" 3 "3rd warning" 4 "Error" 5 "Gray" 6 "Not Used" 7 "Error Indicator" ;
VAL_ 997 PDW_CRBdDis 0 "Normal (No display)" 1 "Car Body Display" 2 "Reserved" 3 "Error Indicator" ;
VAL_ 997 PDW_FrRtWrngLvlDis 0 "Off" 1 "1st warning" 2 "2nd warning" 3 "3rd warning" 4 "Error" 5 "Gray" 6 "Not Used" 7 "Error Indicator" ;
VAL_ 997 PU_F_Group7_DrvrAsstFlr11Sta 0 "Not Display" 1 "Failure" 2 "Ultrasonic sensor Blockage" 3 "Error Indicator" ;
VAL_ 997 PDW_FrSnsrWrngLvlSta 0 "Off" 1 "1st Waring" 2 "2nd Waring" 3 "3rd Warning" 4 "Reserved" 5 "Reseved" 6 "Not Used" 7 "Error Indicator" ;
VAL_ 1002 BLTN_CAM_HU_UI_Mode 0 "HU UI mode." 1 "BLTN_CAM mode" 2 "Preparing BLTN_CAM Mode" 3 "BLTN_CAM Setting Mode" 4 "RESERVED" 5 "RESERVED" 6 "RESERVED" 7 "RESERVED" 8 "RESERVED" 9 "RESERVED" 10 "RESERVED" 11 "RESERVED" 12 "RESERVED" 13 "BLTN_CAM Not Ready to be HU UI Mode" 14 "BLTN_CAM is in Error mode." 15 "Invalid" ;
VAL_ 1002 BLTN_CAM_SD_Format_Op_State 0 "Default" 1 "Formatting" 2 "Format Complete." 3 "invalid" ;
VAL_ 1002 BLTN_CAM_PEV_Recorded 0 "Default" 1 "Off" 2 "Park Event Recorded" 3 "invalid" ;
VAL_ 1002 BLTN_CAM_PEV_Count 0 "0x0x0~0xC8:the number of the Park Event Record(0~200)" 200 "0x0x0~0xC8:the number of the Park Event Record(0~200)" 201 "Reserved" 202 "Reserved" 203 "Reserved" 204 "Reserved" 205 "Reserved" 206 "Reserved" 207 "Reserved" 208 "Reserved" 209 "Reserved" 210 "Reserved" 211 "Reserved" 212 "Reserved" 213 "Reserved" 214 "Reserved" 215 "Reserved" 216 "Reserved" 217 "Reserved" 218 "Reserved" 219 "Reserved" 220 "Reserved" 221 "Reserved" 222 "Reserved" 223 "Reserved" 224 "Reserved" 225 "Reserved" 226 "Reserved" 227 "Reserved" 228 "Reserved" 229 "Reserved" 230 "Reserved" 231 "Reserved" 232 "Reserved" 233 "Reserved" 234 "Reserved" 235 "Reserved" 236 "Reserved" 237 "Reserved" 238 "Reserved" 239 "Reserved" 240 "Reserved" 241 "Reserved" 242 "Reserved" 243 "Reserved" 244 "Reserved" 245 "Reserved" 246 "Reserved" 247 "Reserved" 248 "Reserved" 249 "Reserved" 250 "Reserved" 251 "Reserved" 252 "Reserved" 253 "Over than 200 count" 254 "the park event record is not recorded" 255 "invalid" ;
VAL_ 1002 BLTN_CAM_Ind_Req 0 "Default" 1 "Built-in Cam System or Camera Error" 2 "Manual Recording or Event Recording" 3 "Time-lapse Recording" 4 "Built-in Cam SD Card Replace Warning or SD Card Error" 5 "On while Driving Recording" 6 "On while Parked Recording" 7 "Smartphone Connected" 8 "RESERVED" 9 "RESERVED" 10 "RESERVED" 11 "RESERVED" 12 "RESERVED" 13 "RESERVED" 14 "RESERVED" 15 "RESERVED" 16 "RESERVED" 17 "RESERVED" 18 "RESERVED" 19 "RESERVED" 20 "RESERVED" 21 "RESERVED" 22 "RESERVED" 23 "RESERVED" 24 "RESERVED" 25 "RESERVED" 26 "RESERVED" 27 "RESERVED" 28 "RESERVED" 29 "RESERVED" 30 "RESERVED" 31 "Invalid" ;
VAL_ 1002 BLTN_CAM_LVDS_Mode_State 0 "Front and Rear Camera" 1 "Front Camera for AR Navi." 2 "Built-In Cam Engineer Mode" 3 "Reserved" ;
VAL_ 1002 BLTN_CAM_PrkOp_Termiate_Info 0 "Default" 1 "Park operation terminated earlier than user set because of Bat. SoC" 2 "Park operation terminated earlier than user set because of SD Card Problem" 3 "Park operation terminated earlier than user set because of Built-in Cam internal Error" 4 "Park operation terminated earlier than user set because of SD Card removed or not detected" 5 "Park operation started because of SD Card inserted" 6 "Park operation terminate on time which user set." 7 "Invalid" ;
VAL_ 1002 BLTN_CAM_DEV_Recorded 0 "Default" 1 "Off" 2 "Drive Event Recorded" 3 "Invalid" ;
VAL_ 1002 BLTN_CAM_DEV_Count 0 "0x0x0~0xC8:the number of the Drive Event Record(0~200)" 200 "0x0x0~0xC8:the number of the Drive Event Record(0~200)" 201 "RESERVED" 202 "RESERVED" 203 "RESERVED" 204 "RESERVED" 205 "RESERVED" 206 "RESERVED" 207 "RESERVED" 208 "RESERVED" 209 "RESERVED" 210 "RESERVED" 211 "RESERVED" 212 "RESERVED" 213 "RESERVED" 214 "RESERVED" 215 "RESERVED" 216 "RESERVED" 217 "RESERVED" 218 "RESERVED" 219 "RESERVED" 220 "RESERVED" 221 "RESERVED" 222 "RESERVED" 223 "RESERVED" 224 "RESERVED" 225 "RESERVED" 226 "RESERVED" 227 "RESERVED" 228 "RESERVED" 229 "RESERVED" 230 "RESERVED" 231 "RESERVED" 232 "RESERVED" 233 "RESERVED" 234 "RESERVED" 235 "RESERVED" 236 "RESERVED" 237 "RESERVED" 238 "RESERVED" 239 "RESERVED" 240 "RESERVED" 241 "RESERVED" 242 "RESERVED" 243 "RESERVED" 244 "RESERVED" 245 "RESERVED" 246 "RESERVED" 247 "RESERVED" 248 "RESERVED" 249 "RESERVED" 250 "RESERVED" 251 "RESERVED" 252 "RESERVED" 254 "the drive event record is not recordable" 255 "Invalid" ;
VAL_ 1002 BLTN_CAM_Display 0 "HU mode" 1 "Built-in Cam mode" 2 "popup mode" 3 "Built-in Cam mode Terminate Request by Home-button" 4 "Built-in Cam mode Terminate Request by Back-button" 5 "Built-in Cam update mode" 6 "Ready to update" 7 "Update complete" 8 "USB removed" 9 "Update fail (USB error)" 10 "Reserved" 11 "Reserved" 12 "Reserved" 13 "Reserved" 14 "Built-in Cam is in error mode" 15 "Invalid" ;
VAL_ 1002 BLTN_CAM_WiFi_State 0 "Off" 1 "On, Ready to Connect Mobile Phone." 2 "On, Mobile Phone Connected." 3 "Off - Password is not Set." 4 "Reserved" 5 "Reserved" 6 "Reserved" 7 "Reserved" 8 "Reserved" 9 "Reserved" 10 "Reserved" 11 "Reserved" 12 "Reserved" 13 "Reserved" 14 "Reserved" 15 "invalid" ;
VAL_ 2353206529 CLU_Crc20Val 0 "0x0x0~0xFFFF:CRCValue" 65535 "0x0x0~0xFFFF:CRCValue" ;
VAL_ 2353206529 CLU_AlvCnt20Val 0 "0x0x0~0xFF:AlvCntValue" 255 "0x0x0~0xFF:AlvCntValue" ;
VAL_ 2353206529 CLU_SndType 0 "Cluster applied speaker" 1 "Cluster applied buzzer" 2 "Not used" 3 "Error Indicator" ;
VAL_ 2353206529 USM_AdasHDPSetReq 0 "Default" 1 "OFF" 2 "ON" 3 "INVALID" ;
VAL_ 2353206529 CLU_ClusterUSM 0 "Default" 1 "Cluster not applied USM" 2 "Cluster applied USM" 3 "Reserved" ;
VAL_ 1016 GNSS_MM_type 0 "WGS84" 1 "Bessel" 2 "Coordshift(for china)" 15 "invalid" ;
VAL_ 1019 HU_MoodTherapyDrSeat 0 "Default" 1 "Off" 2 "On" 3 "Invalid" ;
VAL_ 1019 HU_VitalityFragrance 0 "Default" 1 "Off" 2 "On" 3 "Invalid" ;
VAL_ 1019 HU_VitalityCurtain 0 "Default" 1 "Off" 2 "On" 3 "Invalid" ;
VAL_ 1019 HU_DelightMoodLamp 0 "Default" 1 "Off" 2 "On" 3 "Invalid" ;
VAL_ 1019 HU_DelightFragrance 0 "Default" 1 "Off" 2 "On" 3 "Invalid" ;
VAL_ 1019 HU_DelightCurtain 0 "Default" 1 "Off" 2 "On" 3 "Invalid" ;
VAL_ 1019 HU_MoodTherapyPsSeat 0 "Default" 1 "Off" 2 "On" 3 "Invalid" ;
VAL_ 1019 HU_CareMoodLamp 0 "Default" 1 "Off" 2 "On" 3 "Invalid" ;
VAL_ 1019 HU_CareFragrance 0 "Default" 1 "Off" 2 "On" 3 "Invalid" ;
VAL_ 1019 HU_CareMassage 0 "Default" 1 "Off" 2 "On" 3 "Invalid" ;
VAL_ 1019 HU_CareCurtain 0 "Default" 1 "Off" 2 "On" 3 "Invalid" ;
VAL_ 1019 HU_ComfortMoodLamp 0 "Default" 1 "Off" 2 "On" 3 "Invalid" ;
VAL_ 1019 HU_ComfortFragrance 0 "Default" 1 "Off" 2 "On" 3 "Invalid" ;
VAL_ 1019 HU_ComfortMassage 0 "Default" 1 "Off" 2 "On" 3 "Invalid" ;
VAL_ 1019 HU_ComfortCurtain 0 "Default" 1 "Off" 2 "On" 3 "Invalid" ;
VAL_ 1019 HU_MoodTherapyMode 0 "Default" 1 "Off" 2 "Vitality" 3 "Delight" 4 "Care" 5 "Comfort" 6 "Reserved" 7 "Invalid" ;
VAL_ 1019 HU_MoodTherapyRlSeat 0 "Default" 1 "Off" 2 "On" 3 "Invalid" ;
VAL_ 1019 HU_MoodTherapyRrSeat 0 "Default" 1 "Off" 2 "On" 3 "Invalid" ;
VAL_ 1019 HU_VitalityMoodLamp 0 "Default" 1 "Off" 2 "On" 3 "Invalid" ;
VAL_ 902 PSM_DrvStEsyAcsUSMSta 0 "Default Value" 1 "Off (Disable)" 2 "50mmOn (Enable)" 3 "75mmOn (Enable)" 4 "Reserved" 5 "Reserved" 6 "Reserved" 7 "Invalid" ;
VAL_ 902 PSM_SeatPosPlyBck_Sta 0 "Default" 1 "Moving" 2 "Moving Finish" 3 "Moving not Finish" 4 "Not Used" 5 "Not Used" 6 "STOP" 7 "Not Used" ;
VAL_ 902 PSM_SeatPos_Sta 0 "Default" 1 "Memory1" 2 "Memory2" 3 "Memory3" 4 "Not Used" 5 "Not Used" 6 "Not Used" 7 "Any Postion" ;
VAL_ 902 PSM_SeatPosSldLmt_Sta 0 "Default" 1 "Slide Fwd Limit" 2 "Slide Bwd Limit" 3 "Not Initialized" ;
VAL_ 902 PSM_SeatPosRclnLmt_Sta 0 "Default" 1 "Recline Fwd Limit" 2 "Recline Bwd Limit" 3 "Not Initialized" ;
VAL_ 902 SmrtIMS_StatureRspVal 0 "Default" 1 "Less than 147.5cm" 2 "147.5~152.4cm" 3 "152.5~157.4cm" 4 "157.5~162.4cm" 5 "162.5~167.4cm" 6 "167.5~172.4cm" 7 "172.5~177.4cm" 8 "177.5~182.4cm" 9 "182.5~187.4cm" 10 "187.5~192.4cm" 11 "192.5~197.4cm" 12 "More than 197.5cm" 13 "Reserved" 14 "Reserved" 15 "Invalid" ;
VAL_ 902 SmrtIMS_SeatedHghtRspVal 0 "Default" 1 "Tall" 2 "Middle" 3 "Short" 4 "Reserved" 5 "Reserved" 6 "Reserved" 7 "Reserved" 8 "Reserved" 9 "Reserved" 10 "Reserved" 11 "Reserved" 12 "Reserved" 13 "Reserved" 14 "Reserved" 15 "Invalid" ;
VAL_ 902 Drv_2ndAutoFldEnable 0 "Default" 1 "Enable" 2 "Disable" 3 "Invalid" ;
VAL_ 902 SmrtIMS_WghtRspVal 0 "Default" 1 "Under 49.4kg" 2 "49.5~59.4kg" 3 "59.5~69.4kg" 4 "69.5~79.4kg" 5 "79.5~89.4kg" 6 "89.5~99.4kg" 7 "99.5~109.4kg" 8 "109.5~119.4kg" 9 "More than119.5kg" 10 "Reserved" 11 "Reserved" 12 "Reserved" 13 "Reserved" 14 "Reserved" 15 "Invalid" ;
VAL_ 902 SmartIMS_DisReq 0 "Stop" 1 "Moving(recommend position)" 2 "Moving(manual switch, IMS)" 3 "Current Position Analysis" 4 "Move to setting page" 5 "Reserved" 6 "Reserved" 7 "Invalid" ;
VAL_ 902 SmrtIMS_ExitSta 0 "normal" 1 "not IGN" 2 "not P or over 3km/h" 3 "cranking" 4 "seat moving" 5 "PSM is not initialized" 6 "low voltage" 7 "reserved" ;
VAL_ 902 PSM_DrvStRlxTiltUpDis 0 "Default" 1 "Off" 2 "On" 3 "Invalid" ;
VAL_ 902 PSM_DrvStRlxTiltDnDis 0 "Default" 1 "Off" 2 "On" 3 "Invalid" ;
VAL_ 902 PSM_DrvStLegUpDis 0 "Default" 1 "Off" 2 "On" 3 "Invalid" ;
VAL_ 902 PSM_DrvStLegDnDis 0 "Default" 1 "Off" 2 "On" 3 "Invalid" ;
VAL_ 902 Drv_2ndStAutoRlxEnable 0 "Default" 1 "Enable" 2 "Disable" 3 "Invalid" ;
VAL_ 902 Drv_AutoRlxSta 0 "Default" 1 "Auto Relaxion moving" 2 "Reserved" 3 "Invalid" ;
VAL_ 902 Drv_AutoReturnSta 0 "Default" 1 "Auto Return moving" 2 "RESERVED" 3 "Invalid" ;
VAL_ 902 PSM_IMSOptTyp 0 "Default" 1 "IMS Option" 2 "IMS&Smart IMS Option" 3 "Error Indicator" ;
VAL_ 903 PSM_DrvStSldFwdDis 0 "default" 1 "off" 2 "on" 3 "invalid" ;
VAL_ 903 PSM_DrvStTiltDnDis 0 "default" 1 "off" 2 "on" 3 "invalid" ;
VAL_ 903 PSM_DrvStHghtUpDis 0 "default" 1 "off" 2 "on" 3 "invalid" ;
VAL_ 903 PSM_DrvStHghtDnDis 0 "default" 1 "off" 2 "on" 3 "invalid" ;
VAL_ 903 PSM_DrvStCushExtBckwdDis 0 "default" 1 "off" 2 "on" 3 "invalid" ;
VAL_ 903 PSM_DrvStCushExtFwdDis 0 "default" 1 "off" 2 "on" 3 "invalid" ;
VAL_ 903 PSM_DrvStSldBckwdDis 0 "default" 1 "off" 2 "on" 3 "invalid" ;
VAL_ 903 PSM_DrvStHdRstUpDis 0 "default" 1 "off" 2 "on" 3 "invalid" ;
VAL_ 903 PSM_DrvStHdRstDnDis 0 "default" 1 "off" 2 "on" 3 "invalid" ;
VAL_ 903 PSM_DrvStHdRstFwdDis 0 "default" 1 "off" 2 "on" 3 "invalid" ;
VAL_ 903 PSM_DrvStHdRstBckwdDis 0 "default" 1 "off" 2 "on" 3 "invalid" ;
VAL_ 903 PSM_DrvStLmbrDefDis 0 "default" 1 "off" 2 "on" 3 "invalid" ;
VAL_ 903 PSM_DrvStLmbrLoDis 0 "default" 1 "off" 2 "on" 3 "invalid" ;
VAL_ 903 PSM_DrvStLmbrMdlDis 0 "default" 1 "off" 2 "on" 3 "invalid" ;
VAL_ 903 PSM_DrvStLmbrUpDis 0 "default" 1 "off" 2 "on" 3 "invalid" ;
VAL_ 903 PSM_DrvStReclneFwdDis 0 "default" 1 "off" 2 "on" 3 "invalid" ;
VAL_ 903 PSM_DrvStBlstrDefDis 0 "default" 1 "off" 2 "on" 3 "invalid" ;
VAL_ 903 PSM_DrvStBlstrInfDis 0 "default" 1 "off" 2 "on" 3 "invalid" ;
VAL_ 903 PSM_DrvStReclneBckwdDis 0 "default" 1 "off" 2 "on" 3 "invalid" ;
VAL_ 903 PSM_DrvStTiltUpDis 0 "default" 1 "off" 2 "on" 3 "invalid" ;
VAL_ 904 PSM_DrvReclinePosition 0 "0x0x00~0xFE:POSITION" 254 "0x0x00~0xFE:POSITION" 255 "invalid" ;
VAL_ 904 PSM_EsyAcsGetOffSta 0 "off" 1 "on" 2 "Not Used" 3 "Error Indicator" ;
VAL_ 904 PSM_EsyAcsStpSta 0 "off" 1 "on" 2 "Not Used" 3 "Error Indicator" ;
VAL_ 904 PSM_SWVerMajor1 0 "0x0x0~0x7F:ASCII Code Value (HEX)" 127 "0x0x0~0x7F:ASCII Code Value (HEX)" ;
VAL_ 904 PSM_SWVerMinor1 0 "0x0x0~0x7F:ASCII Code Value (HEX)" 127 "0x0x0~0x7F:ASCII Code Value (HEX)" ;
VAL_ 904 PSM_SWVerMinor2 0 "0x0x0~0x7F:ASCII Code Value (HEX)" 127 "0x0x0~0x7F:ASCII Code Value (HEX)" ;
VAL_ 904 PSM_HDPSpprtSWVer 0 "Requirement Spec Version" 1 "Requirement Spec Version" 2 "Requirement Spec Version" 3 "Requirement Spec Version" 4 "Requirement Spec Version" 5 "Requirement Spec Version" 6 "Requirement Spec Version" 7 "Requirement Spec Version" 8 "Requirement Spec Version" 9 "Requirement Spec Version" 10 "Requirement Spec Version" 11 "Requirement Spec Version" 12 "Requirement Spec Version" 13 "Requirement Spec Version" 14 "Requirement Spec Version" 15 "Requirement Spec Version" 16 "Requirement Spec Version" 17 "Requirement Spec Version" 18 "Requirement Spec Version" 19 "Requirement Spec Version" 20 "Requirement Spec Version" 21 "Requirement Spec Version" 22 "Requirement Spec Version" 23 "Requirement Spec Version" 24 "Requirement Spec Version" 25 "Requirement Spec Version" 26 "Requirement Spec Version" 27 "Requirement Spec Version" 28 "Requirement Spec Version" 29 "Requirement Spec Version" 30 "Requirement Spec Version" 31 "Requirement Spec Version" ;
VAL_ 904 PSM_DrvHeightPosition 0 "0x0x00~0xFE:POSITION" 254 "0x0x00~0xFE:POSITION" 255 "invalid" ;
VAL_ 904 PSM_DrvSlidePosition 0 "0x0x00~0xFE:POSITION" 254 "0x0x00~0xFE:POSITION" 255 "invalid" ;
VAL_ 904 PSM_EsyAcsGetOnSta 0 "off" 1 "on" 2 "Not Used" 3 "Error Indicator" ;
VAL_ 1004 CF_RCS_SwTyp 0 "Not Endless Dial" 1 "Endless Dial (CAN)" ;
VAL_ 1004 CF_RCS_OffRoad 0 "DEFAULT" 1 "SNOW" 2 "SAND" 3 "MUD" 4 "AUTO" ;
VAL_ 1004 CF_RCS_BtnSta 0 "OnRoad" 1 "OffRoad" ;
VAL_ 1004 CF_RCS_RotateEnd 0 "Default" 1 "Rotate End" ;
VAL_ 1004 CF_RCS_4wdLocking 0 "Off" 1 "On" ;
VAL_ 1004 RCS_Direction_SW 0 "Default" 1 "+, Right, Up, Push" 2 "-, Left, Down" 3 "Invalid" ;
VAL_ 1004 CF_RCS_DrvMod 0 "NORMAL(COMFORT)" 1 "ECO" 2 "SPORT" 3 "SMART" ;
VAL_ 1004 RCS_Mode_SW 0 "Default" 1 "Push" 2 "Invalid" 3 "RESERVED" ;
VAL_ 1004 CF_RCS_TowMode 0 "Default" 1 "Off" 2 "On" 3 "Invalid" ;
VAL_ 1003 PSM_BzrOnRLReq 0 "off" 1 "on" 2 "Not Used" 3 "Error Indicator" ;
VAL_ 1003 RLPSM_RearModeState 0 "Default" 1 "Off" 2 "Relax Mode" 3 "Return Mode" 4 "Finished" 5 "Relax Mode(rear only)" 6 "Return Mode(rear only)" 7 "Invalid" ;
VAL_ 1003 RLPSM_RrLfSldStrtSta 0 "OFF" 1 "ON(SLIDE START)" 2 "STOP" 3 "FINISH" ;
VAL_ 1003 RLPSM_OptTyp 0 "Off" 1 "Applied" 2 "Not Used" 3 "Error Indicator" ;
VAL_ 1003 RLPSM_RLStEsyAcsUSMSta 0 "Default" 1 "Off" 2 "On" 3 "Invalid" ;
VAL_ 1003 RLPSM_AllSeatPosPlyBck_Sta 0 "Default" 1 "Moving" 2 "Moving Finish" 3 "Moving Not Finish" 4 "Not Used" 5 "Not Used" 6 "Stop" 7 "Not Used" ;
VAL_ 1003 RLPSM_RLSlidePosition 0 "0x0x00~0xFE:POSITION" 254 "0x0x00~0xFE:POSITION" 255 "invalid" ;
VAL_ 1003 RLPSM_SeatPos_Sta 0 "Default" 1 "Memory1" 2 "Memory2" 3 "Memory3" 4 "Not Used" 5 "Not Used" 6 "Not Used" 7 "Any Postion" ;
VAL_ 1003 RLPSM_SeatPosSldLmt_Sta 0 "Default" 1 "Slide Fwd Limit" 2 "Slide Bwd Limit" 3 "Not Initialized" ;
VAL_ 1003 RLPSM_Enable_Sta 0 "Default" 1 "Enable" 2 "Disable_3km" 3 "Disable_Low Voltage" 4 "Not Used" 5 "Not Used" 6 "Not Used" 7 "Not Used" ;
VAL_ 1003 RLPSM_Mem1_Sta 0 "Default" 1 "Memory1" 2 "No Memory" 3 "Not used" ;
VAL_ 1003 RLPSM_Mem2_Sta 0 "Default" 1 "Memory2" 2 "No Memory" 3 "Not Used" ;
VAL_ 1003 RLPSM_Mem3_Sta 0 "Default" 1 "Memory3" 2 "No Memory" 3 "Not Used" ;
VAL_ 1003 RLPSM_LimSetSta 0 "Default" 1 "Initialized" 2 "Not Initialized" 3 "Reserved" ;
VAL_ 1005 RLPSU_FldDis 0 "default" 1 "Off" 2 "On" 3 "Invalid" ;
VAL_ 1005 RLPSU_TiltDownDis 0 "default" 1 "Off" 2 "On" 3 "Invalid" ;
VAL_ 1005 RLPSU_RclFwdDis 0 "default" 1 "Off" 2 "On" 3 "Invalid" ;
VAL_ 1005 RLPSU_RclBwdDis 0 "default" 1 "Off" 2 "On" 3 "Invalid" ;
VAL_ 1005 RLPSU_RlxModeDis 0 "default" 1 "Off" 2 "On" 3 "Invalid" ;
VAL_ 1005 RLPSU_Folding_SW 0 "default" 1 "Off" 2 "On" 3 "Invalid" ;
VAL_ 1005 RLPSU_UnFldDis 0 "default" 1 "Off" 2 "On" 3 "Invalid" ;
VAL_ 1005 RLPSU_Unfolding_SW 0 "default" 1 "Off" 2 "On" 3 "Invalid" ;
VAL_ 1005 RLPSU_WalkIn_SW 0 "default" 1 "Off" 2 "On" 3 "Invalid" ;
VAL_ 1005 RLPSU_UnwalkIn_SW 0 "default" 1 "Off" 2 "On" 3 "Invalid" ;
VAL_ 1005 RLPSU_Folding_Postion 0 "deafult" 1 "Walk In" 2 "Unwalk In" 3 "Walk In(Moving)" 4 "Unwalk In(Moving)" 5 "Folded" 6 "UnFolded" 7 "Folding (Moving)" 8 "UnFolding (Moving)" 9 "RESERVED" 10 "RESERVED" 11 "RESERVED" 12 "RESERVED" 13 "RESERVED" 14 "RESERVED" 15 "Invalid" ;
VAL_ 1005 RLPSU_Folding_State_PopUp 0 "Default" 1 "Folded(finished)" 2 "Unfolded(finished)" 3 "Mode-fail (anti-pinch)" 4 "Mode-fail (TGS&Break Condition)" 5 "Mode-fail (system error)" 6 "RESERVED" 7 "Invalid" ;
VAL_ 1005 RLPSU_Relax_State_Popup 0 "Default" 1 "Relaxed(finished)" 2 "Unrelaxed(finished)" 3 "Relax (Relaxing)" 4 "Return (Returning)" 5 "RESERVED" 6 "RESERVED" 7 "Invalid" ;
VAL_ 1005 RLPSU_SlideFwdDis 0 "default" 1 "Off" 2 "On" 3 "Invalid" ;
VAL_ 1005 RLPSU_SlideBwdDis 0 "default" 1 "Off" 2 "On" 3 "Invalid" ;
VAL_ 1005 RLPSU_WalkInDis 0 "default" 1 "Off" 2 "On" 3 "Inavlid" ;
VAL_ 1005 RLPSU_WalkInState 0 "default" 1 "Enable" 2 "Disable" 3 "Invalid" ;
VAL_ 1005 RLPSU_RLMsgEnable 0 "Off" 1 "Enable" 2 "Disable" 3 "Invalid" ;
VAL_ 1005 RLPSU_UnWalkInDis 0 "default" 1 "Off" 2 "On" 3 "Invalid" ;
VAL_ 1005 RLPSU_TiltUpDis 0 "default" 1 "Off" 2 "On" 3 "Invalid" ;
VAL_ 1006 RRPSU_FldDis 0 "default" 1 "Off" 2 "On" 3 "Invalid" ;
VAL_ 1006 RRPSU_TiltDnDis 0 "default" 1 "Off" 2 "On" 3 "Invalid" ;
VAL_ 1006 RRPSU_RecFwdDis 0 "default" 1 "Off" 2 "On" 3 "Invalid" ;
VAL_ 1006 RRPSU_RecBwdDis 0 "default" 1 "Off" 2 "On" 3 "Invalid" ;
VAL_ 1006 RRPSU_RlxModeDis 0 "default" 1 "Off" 2 "On" 3 "Invalid" ;
VAL_ 1006 RRPSU_Folding_SW 0 "default" 1 "Off" 2 "On" 3 "Invalid" ;
VAL_ 1006 RRPSU_UnFldDis 0 "default" 1 "Off" 2 "On" 3 "Invalid" ;
VAL_ 1006 RRPSU_Unfolding_SW 0 "default" 1 "Off" 2 "On" 3 "Invalid" ;
VAL_ 1006 RRPSU_WalkIn_SW 0 "default" 1 "Off" 2 "On" 3 "Invalid" ;
VAL_ 1006 RRPSU_UnwalkIn_SW 0 "default" 1 "Off" 2 "On" 3 "Invalid" ;
VAL_ 1006 RRPSU_Folding_Postion 0 "deafult" 1 "Walk In" 2 "Unwalk In" 3 "Walk In(Moving)" 4 "Unwalk In(Moving)" 5 "Folded" 6 "UnFolded" 7 "Folding (Moving)" 8 "UnFolding (Moving)" 9 "RESERVED" 10 "RESERVED" 11 "RESERVED" 12 "RESERVED" 13 "RESERVED" 14 "RESERVED" 15 "Invalid" ;
VAL_ 1006 RRPSU_Folding_State_Popup 0 "Default" 1 "Relaxed(finished)" 2 "Unfolded(finished)" 3 "Mode-fail(anti-pinch)" 4 "Mode-Fail(TGS&Break Condition)" 5 "Mode-fail(system error)" 6 "RESERVED" 7 "Invalid" ;
VAL_ 1006 RRPSU_Relax_State_Popup 0 "Default" 1 "Relaxed(finished)" 2 "UnRelaxed(finished)" 3 "Relax (Relaxing)" 4 "Return(Returning)" 5 "RESERVED" 6 "RESERVED" 7 "Invalid" ;
VAL_ 1006 RRPSU_SlideFwdDis 0 "default" 1 "Off" 2 "On" 3 "Invalid" ;
VAL_ 1006 RRPSU_SlideBwdDis 0 "default" 1 "Off" 2 "On" 3 "Invalid" ;
VAL_ 1006 RRPSU_WalkinDis 0 "default" 1 "Off" 2 "On" 3 "Invalid" ;
VAL_ 1006 RRPSU_WalkInState 0 "default" 1 "Enable" 2 "Disable" 3 "Invalid" ;
VAL_ 1006 RRPSU_RRMsgEnable 0 "Off" 1 "Enable" 2 "Disable" 3 "Invalid" ;
VAL_ 1006 RRPSU_UnwalkinDis 0 "default" 1 "Off" 2 "On" 3 "Invalid" ;
VAL_ 1006 RRPSU_TiltUpDis 0 "default" 1 "Off" 2 "On" 3 "Invalid" ;
VAL_ 905 SBCM_RR_Crc1Val 0 "0x0x0~0xFF:CRCValue" 255 "0x0x0~0xFF:CRCValue" ;
VAL_ 905 RR_CrashUnlockCmd 0 "Off" 1 "Unlock (Crash)" ;
VAL_ 905 SBCM_RR_AlvCnt1Val 0 "AlvCntValue" 1 "AlvCntValue" 2 "AlvCntValue" 3 "AlvCntValue" 4 "AlvCntValue" 5 "AlvCntValue" 6 "AlvCntValue" 7 "AlvCntValue" 8 "AlvCntValue" 9 "AlvCntValue" 10 "AlvCntValue" 11 "AlvCntValue" 12 "AlvCntValue" 13 "AlvCntValue" 14 "AlvCntValue" 15 "AlvCntValue" ;
VAL_ 905 Warn_RrRtDrSwSta_SBCM 0 "Close" 1 "Open" 2 "RESERVED" 3 "Error Indicator" ;
VAL_ 905 DoorLock_RrRtDrUnLkSta_SBCM 0 "Lock" 1 "Unlock" 2 "RESERVED" 3 "Error Indicator" ;
VAL_ 905 RR_SEAActivated 0 "InActivated" 1 "Activated" 2 "RESERVED" 3 "Error Indicator" ;
VAL_ 905 RR_SEAWarn 0 "SEA Right Warning OFF" 1 "SEA Right Warning ON" 2 "RESERVED" 3 "RESERVED" ;
VAL_ 905 RR_SEWWarn 0 "SEW Right Warning OFF" 1 "SEW Right Warning ON" 2 "RESERVED" 3 "RESERVED" ;
VAL_ 905 RR_ReleaseWarn 0 "Release Warning OFF" 1 "Release Warning ON" 2 "RESERVED" 3 "RESERVED" ;
VAL_ 905 RR_SWFailAlarm 0 "Off" 1 "On" 2 "RESERVED" 3 "Error Indicator" ;
VAL_ 905 RR_ChildLock_ActnFlSta 0 "OK" 1 "Failed" 2 "RESERVED" 3 "Error Indicator" ;
VAL_ 905 RR_MRActivationAlarm 0 "Off" 1 "On" 2 "RESERVED" 3 "Error Indicator" ;
VAL_ 905 RR_ChildLock_Status 0 "ChildLock On" 1 "ChildLock Off" 2 "RESERVED" 3 "RESERVED" ;
VAL_ 905 USM_RRGhostDoorSta 0 "Default" 1 "Off" 2 "On" 3 "RESERVED" ;
VAL_ 905 DoorLock_PDSLkSwSta_RR 0 "Lock" 1 "Unlock" 2 "RESERVED" 3 "Error Indicator" ;
VAL_ 905 PDS_TypeOption_RR 0 "Off" 1 "On" 2 "RESERVED" 3 "Error Indicator" ;
VAL_ 905 RRDoorPushAlarm 0 "Off" 1 "On" 2 "RESERVED" 3 "Error Indicator" ;
